VERSION ""

NS_ :

BS_:

BU_: CSC01 CSC02 CSC03 CSC04 CSC05 CSC06 CSC07 CSC08 CSC09 CSC10 CSC11 CSC12 CSC13 CSC14 CSC15

BO_ 2550726658 CSC09_CIDs_FAULTS: 8 CSC09
 SG_ IC4_IDLE_MODE_FLT m3 : 24|1@0+ (1,0) [0|0] "" Vector__XXX
 SG_ IC4_AN_OPEN_FLT m3 : 39|1@0+ (1,0) [0|0] "" Vector__XXX
 SG_ IC4_GPIO_SHORT_FLT m3 : 38|1@0+ (1,0) [0|0] "" Vector__XXX
 SG_ IC4_CB_SHORT_FLT m3 : 37|1@0+ (1,0) [0|0] "" Vector__XXX
 SG_ IC4_CB_OPEN_FLT m3 : 36|1@0+ (1,0) [0|0] "" Vector__XXX
 SG_ IC4_OSC_ERR_FLT m3 : 35|1@0+ (1,0) [0|0] "" Vector__XXX
 SG_ IC4_DED_ERR_FLT m3 : 34|1@0+ (1,0) [0|0] "" Vector__XXX
 SG_ IC4_FUSE_ERR_FLT m3 : 33|1@0+ (1,0) [0|0] "" Vector__XXX
 SG_ IC4_VCOM_OV_FLT m3 : 16|1@0+ (1,0) [0|0] "" Vector__XXX
 SG_ IC4_VCOM_UV_FLT m3 : 31|1@0+ (1,0) [0|0] "" Vector__XXX
 SG_ IC4_VANA_OV_FLT m3 : 30|1@0+ (1,0) [0|0] "" Vector__XXX
 SG_ IC4_VANA_UV_FLT m3 : 29|1@0+ (1,0) [0|0] "" Vector__XXX
 SG_ IC4_ADC1_B_FLT m3 : 28|1@0+ (1,0) [0|0] "" Vector__XXX
 SG_ IC4_ADC1_A_FLT m3 : 27|1@0+ (1,0) [0|0] "" Vector__XXX
 SG_ IC4_GND_LOSS_FLT m3 : 26|1@0+ (1,0) [0|0] "" Vector__XXX
 SG_ IC4_IC_TSD_FLT m3 : 25|1@0+ (1,0) [0|0] "" Vector__XXX
 SG_ IC4_GPIO0_WUP_FLT m3 : 23|1@0+ (1,0) [0|0] "" Vector__XXX
 SG_ IC4_IS_OL_FLT m3 : 22|1@0+ (1,0) [0|0] "" Vector__XXX
 SG_ IC4_IS_OC_FLT m3 : 21|1@0+ (1,0) [0|0] "" Vector__XXX
 SG_ IC4_AN_OT_FLT m3 : 20|1@0+ (1,0) [0|0] "" Vector__XXX
 SG_ IC4_AN_UT_FLT m3 : 19|1@0+ (1,0) [0|0] "" Vector__XXX
 SG_ IC4_CT_OV_FLT m3 : 18|1@0+ (1,0) [0|0] "" Vector__XXX
 SG_ IC4_CT_UV_FLT m3 : 17|1@0+ (1,0) [0|0] "" Vector__XXX
 SG_ IC4_POR m3 : 15|1@0+ (1,0) [0|0] "" Vector__XXX
 SG_ IC4_RESET_FLT m3 : 14|1@0+ (1,0) [0|0] "" Vector__XXX
 SG_ IC4_COM_ERR_OVR_FLT m3 : 13|1@0+ (1,0) [0|0] "" Vector__XXX
 SG_ IC4_VPWR_OV_FLT m3 : 12|1@0+ (1,0) [0|0] "" Vector__XXX
 SG_ IC4_VPWR_LV_FLT m3 : 11|1@0+ (1,0) [0|0] "" Vector__XXX
 SG_ IC4_COM_LOSS_FLT m3 : 10|1@0+ (1,0) [0|0] "" Vector__XXX
 SG_ IC4_COM_ERR_FLT m3 : 9|1@0+ (1,0) [0|0] "" Vector__XXX
 SG_ IC4_CSB_WUP_FLT m3 : 8|1@0+ (1,0) [0|0] "" Vector__XXX
 SG_ IC3_IDLE_MODE_FLT m2 : 24|1@0+ (1,0) [0|0] "" Vector__XXX
 SG_ IC3_AN_OPEN_FLT m2 : 39|1@0+ (1,0) [0|0] "" Vector__XXX
 SG_ IC3_GPIO_SHORT_FLT m2 : 38|1@0+ (1,0) [0|0] "" Vector__XXX
 SG_ IC3_CB_SHORT_FLT m2 : 37|1@0+ (1,0) [0|0] "" Vector__XXX
 SG_ IC3_CB_OPEN_FLT m2 : 36|1@0+ (1,0) [0|0] "" Vector__XXX
 SG_ IC3_OSC_ERR_FLT m2 : 35|1@0+ (1,0) [0|0] "" Vector__XXX
 SG_ IC3_DED_ERR_FLT m2 : 34|1@0+ (1,0) [0|0] "" Vector__XXX
 SG_ IC3_FUSE_ERR_FLT m2 : 33|1@0+ (1,0) [0|0] "" Vector__XXX
 SG_ IC3_VCOM_OV_FLT m2 : 16|1@0+ (1,0) [0|0] "" Vector__XXX
 SG_ IC3_VCOM_UV_FLT m2 : 31|1@0+ (1,0) [0|0] "" Vector__XXX
 SG_ IC3_VANA_OV_FLT m2 : 30|1@0+ (1,0) [0|0] "" Vector__XXX
 SG_ IC3_VANA_UV_FLT m2 : 29|1@0+ (1,0) [0|0] "" Vector__XXX
 SG_ IC3_ADC1_B_FLT m2 : 28|1@0+ (1,0) [0|0] "" Vector__XXX
 SG_ IC3_ADC1_A_FLT m2 : 27|1@0+ (1,0) [0|0] "" Vector__XXX
 SG_ IC3_GND_LOSS_FLT m2 : 26|1@0+ (1,0) [0|0] "" Vector__XXX
 SG_ IC3_IC_TSD_FLT m2 : 25|1@0+ (1,0) [0|0] "" Vector__XXX
 SG_ IC3_GPIO0_WUP_FLT m2 : 23|1@0+ (1,0) [0|0] "" Vector__XXX
 SG_ IC3_IS_OL_FLT m2 : 22|1@0+ (1,0) [0|0] "" Vector__XXX
 SG_ IC3_IS_OC_FLT m2 : 21|1@0+ (1,0) [0|0] "" Vector__XXX
 SG_ IC3_AN_OT_FLT m2 : 20|1@0+ (1,0) [0|0] "" Vector__XXX
 SG_ IC3_AN_UT_FLT m2 : 19|1@0+ (1,0) [0|0] "" Vector__XXX
 SG_ IC3_CT_OV_FLT m2 : 18|1@0+ (1,0) [0|0] "" Vector__XXX
 SG_ IC3_CT_UV_FLT m2 : 17|1@0+ (1,0) [0|0] "" Vector__XXX
 SG_ IC3_POR m2 : 15|1@0+ (1,0) [0|0] "" Vector__XXX
 SG_ IC3_RESET_FLT m2 : 14|1@0+ (1,0) [0|0] "" Vector__XXX
 SG_ IC3_COM_ERR_OVR_FLT m2 : 13|1@0+ (1,0) [0|0] "" Vector__XXX
 SG_ IC3_VPWR_OV_FLT m2 : 12|1@0+ (1,0) [0|0] "" Vector__XXX
 SG_ IC3_VPWR_LV_FLT m2 : 11|1@0+ (1,0) [0|0] "" Vector__XXX
 SG_ IC3_COM_LOSS_FLT m2 : 10|1@0+ (1,0) [0|0] "" Vector__XXX
 SG_ IC3_COM_ERR_FLT m2 : 9|1@0+ (1,0) [0|0] "" Vector__XXX
 SG_ IC3_CSB_WUP_FLT m2 : 8|1@0+ (1,0) [0|0] "" Vector__XXX
 SG_ IC2_IDLE_MODE_FLT m1 : 24|1@0+ (1,0) [0|0] "" Vector__XXX
 SG_ IC2_AN_OPEN_FLT m1 : 39|1@0+ (1,0) [0|0] "" Vector__XXX
 SG_ IC2_GPIO_SHORT_FLT m1 : 38|1@0+ (1,0) [0|0] "" Vector__XXX
 SG_ IC2_CB_SHORT_FLT m1 : 37|1@0+ (1,0) [0|0] "" Vector__XXX
 SG_ IC2_CB_OPEN_FLT m1 : 36|1@0+ (1,0) [0|0] "" Vector__XXX
 SG_ IC2_OSC_ERR_FLT m1 : 35|1@0+ (1,0) [0|0] "" Vector__XXX
 SG_ IC2_DED_ERR_FLT m1 : 34|1@0+ (1,0) [0|0] "" Vector__XXX
 SG_ IC2_FUSE_ERR_FLT m1 : 33|1@0+ (1,0) [0|0] "" Vector__XXX
 SG_ IC2_VCOM_OV_FLT m1 : 16|1@0+ (1,0) [0|0] "" Vector__XXX
 SG_ IC2_VCOM_UV_FLT m1 : 31|1@0+ (1,0) [0|0] "" Vector__XXX
 SG_ IC2_VANA_OV_FLT m1 : 30|1@0+ (1,0) [0|0] "" Vector__XXX
 SG_ IC2_VANA_UV_FLT m1 : 29|1@0+ (1,0) [0|0] "" Vector__XXX
 SG_ IC2_ADC1_B_FLT m1 : 28|1@0+ (1,0) [0|0] "" Vector__XXX
 SG_ IC2_ADC1_A_FLT m1 : 27|1@0+ (1,0) [0|0] "" Vector__XXX
 SG_ IC2_GND_LOSS_FLT m1 : 26|1@0+ (1,0) [0|0] "" Vector__XXX
 SG_ IC2_IC_TSD_FLT m1 : 25|1@0+ (1,0) [0|0] "" Vector__XXX
 SG_ IC2_GPIO0_WUP_FLT m1 : 23|1@0+ (1,0) [0|0] "" Vector__XXX
 SG_ IC2_IS_OL_FLT m1 : 22|1@0+ (1,0) [0|0] "" Vector__XXX
 SG_ IC2_IS_OC_FLT m1 : 21|1@0+ (1,0) [0|0] "" Vector__XXX
 SG_ IC2_AN_OT_FLT m1 : 20|1@0+ (1,0) [0|0] "" Vector__XXX
 SG_ IC2_AN_UT_FLT m1 : 19|1@0+ (1,0) [0|0] "" Vector__XXX
 SG_ IC2_CT_OV_FLT m1 : 18|1@0+ (1,0) [0|0] "" Vector__XXX
 SG_ IC2_CT_UV_FLT m1 : 17|1@0+ (1,0) [0|0] "" Vector__XXX
 SG_ IC2_POR m1 : 15|1@0+ (1,0) [0|0] "" Vector__XXX
 SG_ IC2_RESET_FLT m1 : 14|1@0+ (1,0) [0|0] "" Vector__XXX
 SG_ IC2_COM_ERR_OVR_FLT m1 : 13|1@0+ (1,0) [0|0] "" Vector__XXX
 SG_ IC2_VPWR_OV_FLT m1 : 12|1@0+ (1,0) [0|0] "" Vector__XXX
 SG_ IC2_VPWR_LV_FLT m1 : 11|1@0+ (1,0) [0|0] "" Vector__XXX
 SG_ IC2_COM_LOSS_FLT m1 : 10|1@0+ (1,0) [0|0] "" Vector__XXX
 SG_ IC2_COM_ERR_FLT m1 : 9|1@0+ (1,0) [0|0] "" Vector__XXX
 SG_ IC2_CSB_WUP_FLT m1 : 8|1@0+ (1,0) [0|0] "" Vector__XXX
 SG_ IC1_IDLE_MODE_FLT m0 : 24|1@0+ (1,0) [0|0] "" Vector__XXX
 SG_ IC1_AN_OPEN_FLT m0 : 39|1@0+ (1,0) [0|0] "" Vector__XXX
 SG_ IC1_GPIO_SHORT_FLT m0 : 38|1@0+ (1,0) [0|0] "" Vector__XXX
 SG_ IC1_CB_SHORT_FLT m0 : 37|1@0+ (1,0) [0|0] "" Vector__XXX
 SG_ IC1_CB_OPEN_FLT m0 : 36|1@0+ (1,0) [0|0] "" Vector__XXX
 SG_ IC1_OSC_ERR_FLT m0 : 35|1@0+ (1,0) [0|0] "" Vector__XXX
 SG_ IC1_DED_ERR_FLT m0 : 34|1@0+ (1,0) [0|0] "" Vector__XXX
 SG_ IC1_FUSE_ERR_FLT m0 : 33|1@0+ (1,0) [0|0] "" Vector__XXX
 SG_ IC1_VCOM_OV_FLT m0 : 16|1@0+ (1,0) [0|0] "" Vector__XXX
 SG_ IC1_VCOM_UV_FLT m0 : 31|1@0+ (1,0) [0|0] "" Vector__XXX
 SG_ IC1_VANA_OV_FLT m0 : 30|1@0+ (1,0) [0|0] "" Vector__XXX
 SG_ IC1_VANA_UV_FLT m0 : 29|1@0+ (1,0) [0|0] "" Vector__XXX
 SG_ IC1_ADC1_B_FLT m0 : 28|1@0+ (1,0) [0|0] "" Vector__XXX
 SG_ IC1_ADC1_A_FLT m0 : 27|1@0+ (1,0) [0|0] "" Vector__XXX
 SG_ IC1_GND_LOSS_FLT m0 : 26|1@0+ (1,0) [0|0] "" Vector__XXX
 SG_ IC1_IC_TSD_FLT m0 : 25|1@0+ (1,0) [0|0] "" Vector__XXX
 SG_ IC1_GPIO0_WUP_FLT m0 : 23|1@0+ (1,0) [0|0] "" Vector__XXX
 SG_ IC1_IS_OL_FLT m0 : 22|1@0+ (1,0) [0|0] "" Vector__XXX
 SG_ IC1_IS_OC_FLT m0 : 21|1@0+ (1,0) [0|0] "" Vector__XXX
 SG_ IC1_AN_OT_FLT m0 : 20|1@0+ (1,0) [0|0] "" Vector__XXX
 SG_ IC1_AN_UT_FLT m0 : 19|1@0+ (1,0) [0|0] "" Vector__XXX
 SG_ IC1_CT_OV_FLT m0 : 18|1@0+ (1,0) [0|0] "" Vector__XXX
 SG_ IC1_CT_UV_FLT m0 : 17|1@0+ (1,0) [0|0] "" Vector__XXX
 SG_ IC1_POR m0 : 15|1@0+ (1,0) [0|0] "" Vector__XXX
 SG_ IC1_RESET_FLT m0 : 14|1@0+ (1,0) [0|0] "" Vector__XXX
 SG_ IC1_COM_ERR_OVR_FLT m0 : 13|1@0+ (1,0) [0|0] "" Vector__XXX
 SG_ IC1_VPWR_OV_FLT m0 : 12|1@0+ (1,0) [0|0] "" Vector__XXX
 SG_ IC1_VPWR_LV_FLT m0 : 11|1@0+ (1,0) [0|0] "" Vector__XXX
 SG_ IC1_COM_LOSS_FLT m0 : 10|1@0+ (1,0) [0|0] "" Vector__XXX
 SG_ IC1_COM_ERR_FLT m0 : 9|1@0+ (1,0) [0|0] "" Vector__XXX
 SG_ IC1_CSB_WUP_FLT m0 : 8|1@0+ (1,0) [0|0] "" Vector__XXX
 SG_ CSC09_IndexFaults M : 7|8@0+ (1,0) [0|255] "" Vector__XXX

BO_ 2550792194 CSC10_CIDs_FAULTS: 8 CSC10
 SG_ IC4_IDLE_MODE_FLT m3 : 24|1@0+ (1,0) [0|0] "" Vector__XXX
 SG_ IC4_AN_OPEN_FLT m3 : 39|1@0+ (1,0) [0|0] "" Vector__XXX
 SG_ IC4_GPIO_SHORT_FLT m3 : 38|1@0+ (1,0) [0|0] "" Vector__XXX
 SG_ IC4_CB_SHORT_FLT m3 : 37|1@0+ (1,0) [0|0] "" Vector__XXX
 SG_ IC4_CB_OPEN_FLT m3 : 36|1@0+ (1,0) [0|0] "" Vector__XXX
 SG_ IC4_OSC_ERR_FLT m3 : 35|1@0+ (1,0) [0|0] "" Vector__XXX
 SG_ IC4_DED_ERR_FLT m3 : 34|1@0+ (1,0) [0|0] "" Vector__XXX
 SG_ IC4_FUSE_ERR_FLT m3 : 33|1@0+ (1,0) [0|0] "" Vector__XXX
 SG_ IC4_VCOM_OV_FLT m3 : 16|1@0+ (1,0) [0|0] "" Vector__XXX
 SG_ IC4_VCOM_UV_FLT m3 : 31|1@0+ (1,0) [0|0] "" Vector__XXX
 SG_ IC4_VANA_OV_FLT m3 : 30|1@0+ (1,0) [0|0] "" Vector__XXX
 SG_ IC4_VANA_UV_FLT m3 : 29|1@0+ (1,0) [0|0] "" Vector__XXX
 SG_ IC4_ADC1_B_FLT m3 : 28|1@0+ (1,0) [0|0] "" Vector__XXX
 SG_ IC4_ADC1_A_FLT m3 : 27|1@0+ (1,0) [0|0] "" Vector__XXX
 SG_ IC4_GND_LOSS_FLT m3 : 26|1@0+ (1,0) [0|0] "" Vector__XXX
 SG_ IC4_IC_TSD_FLT m3 : 25|1@0+ (1,0) [0|0] "" Vector__XXX
 SG_ IC4_GPIO0_WUP_FLT m3 : 23|1@0+ (1,0) [0|0] "" Vector__XXX
 SG_ IC4_IS_OL_FLT m3 : 22|1@0+ (1,0) [0|0] "" Vector__XXX
 SG_ IC4_IS_OC_FLT m3 : 21|1@0+ (1,0) [0|0] "" Vector__XXX
 SG_ IC4_AN_OT_FLT m3 : 20|1@0+ (1,0) [0|0] "" Vector__XXX
 SG_ IC4_AN_UT_FLT m3 : 19|1@0+ (1,0) [0|0] "" Vector__XXX
 SG_ IC4_CT_OV_FLT m3 : 18|1@0+ (1,0) [0|0] "" Vector__XXX
 SG_ IC4_CT_UV_FLT m3 : 17|1@0+ (1,0) [0|0] "" Vector__XXX
 SG_ IC4_POR m3 : 15|1@0+ (1,0) [0|0] "" Vector__XXX
 SG_ IC4_RESET_FLT m3 : 14|1@0+ (1,0) [0|0] "" Vector__XXX
 SG_ IC4_COM_ERR_OVR_FLT m3 : 13|1@0+ (1,0) [0|0] "" Vector__XXX
 SG_ IC4_VPWR_OV_FLT m3 : 12|1@0+ (1,0) [0|0] "" Vector__XXX
 SG_ IC4_VPWR_LV_FLT m3 : 11|1@0+ (1,0) [0|0] "" Vector__XXX
 SG_ IC4_COM_LOSS_FLT m3 : 10|1@0+ (1,0) [0|0] "" Vector__XXX
 SG_ IC4_COM_ERR_FLT m3 : 9|1@0+ (1,0) [0|0] "" Vector__XXX
 SG_ IC4_CSB_WUP_FLT m3 : 8|1@0+ (1,0) [0|0] "" Vector__XXX
 SG_ IC3_IDLE_MODE_FLT m2 : 24|1@0+ (1,0) [0|0] "" Vector__XXX
 SG_ IC3_AN_OPEN_FLT m2 : 39|1@0+ (1,0) [0|0] "" Vector__XXX
 SG_ IC3_GPIO_SHORT_FLT m2 : 38|1@0+ (1,0) [0|0] "" Vector__XXX
 SG_ IC3_CB_SHORT_FLT m2 : 37|1@0+ (1,0) [0|0] "" Vector__XXX
 SG_ IC3_CB_OPEN_FLT m2 : 36|1@0+ (1,0) [0|0] "" Vector__XXX
 SG_ IC3_OSC_ERR_FLT m2 : 35|1@0+ (1,0) [0|0] "" Vector__XXX
 SG_ IC3_DED_ERR_FLT m2 : 34|1@0+ (1,0) [0|0] "" Vector__XXX
 SG_ IC3_FUSE_ERR_FLT m2 : 33|1@0+ (1,0) [0|0] "" Vector__XXX
 SG_ IC3_VCOM_OV_FLT m2 : 16|1@0+ (1,0) [0|0] "" Vector__XXX
 SG_ IC3_VCOM_UV_FLT m2 : 31|1@0+ (1,0) [0|0] "" Vector__XXX
 SG_ IC3_VANA_OV_FLT m2 : 30|1@0+ (1,0) [0|0] "" Vector__XXX
 SG_ IC3_VANA_UV_FLT m2 : 29|1@0+ (1,0) [0|0] "" Vector__XXX
 SG_ IC3_ADC1_B_FLT m2 : 28|1@0+ (1,0) [0|0] "" Vector__XXX
 SG_ IC3_ADC1_A_FLT m2 : 27|1@0+ (1,0) [0|0] "" Vector__XXX
 SG_ IC3_GND_LOSS_FLT m2 : 26|1@0+ (1,0) [0|0] "" Vector__XXX
 SG_ IC3_IC_TSD_FLT m2 : 25|1@0+ (1,0) [0|0] "" Vector__XXX
 SG_ IC3_GPIO0_WUP_FLT m2 : 23|1@0+ (1,0) [0|0] "" Vector__XXX
 SG_ IC3_IS_OL_FLT m2 : 22|1@0+ (1,0) [0|0] "" Vector__XXX
 SG_ IC3_IS_OC_FLT m2 : 21|1@0+ (1,0) [0|0] "" Vector__XXX
 SG_ IC3_AN_OT_FLT m2 : 20|1@0+ (1,0) [0|0] "" Vector__XXX
 SG_ IC3_AN_UT_FLT m2 : 19|1@0+ (1,0) [0|0] "" Vector__XXX
 SG_ IC3_CT_OV_FLT m2 : 18|1@0+ (1,0) [0|0] "" Vector__XXX
 SG_ IC3_CT_UV_FLT m2 : 17|1@0+ (1,0) [0|0] "" Vector__XXX
 SG_ IC3_POR m2 : 15|1@0+ (1,0) [0|0] "" Vector__XXX
 SG_ IC3_RESET_FLT m2 : 14|1@0+ (1,0) [0|0] "" Vector__XXX
 SG_ IC3_COM_ERR_OVR_FLT m2 : 13|1@0+ (1,0) [0|0] "" Vector__XXX
 SG_ IC3_VPWR_OV_FLT m2 : 12|1@0+ (1,0) [0|0] "" Vector__XXX
 SG_ IC3_VPWR_LV_FLT m2 : 11|1@0+ (1,0) [0|0] "" Vector__XXX
 SG_ IC3_COM_LOSS_FLT m2 : 10|1@0+ (1,0) [0|0] "" Vector__XXX
 SG_ IC3_COM_ERR_FLT m2 : 9|1@0+ (1,0) [0|0] "" Vector__XXX
 SG_ IC3_CSB_WUP_FLT m2 : 8|1@0+ (1,0) [0|0] "" Vector__XXX
 SG_ IC2_IDLE_MODE_FLT m1 : 24|1@0+ (1,0) [0|0] "" Vector__XXX
 SG_ IC2_AN_OPEN_FLT m1 : 39|1@0+ (1,0) [0|0] "" Vector__XXX
 SG_ IC2_GPIO_SHORT_FLT m1 : 38|1@0+ (1,0) [0|0] "" Vector__XXX
 SG_ IC2_CB_SHORT_FLT m1 : 37|1@0+ (1,0) [0|0] "" Vector__XXX
 SG_ IC2_CB_OPEN_FLT m1 : 36|1@0+ (1,0) [0|0] "" Vector__XXX
 SG_ IC2_OSC_ERR_FLT m1 : 35|1@0+ (1,0) [0|0] "" Vector__XXX
 SG_ IC2_DED_ERR_FLT m1 : 34|1@0+ (1,0) [0|0] "" Vector__XXX
 SG_ IC2_FUSE_ERR_FLT m1 : 33|1@0+ (1,0) [0|0] "" Vector__XXX
 SG_ IC2_VCOM_OV_FLT m1 : 16|1@0+ (1,0) [0|0] "" Vector__XXX
 SG_ IC2_VCOM_UV_FLT m1 : 31|1@0+ (1,0) [0|0] "" Vector__XXX
 SG_ IC2_VANA_OV_FLT m1 : 30|1@0+ (1,0) [0|0] "" Vector__XXX
 SG_ IC2_VANA_UV_FLT m1 : 29|1@0+ (1,0) [0|0] "" Vector__XXX
 SG_ IC2_ADC1_B_FLT m1 : 28|1@0+ (1,0) [0|0] "" Vector__XXX
 SG_ IC2_ADC1_A_FLT m1 : 27|1@0+ (1,0) [0|0] "" Vector__XXX
 SG_ IC2_GND_LOSS_FLT m1 : 26|1@0+ (1,0) [0|0] "" Vector__XXX
 SG_ IC2_IC_TSD_FLT m1 : 25|1@0+ (1,0) [0|0] "" Vector__XXX
 SG_ IC2_GPIO0_WUP_FLT m1 : 23|1@0+ (1,0) [0|0] "" Vector__XXX
 SG_ IC2_IS_OL_FLT m1 : 22|1@0+ (1,0) [0|0] "" Vector__XXX
 SG_ IC2_IS_OC_FLT m1 : 21|1@0+ (1,0) [0|0] "" Vector__XXX
 SG_ IC2_AN_OT_FLT m1 : 20|1@0+ (1,0) [0|0] "" Vector__XXX
 SG_ IC2_AN_UT_FLT m1 : 19|1@0+ (1,0) [0|0] "" Vector__XXX
 SG_ IC2_CT_OV_FLT m1 : 18|1@0+ (1,0) [0|0] "" Vector__XXX
 SG_ IC2_CT_UV_FLT m1 : 17|1@0+ (1,0) [0|0] "" Vector__XXX
 SG_ IC2_POR m1 : 15|1@0+ (1,0) [0|0] "" Vector__XXX
 SG_ IC2_RESET_FLT m1 : 14|1@0+ (1,0) [0|0] "" Vector__XXX
 SG_ IC2_COM_ERR_OVR_FLT m1 : 13|1@0+ (1,0) [0|0] "" Vector__XXX
 SG_ IC2_VPWR_OV_FLT m1 : 12|1@0+ (1,0) [0|0] "" Vector__XXX
 SG_ IC2_VPWR_LV_FLT m1 : 11|1@0+ (1,0) [0|0] "" Vector__XXX
 SG_ IC2_COM_LOSS_FLT m1 : 10|1@0+ (1,0) [0|0] "" Vector__XXX
 SG_ IC2_COM_ERR_FLT m1 : 9|1@0+ (1,0) [0|0] "" Vector__XXX
 SG_ IC2_CSB_WUP_FLT m1 : 8|1@0+ (1,0) [0|0] "" Vector__XXX
 SG_ IC1_IDLE_MODE_FLT m0 : 24|1@0+ (1,0) [0|0] "" Vector__XXX
 SG_ IC1_AN_OPEN_FLT m0 : 39|1@0+ (1,0) [0|0] "" Vector__XXX
 SG_ IC1_GPIO_SHORT_FLT m0 : 38|1@0+ (1,0) [0|0] "" Vector__XXX
 SG_ IC1_CB_SHORT_FLT m0 : 37|1@0+ (1,0) [0|0] "" Vector__XXX
 SG_ IC1_CB_OPEN_FLT m0 : 36|1@0+ (1,0) [0|0] "" Vector__XXX
 SG_ IC1_OSC_ERR_FLT m0 : 35|1@0+ (1,0) [0|0] "" Vector__XXX
 SG_ IC1_DED_ERR_FLT m0 : 34|1@0+ (1,0) [0|0] "" Vector__XXX
 SG_ IC1_FUSE_ERR_FLT m0 : 33|1@0+ (1,0) [0|0] "" Vector__XXX
 SG_ IC1_VCOM_OV_FLT m0 : 16|1@0+ (1,0) [0|0] "" Vector__XXX
 SG_ IC1_VCOM_UV_FLT m0 : 31|1@0+ (1,0) [0|0] "" Vector__XXX
 SG_ IC1_VANA_OV_FLT m0 : 30|1@0+ (1,0) [0|0] "" Vector__XXX
 SG_ IC1_VANA_UV_FLT m0 : 29|1@0+ (1,0) [0|0] "" Vector__XXX
 SG_ IC1_ADC1_B_FLT m0 : 28|1@0+ (1,0) [0|0] "" Vector__XXX
 SG_ IC1_ADC1_A_FLT m0 : 27|1@0+ (1,0) [0|0] "" Vector__XXX
 SG_ IC1_GND_LOSS_FLT m0 : 26|1@0+ (1,0) [0|0] "" Vector__XXX
 SG_ IC1_IC_TSD_FLT m0 : 25|1@0+ (1,0) [0|0] "" Vector__XXX
 SG_ IC1_GPIO0_WUP_FLT m0 : 23|1@0+ (1,0) [0|0] "" Vector__XXX
 SG_ IC1_IS_OL_FLT m0 : 22|1@0+ (1,0) [0|0] "" Vector__XXX
 SG_ IC1_IS_OC_FLT m0 : 21|1@0+ (1,0) [0|0] "" Vector__XXX
 SG_ IC1_AN_OT_FLT m0 : 20|1@0+ (1,0) [0|0] "" Vector__XXX
 SG_ IC1_AN_UT_FLT m0 : 19|1@0+ (1,0) [0|0] "" Vector__XXX
 SG_ IC1_CT_OV_FLT m0 : 18|1@0+ (1,0) [0|0] "" Vector__XXX
 SG_ IC1_CT_UV_FLT m0 : 17|1@0+ (1,0) [0|0] "" Vector__XXX
 SG_ IC1_POR m0 : 15|1@0+ (1,0) [0|0] "" Vector__XXX
 SG_ IC1_RESET_FLT m0 : 14|1@0+ (1,0) [0|0] "" Vector__XXX
 SG_ IC1_COM_ERR_OVR_FLT m0 : 13|1@0+ (1,0) [0|0] "" Vector__XXX
 SG_ IC1_VPWR_OV_FLT m0 : 12|1@0+ (1,0) [0|0] "" Vector__XXX
 SG_ IC1_VPWR_LV_FLT m0 : 11|1@0+ (1,0) [0|0] "" Vector__XXX
 SG_ IC1_COM_LOSS_FLT m0 : 10|1@0+ (1,0) [0|0] "" Vector__XXX
 SG_ IC1_COM_ERR_FLT m0 : 9|1@0+ (1,0) [0|0] "" Vector__XXX
 SG_ IC1_CSB_WUP_FLT m0 : 8|1@0+ (1,0) [0|0] "" Vector__XXX
 SG_ CSC10_IndexFaults M : 7|8@0+ (1,0) [0|255] "" Vector__XXX

BO_ 2550857730 CSC11_CIDs_FAULTS: 8 CSC11
 SG_ IC4_IDLE_MODE_FLT m3 : 24|1@0+ (1,0) [0|0] "" Vector__XXX
 SG_ IC4_AN_OPEN_FLT m3 : 39|1@0+ (1,0) [0|0] "" Vector__XXX
 SG_ IC4_GPIO_SHORT_FLT m3 : 38|1@0+ (1,0) [0|0] "" Vector__XXX
 SG_ IC4_CB_SHORT_FLT m3 : 37|1@0+ (1,0) [0|0] "" Vector__XXX
 SG_ IC4_CB_OPEN_FLT m3 : 36|1@0+ (1,0) [0|0] "" Vector__XXX
 SG_ IC4_OSC_ERR_FLT m3 : 35|1@0+ (1,0) [0|0] "" Vector__XXX
 SG_ IC4_DED_ERR_FLT m3 : 34|1@0+ (1,0) [0|0] "" Vector__XXX
 SG_ IC4_FUSE_ERR_FLT m3 : 33|1@0+ (1,0) [0|0] "" Vector__XXX
 SG_ IC4_VCOM_OV_FLT m3 : 16|1@0+ (1,0) [0|0] "" Vector__XXX
 SG_ IC4_VCOM_UV_FLT m3 : 31|1@0+ (1,0) [0|0] "" Vector__XXX
 SG_ IC4_VANA_OV_FLT m3 : 30|1@0+ (1,0) [0|0] "" Vector__XXX
 SG_ IC4_VANA_UV_FLT m3 : 29|1@0+ (1,0) [0|0] "" Vector__XXX
 SG_ IC4_ADC1_B_FLT m3 : 28|1@0+ (1,0) [0|0] "" Vector__XXX
 SG_ IC4_ADC1_A_FLT m3 : 27|1@0+ (1,0) [0|0] "" Vector__XXX
 SG_ IC4_GND_LOSS_FLT m3 : 26|1@0+ (1,0) [0|0] "" Vector__XXX
 SG_ IC4_IC_TSD_FLT m3 : 25|1@0+ (1,0) [0|0] "" Vector__XXX
 SG_ IC4_GPIO0_WUP_FLT m3 : 23|1@0+ (1,0) [0|0] "" Vector__XXX
 SG_ IC4_IS_OL_FLT m3 : 22|1@0+ (1,0) [0|0] "" Vector__XXX
 SG_ IC4_IS_OC_FLT m3 : 21|1@0+ (1,0) [0|0] "" Vector__XXX
 SG_ IC4_AN_OT_FLT m3 : 20|1@0+ (1,0) [0|0] "" Vector__XXX
 SG_ IC4_AN_UT_FLT m3 : 19|1@0+ (1,0) [0|0] "" Vector__XXX
 SG_ IC4_CT_OV_FLT m3 : 18|1@0+ (1,0) [0|0] "" Vector__XXX
 SG_ IC4_CT_UV_FLT m3 : 17|1@0+ (1,0) [0|0] "" Vector__XXX
 SG_ IC4_POR m3 : 15|1@0+ (1,0) [0|0] "" Vector__XXX
 SG_ IC4_RESET_FLT m3 : 14|1@0+ (1,0) [0|0] "" Vector__XXX
 SG_ IC4_COM_ERR_OVR_FLT m3 : 13|1@0+ (1,0) [0|0] "" Vector__XXX
 SG_ IC4_VPWR_OV_FLT m3 : 12|1@0+ (1,0) [0|0] "" Vector__XXX
 SG_ IC4_VPWR_LV_FLT m3 : 11|1@0+ (1,0) [0|0] "" Vector__XXX
 SG_ IC4_COM_LOSS_FLT m3 : 10|1@0+ (1,0) [0|0] "" Vector__XXX
 SG_ IC4_COM_ERR_FLT m3 : 9|1@0+ (1,0) [0|0] "" Vector__XXX
 SG_ IC4_CSB_WUP_FLT m3 : 8|1@0+ (1,0) [0|0] "" Vector__XXX
 SG_ IC3_IDLE_MODE_FLT m2 : 24|1@0+ (1,0) [0|0] "" Vector__XXX
 SG_ IC3_AN_OPEN_FLT m2 : 39|1@0+ (1,0) [0|0] "" Vector__XXX
 SG_ IC3_GPIO_SHORT_FLT m2 : 38|1@0+ (1,0) [0|0] "" Vector__XXX
 SG_ IC3_CB_SHORT_FLT m2 : 37|1@0+ (1,0) [0|0] "" Vector__XXX
 SG_ IC3_CB_OPEN_FLT m2 : 36|1@0+ (1,0) [0|0] "" Vector__XXX
 SG_ IC3_OSC_ERR_FLT m2 : 35|1@0+ (1,0) [0|0] "" Vector__XXX
 SG_ IC3_DED_ERR_FLT m2 : 34|1@0+ (1,0) [0|0] "" Vector__XXX
 SG_ IC3_FUSE_ERR_FLT m2 : 33|1@0+ (1,0) [0|0] "" Vector__XXX
 SG_ IC3_VCOM_OV_FLT m2 : 16|1@0+ (1,0) [0|0] "" Vector__XXX
 SG_ IC3_VCOM_UV_FLT m2 : 31|1@0+ (1,0) [0|0] "" Vector__XXX
 SG_ IC3_VANA_OV_FLT m2 : 30|1@0+ (1,0) [0|0] "" Vector__XXX
 SG_ IC3_VANA_UV_FLT m2 : 29|1@0+ (1,0) [0|0] "" Vector__XXX
 SG_ IC3_ADC1_B_FLT m2 : 28|1@0+ (1,0) [0|0] "" Vector__XXX
 SG_ IC3_ADC1_A_FLT m2 : 27|1@0+ (1,0) [0|0] "" Vector__XXX
 SG_ IC3_GND_LOSS_FLT m2 : 26|1@0+ (1,0) [0|0] "" Vector__XXX
 SG_ IC3_IC_TSD_FLT m2 : 25|1@0+ (1,0) [0|0] "" Vector__XXX
 SG_ IC3_GPIO0_WUP_FLT m2 : 23|1@0+ (1,0) [0|0] "" Vector__XXX
 SG_ IC3_IS_OL_FLT m2 : 22|1@0+ (1,0) [0|0] "" Vector__XXX
 SG_ IC3_IS_OC_FLT m2 : 21|1@0+ (1,0) [0|0] "" Vector__XXX
 SG_ IC3_AN_OT_FLT m2 : 20|1@0+ (1,0) [0|0] "" Vector__XXX
 SG_ IC3_AN_UT_FLT m2 : 19|1@0+ (1,0) [0|0] "" Vector__XXX
 SG_ IC3_CT_OV_FLT m2 : 18|1@0+ (1,0) [0|0] "" Vector__XXX
 SG_ IC3_CT_UV_FLT m2 : 17|1@0+ (1,0) [0|0] "" Vector__XXX
 SG_ IC3_POR m2 : 15|1@0+ (1,0) [0|0] "" Vector__XXX
 SG_ IC3_RESET_FLT m2 : 14|1@0+ (1,0) [0|0] "" Vector__XXX
 SG_ IC3_COM_ERR_OVR_FLT m2 : 13|1@0+ (1,0) [0|0] "" Vector__XXX
 SG_ IC3_VPWR_OV_FLT m2 : 12|1@0+ (1,0) [0|0] "" Vector__XXX
 SG_ IC3_VPWR_LV_FLT m2 : 11|1@0+ (1,0) [0|0] "" Vector__XXX
 SG_ IC3_COM_LOSS_FLT m2 : 10|1@0+ (1,0) [0|0] "" Vector__XXX
 SG_ IC3_COM_ERR_FLT m2 : 9|1@0+ (1,0) [0|0] "" Vector__XXX
 SG_ IC3_CSB_WUP_FLT m2 : 8|1@0+ (1,0) [0|0] "" Vector__XXX
 SG_ IC2_IDLE_MODE_FLT m1 : 24|1@0+ (1,0) [0|0] "" Vector__XXX
 SG_ IC2_AN_OPEN_FLT m1 : 39|1@0+ (1,0) [0|0] "" Vector__XXX
 SG_ IC2_GPIO_SHORT_FLT m1 : 38|1@0+ (1,0) [0|0] "" Vector__XXX
 SG_ IC2_CB_SHORT_FLT m1 : 37|1@0+ (1,0) [0|0] "" Vector__XXX
 SG_ IC2_CB_OPEN_FLT m1 : 36|1@0+ (1,0) [0|0] "" Vector__XXX
 SG_ IC2_OSC_ERR_FLT m1 : 35|1@0+ (1,0) [0|0] "" Vector__XXX
 SG_ IC2_DED_ERR_FLT m1 : 34|1@0+ (1,0) [0|0] "" Vector__XXX
 SG_ IC2_FUSE_ERR_FLT m1 : 33|1@0+ (1,0) [0|0] "" Vector__XXX
 SG_ IC2_VCOM_OV_FLT m1 : 16|1@0+ (1,0) [0|0] "" Vector__XXX
 SG_ IC2_VCOM_UV_FLT m1 : 31|1@0+ (1,0) [0|0] "" Vector__XXX
 SG_ IC2_VANA_OV_FLT m1 : 30|1@0+ (1,0) [0|0] "" Vector__XXX
 SG_ IC2_VANA_UV_FLT m1 : 29|1@0+ (1,0) [0|0] "" Vector__XXX
 SG_ IC2_ADC1_B_FLT m1 : 28|1@0+ (1,0) [0|0] "" Vector__XXX
 SG_ IC2_ADC1_A_FLT m1 : 27|1@0+ (1,0) [0|0] "" Vector__XXX
 SG_ IC2_GND_LOSS_FLT m1 : 26|1@0+ (1,0) [0|0] "" Vector__XXX
 SG_ IC2_IC_TSD_FLT m1 : 25|1@0+ (1,0) [0|0] "" Vector__XXX
 SG_ IC2_GPIO0_WUP_FLT m1 : 23|1@0+ (1,0) [0|0] "" Vector__XXX
 SG_ IC2_IS_OL_FLT m1 : 22|1@0+ (1,0) [0|0] "" Vector__XXX
 SG_ IC2_IS_OC_FLT m1 : 21|1@0+ (1,0) [0|0] "" Vector__XXX
 SG_ IC2_AN_OT_FLT m1 : 20|1@0+ (1,0) [0|0] "" Vector__XXX
 SG_ IC2_AN_UT_FLT m1 : 19|1@0+ (1,0) [0|0] "" Vector__XXX
 SG_ IC2_CT_OV_FLT m1 : 18|1@0+ (1,0) [0|0] "" Vector__XXX
 SG_ IC2_CT_UV_FLT m1 : 17|1@0+ (1,0) [0|0] "" Vector__XXX
 SG_ IC2_POR m1 : 15|1@0+ (1,0) [0|0] "" Vector__XXX
 SG_ IC2_RESET_FLT m1 : 14|1@0+ (1,0) [0|0] "" Vector__XXX
 SG_ IC2_COM_ERR_OVR_FLT m1 : 13|1@0+ (1,0) [0|0] "" Vector__XXX
 SG_ IC2_VPWR_OV_FLT m1 : 12|1@0+ (1,0) [0|0] "" Vector__XXX
 SG_ IC2_VPWR_LV_FLT m1 : 11|1@0+ (1,0) [0|0] "" Vector__XXX
 SG_ IC2_COM_LOSS_FLT m1 : 10|1@0+ (1,0) [0|0] "" Vector__XXX
 SG_ IC2_COM_ERR_FLT m1 : 9|1@0+ (1,0) [0|0] "" Vector__XXX
 SG_ IC2_CSB_WUP_FLT m1 : 8|1@0+ (1,0) [0|0] "" Vector__XXX
 SG_ IC1_IDLE_MODE_FLT m0 : 24|1@0+ (1,0) [0|0] "" Vector__XXX
 SG_ IC1_AN_OPEN_FLT m0 : 39|1@0+ (1,0) [0|0] "" Vector__XXX
 SG_ IC1_GPIO_SHORT_FLT m0 : 38|1@0+ (1,0) [0|0] "" Vector__XXX
 SG_ IC1_CB_SHORT_FLT m0 : 37|1@0+ (1,0) [0|0] "" Vector__XXX
 SG_ IC1_CB_OPEN_FLT m0 : 36|1@0+ (1,0) [0|0] "" Vector__XXX
 SG_ IC1_OSC_ERR_FLT m0 : 35|1@0+ (1,0) [0|0] "" Vector__XXX
 SG_ IC1_DED_ERR_FLT m0 : 34|1@0+ (1,0) [0|0] "" Vector__XXX
 SG_ IC1_FUSE_ERR_FLT m0 : 33|1@0+ (1,0) [0|0] "" Vector__XXX
 SG_ IC1_VCOM_OV_FLT m0 : 16|1@0+ (1,0) [0|0] "" Vector__XXX
 SG_ IC1_VCOM_UV_FLT m0 : 31|1@0+ (1,0) [0|0] "" Vector__XXX
 SG_ IC1_VANA_OV_FLT m0 : 30|1@0+ (1,0) [0|0] "" Vector__XXX
 SG_ IC1_VANA_UV_FLT m0 : 29|1@0+ (1,0) [0|0] "" Vector__XXX
 SG_ IC1_ADC1_B_FLT m0 : 28|1@0+ (1,0) [0|0] "" Vector__XXX
 SG_ IC1_ADC1_A_FLT m0 : 27|1@0+ (1,0) [0|0] "" Vector__XXX
 SG_ IC1_GND_LOSS_FLT m0 : 26|1@0+ (1,0) [0|0] "" Vector__XXX
 SG_ IC1_IC_TSD_FLT m0 : 25|1@0+ (1,0) [0|0] "" Vector__XXX
 SG_ IC1_GPIO0_WUP_FLT m0 : 23|1@0+ (1,0) [0|0] "" Vector__XXX
 SG_ IC1_IS_OL_FLT m0 : 22|1@0+ (1,0) [0|0] "" Vector__XXX
 SG_ IC1_IS_OC_FLT m0 : 21|1@0+ (1,0) [0|0] "" Vector__XXX
 SG_ IC1_AN_OT_FLT m0 : 20|1@0+ (1,0) [0|0] "" Vector__XXX
 SG_ IC1_AN_UT_FLT m0 : 19|1@0+ (1,0) [0|0] "" Vector__XXX
 SG_ IC1_CT_OV_FLT m0 : 18|1@0+ (1,0) [0|0] "" Vector__XXX
 SG_ IC1_CT_UV_FLT m0 : 17|1@0+ (1,0) [0|0] "" Vector__XXX
 SG_ IC1_POR m0 : 15|1@0+ (1,0) [0|0] "" Vector__XXX
 SG_ IC1_RESET_FLT m0 : 14|1@0+ (1,0) [0|0] "" Vector__XXX
 SG_ IC1_COM_ERR_OVR_FLT m0 : 13|1@0+ (1,0) [0|0] "" Vector__XXX
 SG_ IC1_VPWR_OV_FLT m0 : 12|1@0+ (1,0) [0|0] "" Vector__XXX
 SG_ IC1_VPWR_LV_FLT m0 : 11|1@0+ (1,0) [0|0] "" Vector__XXX
 SG_ IC1_COM_LOSS_FLT m0 : 10|1@0+ (1,0) [0|0] "" Vector__XXX
 SG_ IC1_COM_ERR_FLT m0 : 9|1@0+ (1,0) [0|0] "" Vector__XXX
 SG_ IC1_CSB_WUP_FLT m0 : 8|1@0+ (1,0) [0|0] "" Vector__XXX
 SG_ CSC11_IndexFaults M : 7|8@0+ (1,0) [0|255] "" Vector__XXX

BO_ 2550923266 CSC12_CIDs_FAULTS: 8 CSC12
 SG_ IC4_IDLE_MODE_FLT m3 : 24|1@0+ (1,0) [0|0] "" Vector__XXX
 SG_ IC4_AN_OPEN_FLT m3 : 39|1@0+ (1,0) [0|0] "" Vector__XXX
 SG_ IC4_GPIO_SHORT_FLT m3 : 38|1@0+ (1,0) [0|0] "" Vector__XXX
 SG_ IC4_CB_SHORT_FLT m3 : 37|1@0+ (1,0) [0|0] "" Vector__XXX
 SG_ IC4_CB_OPEN_FLT m3 : 36|1@0+ (1,0) [0|0] "" Vector__XXX
 SG_ IC4_OSC_ERR_FLT m3 : 35|1@0+ (1,0) [0|0] "" Vector__XXX
 SG_ IC4_DED_ERR_FLT m3 : 34|1@0+ (1,0) [0|0] "" Vector__XXX
 SG_ IC4_FUSE_ERR_FLT m3 : 33|1@0+ (1,0) [0|0] "" Vector__XXX
 SG_ IC4_VCOM_OV_FLT m3 : 16|1@0+ (1,0) [0|0] "" Vector__XXX
 SG_ IC4_VCOM_UV_FLT m3 : 31|1@0+ (1,0) [0|0] "" Vector__XXX
 SG_ IC4_VANA_OV_FLT m3 : 30|1@0+ (1,0) [0|0] "" Vector__XXX
 SG_ IC4_VANA_UV_FLT m3 : 29|1@0+ (1,0) [0|0] "" Vector__XXX
 SG_ IC4_ADC1_B_FLT m3 : 28|1@0+ (1,0) [0|0] "" Vector__XXX
 SG_ IC4_ADC1_A_FLT m3 : 27|1@0+ (1,0) [0|0] "" Vector__XXX
 SG_ IC4_GND_LOSS_FLT m3 : 26|1@0+ (1,0) [0|0] "" Vector__XXX
 SG_ IC4_IC_TSD_FLT m3 : 25|1@0+ (1,0) [0|0] "" Vector__XXX
 SG_ IC4_GPIO0_WUP_FLT m3 : 23|1@0+ (1,0) [0|0] "" Vector__XXX
 SG_ IC4_IS_OL_FLT m3 : 22|1@0+ (1,0) [0|0] "" Vector__XXX
 SG_ IC4_IS_OC_FLT m3 : 21|1@0+ (1,0) [0|0] "" Vector__XXX
 SG_ IC4_AN_OT_FLT m3 : 20|1@0+ (1,0) [0|0] "" Vector__XXX
 SG_ IC4_AN_UT_FLT m3 : 19|1@0+ (1,0) [0|0] "" Vector__XXX
 SG_ IC4_CT_OV_FLT m3 : 18|1@0+ (1,0) [0|0] "" Vector__XXX
 SG_ IC4_CT_UV_FLT m3 : 17|1@0+ (1,0) [0|0] "" Vector__XXX
 SG_ IC4_POR m3 : 15|1@0+ (1,0) [0|0] "" Vector__XXX
 SG_ IC4_RESET_FLT m3 : 14|1@0+ (1,0) [0|0] "" Vector__XXX
 SG_ IC4_COM_ERR_OVR_FLT m3 : 13|1@0+ (1,0) [0|0] "" Vector__XXX
 SG_ IC4_VPWR_OV_FLT m3 : 12|1@0+ (1,0) [0|0] "" Vector__XXX
 SG_ IC4_VPWR_LV_FLT m3 : 11|1@0+ (1,0) [0|0] "" Vector__XXX
 SG_ IC4_COM_LOSS_FLT m3 : 10|1@0+ (1,0) [0|0] "" Vector__XXX
 SG_ IC4_COM_ERR_FLT m3 : 9|1@0+ (1,0) [0|0] "" Vector__XXX
 SG_ IC4_CSB_WUP_FLT m3 : 8|1@0+ (1,0) [0|0] "" Vector__XXX
 SG_ IC3_IDLE_MODE_FLT m2 : 24|1@0+ (1,0) [0|0] "" Vector__XXX
 SG_ IC3_AN_OPEN_FLT m2 : 39|1@0+ (1,0) [0|0] "" Vector__XXX
 SG_ IC3_GPIO_SHORT_FLT m2 : 38|1@0+ (1,0) [0|0] "" Vector__XXX
 SG_ IC3_CB_SHORT_FLT m2 : 37|1@0+ (1,0) [0|0] "" Vector__XXX
 SG_ IC3_CB_OPEN_FLT m2 : 36|1@0+ (1,0) [0|0] "" Vector__XXX
 SG_ IC3_OSC_ERR_FLT m2 : 35|1@0+ (1,0) [0|0] "" Vector__XXX
 SG_ IC3_DED_ERR_FLT m2 : 34|1@0+ (1,0) [0|0] "" Vector__XXX
 SG_ IC3_FUSE_ERR_FLT m2 : 33|1@0+ (1,0) [0|0] "" Vector__XXX
 SG_ IC3_VCOM_OV_FLT m2 : 16|1@0+ (1,0) [0|0] "" Vector__XXX
 SG_ IC3_VCOM_UV_FLT m2 : 31|1@0+ (1,0) [0|0] "" Vector__XXX
 SG_ IC3_VANA_OV_FLT m2 : 30|1@0+ (1,0) [0|0] "" Vector__XXX
 SG_ IC3_VANA_UV_FLT m2 : 29|1@0+ (1,0) [0|0] "" Vector__XXX
 SG_ IC3_ADC1_B_FLT m2 : 28|1@0+ (1,0) [0|0] "" Vector__XXX
 SG_ IC3_ADC1_A_FLT m2 : 27|1@0+ (1,0) [0|0] "" Vector__XXX
 SG_ IC3_GND_LOSS_FLT m2 : 26|1@0+ (1,0) [0|0] "" Vector__XXX
 SG_ IC3_IC_TSD_FLT m2 : 25|1@0+ (1,0) [0|0] "" Vector__XXX
 SG_ IC3_GPIO0_WUP_FLT m2 : 23|1@0+ (1,0) [0|0] "" Vector__XXX
 SG_ IC3_IS_OL_FLT m2 : 22|1@0+ (1,0) [0|0] "" Vector__XXX
 SG_ IC3_IS_OC_FLT m2 : 21|1@0+ (1,0) [0|0] "" Vector__XXX
 SG_ IC3_AN_OT_FLT m2 : 20|1@0+ (1,0) [0|0] "" Vector__XXX
 SG_ IC3_AN_UT_FLT m2 : 19|1@0+ (1,0) [0|0] "" Vector__XXX
 SG_ IC3_CT_OV_FLT m2 : 18|1@0+ (1,0) [0|0] "" Vector__XXX
 SG_ IC3_CT_UV_FLT m2 : 17|1@0+ (1,0) [0|0] "" Vector__XXX
 SG_ IC3_POR m2 : 15|1@0+ (1,0) [0|0] "" Vector__XXX
 SG_ IC3_RESET_FLT m2 : 14|1@0+ (1,0) [0|0] "" Vector__XXX
 SG_ IC3_COM_ERR_OVR_FLT m2 : 13|1@0+ (1,0) [0|0] "" Vector__XXX
 SG_ IC3_VPWR_OV_FLT m2 : 12|1@0+ (1,0) [0|0] "" Vector__XXX
 SG_ IC3_VPWR_LV_FLT m2 : 11|1@0+ (1,0) [0|0] "" Vector__XXX
 SG_ IC3_COM_LOSS_FLT m2 : 10|1@0+ (1,0) [0|0] "" Vector__XXX
 SG_ IC3_COM_ERR_FLT m2 : 9|1@0+ (1,0) [0|0] "" Vector__XXX
 SG_ IC3_CSB_WUP_FLT m2 : 8|1@0+ (1,0) [0|0] "" Vector__XXX
 SG_ IC2_IDLE_MODE_FLT m1 : 24|1@0+ (1,0) [0|0] "" Vector__XXX
 SG_ IC2_AN_OPEN_FLT m1 : 39|1@0+ (1,0) [0|0] "" Vector__XXX
 SG_ IC2_GPIO_SHORT_FLT m1 : 38|1@0+ (1,0) [0|0] "" Vector__XXX
 SG_ IC2_CB_SHORT_FLT m1 : 37|1@0+ (1,0) [0|0] "" Vector__XXX
 SG_ IC2_CB_OPEN_FLT m1 : 36|1@0+ (1,0) [0|0] "" Vector__XXX
 SG_ IC2_OSC_ERR_FLT m1 : 35|1@0+ (1,0) [0|0] "" Vector__XXX
 SG_ IC2_DED_ERR_FLT m1 : 34|1@0+ (1,0) [0|0] "" Vector__XXX
 SG_ IC2_FUSE_ERR_FLT m1 : 33|1@0+ (1,0) [0|0] "" Vector__XXX
 SG_ IC2_VCOM_OV_FLT m1 : 16|1@0+ (1,0) [0|0] "" Vector__XXX
 SG_ IC2_VCOM_UV_FLT m1 : 31|1@0+ (1,0) [0|0] "" Vector__XXX
 SG_ IC2_VANA_OV_FLT m1 : 30|1@0+ (1,0) [0|0] "" Vector__XXX
 SG_ IC2_VANA_UV_FLT m1 : 29|1@0+ (1,0) [0|0] "" Vector__XXX
 SG_ IC2_ADC1_B_FLT m1 : 28|1@0+ (1,0) [0|0] "" Vector__XXX
 SG_ IC2_ADC1_A_FLT m1 : 27|1@0+ (1,0) [0|0] "" Vector__XXX
 SG_ IC2_GND_LOSS_FLT m1 : 26|1@0+ (1,0) [0|0] "" Vector__XXX
 SG_ IC2_IC_TSD_FLT m1 : 25|1@0+ (1,0) [0|0] "" Vector__XXX
 SG_ IC2_GPIO0_WUP_FLT m1 : 23|1@0+ (1,0) [0|0] "" Vector__XXX
 SG_ IC2_IS_OL_FLT m1 : 22|1@0+ (1,0) [0|0] "" Vector__XXX
 SG_ IC2_IS_OC_FLT m1 : 21|1@0+ (1,0) [0|0] "" Vector__XXX
 SG_ IC2_AN_OT_FLT m1 : 20|1@0+ (1,0) [0|0] "" Vector__XXX
 SG_ IC2_AN_UT_FLT m1 : 19|1@0+ (1,0) [0|0] "" Vector__XXX
 SG_ IC2_CT_OV_FLT m1 : 18|1@0+ (1,0) [0|0] "" Vector__XXX
 SG_ IC2_CT_UV_FLT m1 : 17|1@0+ (1,0) [0|0] "" Vector__XXX
 SG_ IC2_POR m1 : 15|1@0+ (1,0) [0|0] "" Vector__XXX
 SG_ IC2_RESET_FLT m1 : 14|1@0+ (1,0) [0|0] "" Vector__XXX
 SG_ IC2_COM_ERR_OVR_FLT m1 : 13|1@0+ (1,0) [0|0] "" Vector__XXX
 SG_ IC2_VPWR_OV_FLT m1 : 12|1@0+ (1,0) [0|0] "" Vector__XXX
 SG_ IC2_VPWR_LV_FLT m1 : 11|1@0+ (1,0) [0|0] "" Vector__XXX
 SG_ IC2_COM_LOSS_FLT m1 : 10|1@0+ (1,0) [0|0] "" Vector__XXX
 SG_ IC2_COM_ERR_FLT m1 : 9|1@0+ (1,0) [0|0] "" Vector__XXX
 SG_ IC2_CSB_WUP_FLT m1 : 8|1@0+ (1,0) [0|0] "" Vector__XXX
 SG_ IC1_IDLE_MODE_FLT m0 : 24|1@0+ (1,0) [0|0] "" Vector__XXX
 SG_ IC1_AN_OPEN_FLT m0 : 39|1@0+ (1,0) [0|0] "" Vector__XXX
 SG_ IC1_GPIO_SHORT_FLT m0 : 38|1@0+ (1,0) [0|0] "" Vector__XXX
 SG_ IC1_CB_SHORT_FLT m0 : 37|1@0+ (1,0) [0|0] "" Vector__XXX
 SG_ IC1_CB_OPEN_FLT m0 : 36|1@0+ (1,0) [0|0] "" Vector__XXX
 SG_ IC1_OSC_ERR_FLT m0 : 35|1@0+ (1,0) [0|0] "" Vector__XXX
 SG_ IC1_DED_ERR_FLT m0 : 34|1@0+ (1,0) [0|0] "" Vector__XXX
 SG_ IC1_FUSE_ERR_FLT m0 : 33|1@0+ (1,0) [0|0] "" Vector__XXX
 SG_ IC1_VCOM_OV_FLT m0 : 16|1@0+ (1,0) [0|0] "" Vector__XXX
 SG_ IC1_VCOM_UV_FLT m0 : 31|1@0+ (1,0) [0|0] "" Vector__XXX
 SG_ IC1_VANA_OV_FLT m0 : 30|1@0+ (1,0) [0|0] "" Vector__XXX
 SG_ IC1_VANA_UV_FLT m0 : 29|1@0+ (1,0) [0|0] "" Vector__XXX
 SG_ IC1_ADC1_B_FLT m0 : 28|1@0+ (1,0) [0|0] "" Vector__XXX
 SG_ IC1_ADC1_A_FLT m0 : 27|1@0+ (1,0) [0|0] "" Vector__XXX
 SG_ IC1_GND_LOSS_FLT m0 : 26|1@0+ (1,0) [0|0] "" Vector__XXX
 SG_ IC1_IC_TSD_FLT m0 : 25|1@0+ (1,0) [0|0] "" Vector__XXX
 SG_ IC1_GPIO0_WUP_FLT m0 : 23|1@0+ (1,0) [0|0] "" Vector__XXX
 SG_ IC1_IS_OL_FLT m0 : 22|1@0+ (1,0) [0|0] "" Vector__XXX
 SG_ IC1_IS_OC_FLT m0 : 21|1@0+ (1,0) [0|0] "" Vector__XXX
 SG_ IC1_AN_OT_FLT m0 : 20|1@0+ (1,0) [0|0] "" Vector__XXX
 SG_ IC1_AN_UT_FLT m0 : 19|1@0+ (1,0) [0|0] "" Vector__XXX
 SG_ IC1_CT_OV_FLT m0 : 18|1@0+ (1,0) [0|0] "" Vector__XXX
 SG_ IC1_CT_UV_FLT m0 : 17|1@0+ (1,0) [0|0] "" Vector__XXX
 SG_ IC1_POR m0 : 15|1@0+ (1,0) [0|0] "" Vector__XXX
 SG_ IC1_RESET_FLT m0 : 14|1@0+ (1,0) [0|0] "" Vector__XXX
 SG_ IC1_COM_ERR_OVR_FLT m0 : 13|1@0+ (1,0) [0|0] "" Vector__XXX
 SG_ IC1_VPWR_OV_FLT m0 : 12|1@0+ (1,0) [0|0] "" Vector__XXX
 SG_ IC1_VPWR_LV_FLT m0 : 11|1@0+ (1,0) [0|0] "" Vector__XXX
 SG_ IC1_COM_LOSS_FLT m0 : 10|1@0+ (1,0) [0|0] "" Vector__XXX
 SG_ IC1_COM_ERR_FLT m0 : 9|1@0+ (1,0) [0|0] "" Vector__XXX
 SG_ IC1_CSB_WUP_FLT m0 : 8|1@0+ (1,0) [0|0] "" Vector__XXX
 SG_ CSC12_IndexFaults M : 7|8@0+ (1,0) [0|255] "" Vector__XXX

BO_ 2550988802 CSC13_CIDs_FAULTS: 8 CSC13
 SG_ IC4_IDLE_MODE_FLT m3 : 24|1@0+ (1,0) [0|0] "" Vector__XXX
 SG_ IC4_AN_OPEN_FLT m3 : 39|1@0+ (1,0) [0|0] "" Vector__XXX
 SG_ IC4_GPIO_SHORT_FLT m3 : 38|1@0+ (1,0) [0|0] "" Vector__XXX
 SG_ IC4_CB_SHORT_FLT m3 : 37|1@0+ (1,0) [0|0] "" Vector__XXX
 SG_ IC4_CB_OPEN_FLT m3 : 36|1@0+ (1,0) [0|0] "" Vector__XXX
 SG_ IC4_OSC_ERR_FLT m3 : 35|1@0+ (1,0) [0|0] "" Vector__XXX
 SG_ IC4_DED_ERR_FLT m3 : 34|1@0+ (1,0) [0|0] "" Vector__XXX
 SG_ IC4_FUSE_ERR_FLT m3 : 33|1@0+ (1,0) [0|0] "" Vector__XXX
 SG_ IC4_VCOM_OV_FLT m3 : 16|1@0+ (1,0) [0|0] "" Vector__XXX
 SG_ IC4_VCOM_UV_FLT m3 : 31|1@0+ (1,0) [0|0] "" Vector__XXX
 SG_ IC4_VANA_OV_FLT m3 : 30|1@0+ (1,0) [0|0] "" Vector__XXX
 SG_ IC4_VANA_UV_FLT m3 : 29|1@0+ (1,0) [0|0] "" Vector__XXX
 SG_ IC4_ADC1_B_FLT m3 : 28|1@0+ (1,0) [0|0] "" Vector__XXX
 SG_ IC4_ADC1_A_FLT m3 : 27|1@0+ (1,0) [0|0] "" Vector__XXX
 SG_ IC4_GND_LOSS_FLT m3 : 26|1@0+ (1,0) [0|0] "" Vector__XXX
 SG_ IC4_IC_TSD_FLT m3 : 25|1@0+ (1,0) [0|0] "" Vector__XXX
 SG_ IC4_GPIO0_WUP_FLT m3 : 23|1@0+ (1,0) [0|0] "" Vector__XXX
 SG_ IC4_IS_OL_FLT m3 : 22|1@0+ (1,0) [0|0] "" Vector__XXX
 SG_ IC4_IS_OC_FLT m3 : 21|1@0+ (1,0) [0|0] "" Vector__XXX
 SG_ IC4_AN_OT_FLT m3 : 20|1@0+ (1,0) [0|0] "" Vector__XXX
 SG_ IC4_AN_UT_FLT m3 : 19|1@0+ (1,0) [0|0] "" Vector__XXX
 SG_ IC4_CT_OV_FLT m3 : 18|1@0+ (1,0) [0|0] "" Vector__XXX
 SG_ IC4_CT_UV_FLT m3 : 17|1@0+ (1,0) [0|0] "" Vector__XXX
 SG_ IC4_POR m3 : 15|1@0+ (1,0) [0|0] "" Vector__XXX
 SG_ IC4_RESET_FLT m3 : 14|1@0+ (1,0) [0|0] "" Vector__XXX
 SG_ IC4_COM_ERR_OVR_FLT m3 : 13|1@0+ (1,0) [0|0] "" Vector__XXX
 SG_ IC4_VPWR_OV_FLT m3 : 12|1@0+ (1,0) [0|0] "" Vector__XXX
 SG_ IC4_VPWR_LV_FLT m3 : 11|1@0+ (1,0) [0|0] "" Vector__XXX
 SG_ IC4_COM_LOSS_FLT m3 : 10|1@0+ (1,0) [0|0] "" Vector__XXX
 SG_ IC4_COM_ERR_FLT m3 : 9|1@0+ (1,0) [0|0] "" Vector__XXX
 SG_ IC4_CSB_WUP_FLT m3 : 8|1@0+ (1,0) [0|0] "" Vector__XXX
 SG_ IC3_IDLE_MODE_FLT m2 : 24|1@0+ (1,0) [0|0] "" Vector__XXX
 SG_ IC3_AN_OPEN_FLT m2 : 39|1@0+ (1,0) [0|0] "" Vector__XXX
 SG_ IC3_GPIO_SHORT_FLT m2 : 38|1@0+ (1,0) [0|0] "" Vector__XXX
 SG_ IC3_CB_SHORT_FLT m2 : 37|1@0+ (1,0) [0|0] "" Vector__XXX
 SG_ IC3_CB_OPEN_FLT m2 : 36|1@0+ (1,0) [0|0] "" Vector__XXX
 SG_ IC3_OSC_ERR_FLT m2 : 35|1@0+ (1,0) [0|0] "" Vector__XXX
 SG_ IC3_DED_ERR_FLT m2 : 34|1@0+ (1,0) [0|0] "" Vector__XXX
 SG_ IC3_FUSE_ERR_FLT m2 : 33|1@0+ (1,0) [0|0] "" Vector__XXX
 SG_ IC3_VCOM_OV_FLT m2 : 16|1@0+ (1,0) [0|0] "" Vector__XXX
 SG_ IC3_VCOM_UV_FLT m2 : 31|1@0+ (1,0) [0|0] "" Vector__XXX
 SG_ IC3_VANA_OV_FLT m2 : 30|1@0+ (1,0) [0|0] "" Vector__XXX
 SG_ IC3_VANA_UV_FLT m2 : 29|1@0+ (1,0) [0|0] "" Vector__XXX
 SG_ IC3_ADC1_B_FLT m2 : 28|1@0+ (1,0) [0|0] "" Vector__XXX
 SG_ IC3_ADC1_A_FLT m2 : 27|1@0+ (1,0) [0|0] "" Vector__XXX
 SG_ IC3_GND_LOSS_FLT m2 : 26|1@0+ (1,0) [0|0] "" Vector__XXX
 SG_ IC3_IC_TSD_FLT m2 : 25|1@0+ (1,0) [0|0] "" Vector__XXX
 SG_ IC3_GPIO0_WUP_FLT m2 : 23|1@0+ (1,0) [0|0] "" Vector__XXX
 SG_ IC3_IS_OL_FLT m2 : 22|1@0+ (1,0) [0|0] "" Vector__XXX
 SG_ IC3_IS_OC_FLT m2 : 21|1@0+ (1,0) [0|0] "" Vector__XXX
 SG_ IC3_AN_OT_FLT m2 : 20|1@0+ (1,0) [0|0] "" Vector__XXX
 SG_ IC3_AN_UT_FLT m2 : 19|1@0+ (1,0) [0|0] "" Vector__XXX
 SG_ IC3_CT_OV_FLT m2 : 18|1@0+ (1,0) [0|0] "" Vector__XXX
 SG_ IC3_CT_UV_FLT m2 : 17|1@0+ (1,0) [0|0] "" Vector__XXX
 SG_ IC3_POR m2 : 15|1@0+ (1,0) [0|0] "" Vector__XXX
 SG_ IC3_RESET_FLT m2 : 14|1@0+ (1,0) [0|0] "" Vector__XXX
 SG_ IC3_COM_ERR_OVR_FLT m2 : 13|1@0+ (1,0) [0|0] "" Vector__XXX
 SG_ IC3_VPWR_OV_FLT m2 : 12|1@0+ (1,0) [0|0] "" Vector__XXX
 SG_ IC3_VPWR_LV_FLT m2 : 11|1@0+ (1,0) [0|0] "" Vector__XXX
 SG_ IC3_COM_LOSS_FLT m2 : 10|1@0+ (1,0) [0|0] "" Vector__XXX
 SG_ IC3_COM_ERR_FLT m2 : 9|1@0+ (1,0) [0|0] "" Vector__XXX
 SG_ IC3_CSB_WUP_FLT m2 : 8|1@0+ (1,0) [0|0] "" Vector__XXX
 SG_ IC2_IDLE_MODE_FLT m1 : 24|1@0+ (1,0) [0|0] "" Vector__XXX
 SG_ IC2_AN_OPEN_FLT m1 : 39|1@0+ (1,0) [0|0] "" Vector__XXX
 SG_ IC2_GPIO_SHORT_FLT m1 : 38|1@0+ (1,0) [0|0] "" Vector__XXX
 SG_ IC2_CB_SHORT_FLT m1 : 37|1@0+ (1,0) [0|0] "" Vector__XXX
 SG_ IC2_CB_OPEN_FLT m1 : 36|1@0+ (1,0) [0|0] "" Vector__XXX
 SG_ IC2_OSC_ERR_FLT m1 : 35|1@0+ (1,0) [0|0] "" Vector__XXX
 SG_ IC2_DED_ERR_FLT m1 : 34|1@0+ (1,0) [0|0] "" Vector__XXX
 SG_ IC2_FUSE_ERR_FLT m1 : 33|1@0+ (1,0) [0|0] "" Vector__XXX
 SG_ IC2_VCOM_OV_FLT m1 : 16|1@0+ (1,0) [0|0] "" Vector__XXX
 SG_ IC2_VCOM_UV_FLT m1 : 31|1@0+ (1,0) [0|0] "" Vector__XXX
 SG_ IC2_VANA_OV_FLT m1 : 30|1@0+ (1,0) [0|0] "" Vector__XXX
 SG_ IC2_VANA_UV_FLT m1 : 29|1@0+ (1,0) [0|0] "" Vector__XXX
 SG_ IC2_ADC1_B_FLT m1 : 28|1@0+ (1,0) [0|0] "" Vector__XXX
 SG_ IC2_ADC1_A_FLT m1 : 27|1@0+ (1,0) [0|0] "" Vector__XXX
 SG_ IC2_GND_LOSS_FLT m1 : 26|1@0+ (1,0) [0|0] "" Vector__XXX
 SG_ IC2_IC_TSD_FLT m1 : 25|1@0+ (1,0) [0|0] "" Vector__XXX
 SG_ IC2_GPIO0_WUP_FLT m1 : 23|1@0+ (1,0) [0|0] "" Vector__XXX
 SG_ IC2_IS_OL_FLT m1 : 22|1@0+ (1,0) [0|0] "" Vector__XXX
 SG_ IC2_IS_OC_FLT m1 : 21|1@0+ (1,0) [0|0] "" Vector__XXX
 SG_ IC2_AN_OT_FLT m1 : 20|1@0+ (1,0) [0|0] "" Vector__XXX
 SG_ IC2_AN_UT_FLT m1 : 19|1@0+ (1,0) [0|0] "" Vector__XXX
 SG_ IC2_CT_OV_FLT m1 : 18|1@0+ (1,0) [0|0] "" Vector__XXX
 SG_ IC2_CT_UV_FLT m1 : 17|1@0+ (1,0) [0|0] "" Vector__XXX
 SG_ IC2_POR m1 : 15|1@0+ (1,0) [0|0] "" Vector__XXX
 SG_ IC2_RESET_FLT m1 : 14|1@0+ (1,0) [0|0] "" Vector__XXX
 SG_ IC2_COM_ERR_OVR_FLT m1 : 13|1@0+ (1,0) [0|0] "" Vector__XXX
 SG_ IC2_VPWR_OV_FLT m1 : 12|1@0+ (1,0) [0|0] "" Vector__XXX
 SG_ IC2_VPWR_LV_FLT m1 : 11|1@0+ (1,0) [0|0] "" Vector__XXX
 SG_ IC2_COM_LOSS_FLT m1 : 10|1@0+ (1,0) [0|0] "" Vector__XXX
 SG_ IC2_COM_ERR_FLT m1 : 9|1@0+ (1,0) [0|0] "" Vector__XXX
 SG_ IC2_CSB_WUP_FLT m1 : 8|1@0+ (1,0) [0|0] "" Vector__XXX
 SG_ IC1_IDLE_MODE_FLT m0 : 24|1@0+ (1,0) [0|0] "" Vector__XXX
 SG_ IC1_AN_OPEN_FLT m0 : 39|1@0+ (1,0) [0|0] "" Vector__XXX
 SG_ IC1_GPIO_SHORT_FLT m0 : 38|1@0+ (1,0) [0|0] "" Vector__XXX
 SG_ IC1_CB_SHORT_FLT m0 : 37|1@0+ (1,0) [0|0] "" Vector__XXX
 SG_ IC1_CB_OPEN_FLT m0 : 36|1@0+ (1,0) [0|0] "" Vector__XXX
 SG_ IC1_OSC_ERR_FLT m0 : 35|1@0+ (1,0) [0|0] "" Vector__XXX
 SG_ IC1_DED_ERR_FLT m0 : 34|1@0+ (1,0) [0|0] "" Vector__XXX
 SG_ IC1_FUSE_ERR_FLT m0 : 33|1@0+ (1,0) [0|0] "" Vector__XXX
 SG_ IC1_VCOM_OV_FLT m0 : 16|1@0+ (1,0) [0|0] "" Vector__XXX
 SG_ IC1_VCOM_UV_FLT m0 : 31|1@0+ (1,0) [0|0] "" Vector__XXX
 SG_ IC1_VANA_OV_FLT m0 : 30|1@0+ (1,0) [0|0] "" Vector__XXX
 SG_ IC1_VANA_UV_FLT m0 : 29|1@0+ (1,0) [0|0] "" Vector__XXX
 SG_ IC1_ADC1_B_FLT m0 : 28|1@0+ (1,0) [0|0] "" Vector__XXX
 SG_ IC1_ADC1_A_FLT m0 : 27|1@0+ (1,0) [0|0] "" Vector__XXX
 SG_ IC1_GND_LOSS_FLT m0 : 26|1@0+ (1,0) [0|0] "" Vector__XXX
 SG_ IC1_IC_TSD_FLT m0 : 25|1@0+ (1,0) [0|0] "" Vector__XXX
 SG_ IC1_GPIO0_WUP_FLT m0 : 23|1@0+ (1,0) [0|0] "" Vector__XXX
 SG_ IC1_IS_OL_FLT m0 : 22|1@0+ (1,0) [0|0] "" Vector__XXX
 SG_ IC1_IS_OC_FLT m0 : 21|1@0+ (1,0) [0|0] "" Vector__XXX
 SG_ IC1_AN_OT_FLT m0 : 20|1@0+ (1,0) [0|0] "" Vector__XXX
 SG_ IC1_AN_UT_FLT m0 : 19|1@0+ (1,0) [0|0] "" Vector__XXX
 SG_ IC1_CT_OV_FLT m0 : 18|1@0+ (1,0) [0|0] "" Vector__XXX
 SG_ IC1_CT_UV_FLT m0 : 17|1@0+ (1,0) [0|0] "" Vector__XXX
 SG_ IC1_POR m0 : 15|1@0+ (1,0) [0|0] "" Vector__XXX
 SG_ IC1_RESET_FLT m0 : 14|1@0+ (1,0) [0|0] "" Vector__XXX
 SG_ IC1_COM_ERR_OVR_FLT m0 : 13|1@0+ (1,0) [0|0] "" Vector__XXX
 SG_ IC1_VPWR_OV_FLT m0 : 12|1@0+ (1,0) [0|0] "" Vector__XXX
 SG_ IC1_VPWR_LV_FLT m0 : 11|1@0+ (1,0) [0|0] "" Vector__XXX
 SG_ IC1_COM_LOSS_FLT m0 : 10|1@0+ (1,0) [0|0] "" Vector__XXX
 SG_ IC1_COM_ERR_FLT m0 : 9|1@0+ (1,0) [0|0] "" Vector__XXX
 SG_ IC1_CSB_WUP_FLT m0 : 8|1@0+ (1,0) [0|0] "" Vector__XXX
 SG_ CSC13_IndexFaults M : 7|8@0+ (1,0) [0|255] "" Vector__XXX

BO_ 2551054338 CSC14_CIDs_FAULTS: 8 CSC14
 SG_ IC4_IDLE_MODE_FLT m3 : 24|1@0+ (1,0) [0|0] "" Vector__XXX
 SG_ IC4_AN_OPEN_FLT m3 : 39|1@0+ (1,0) [0|0] "" Vector__XXX
 SG_ IC4_GPIO_SHORT_FLT m3 : 38|1@0+ (1,0) [0|0] "" Vector__XXX
 SG_ IC4_CB_SHORT_FLT m3 : 37|1@0+ (1,0) [0|0] "" Vector__XXX
 SG_ IC4_CB_OPEN_FLT m3 : 36|1@0+ (1,0) [0|0] "" Vector__XXX
 SG_ IC4_OSC_ERR_FLT m3 : 35|1@0+ (1,0) [0|0] "" Vector__XXX
 SG_ IC4_DED_ERR_FLT m3 : 34|1@0+ (1,0) [0|0] "" Vector__XXX
 SG_ IC4_FUSE_ERR_FLT m3 : 33|1@0+ (1,0) [0|0] "" Vector__XXX
 SG_ IC4_VCOM_OV_FLT m3 : 16|1@0+ (1,0) [0|0] "" Vector__XXX
 SG_ IC4_VCOM_UV_FLT m3 : 31|1@0+ (1,0) [0|0] "" Vector__XXX
 SG_ IC4_VANA_OV_FLT m3 : 30|1@0+ (1,0) [0|0] "" Vector__XXX
 SG_ IC4_VANA_UV_FLT m3 : 29|1@0+ (1,0) [0|0] "" Vector__XXX
 SG_ IC4_ADC1_B_FLT m3 : 28|1@0+ (1,0) [0|0] "" Vector__XXX
 SG_ IC4_ADC1_A_FLT m3 : 27|1@0+ (1,0) [0|0] "" Vector__XXX
 SG_ IC4_GND_LOSS_FLT m3 : 26|1@0+ (1,0) [0|0] "" Vector__XXX
 SG_ IC4_IC_TSD_FLT m3 : 25|1@0+ (1,0) [0|0] "" Vector__XXX
 SG_ IC4_GPIO0_WUP_FLT m3 : 23|1@0+ (1,0) [0|0] "" Vector__XXX
 SG_ IC4_IS_OL_FLT m3 : 22|1@0+ (1,0) [0|0] "" Vector__XXX
 SG_ IC4_IS_OC_FLT m3 : 21|1@0+ (1,0) [0|0] "" Vector__XXX
 SG_ IC4_AN_OT_FLT m3 : 20|1@0+ (1,0) [0|0] "" Vector__XXX
 SG_ IC4_AN_UT_FLT m3 : 19|1@0+ (1,0) [0|0] "" Vector__XXX
 SG_ IC4_CT_OV_FLT m3 : 18|1@0+ (1,0) [0|0] "" Vector__XXX
 SG_ IC4_CT_UV_FLT m3 : 17|1@0+ (1,0) [0|0] "" Vector__XXX
 SG_ IC4_POR m3 : 15|1@0+ (1,0) [0|0] "" Vector__XXX
 SG_ IC4_RESET_FLT m3 : 14|1@0+ (1,0) [0|0] "" Vector__XXX
 SG_ IC4_COM_ERR_OVR_FLT m3 : 13|1@0+ (1,0) [0|0] "" Vector__XXX
 SG_ IC4_VPWR_OV_FLT m3 : 12|1@0+ (1,0) [0|0] "" Vector__XXX
 SG_ IC4_VPWR_LV_FLT m3 : 11|1@0+ (1,0) [0|0] "" Vector__XXX
 SG_ IC4_COM_LOSS_FLT m3 : 10|1@0+ (1,0) [0|0] "" Vector__XXX
 SG_ IC4_COM_ERR_FLT m3 : 9|1@0+ (1,0) [0|0] "" Vector__XXX
 SG_ IC4_CSB_WUP_FLT m3 : 8|1@0+ (1,0) [0|0] "" Vector__XXX
 SG_ IC3_IDLE_MODE_FLT m2 : 24|1@0+ (1,0) [0|0] "" Vector__XXX
 SG_ IC3_AN_OPEN_FLT m2 : 39|1@0+ (1,0) [0|0] "" Vector__XXX
 SG_ IC3_GPIO_SHORT_FLT m2 : 38|1@0+ (1,0) [0|0] "" Vector__XXX
 SG_ IC3_CB_SHORT_FLT m2 : 37|1@0+ (1,0) [0|0] "" Vector__XXX
 SG_ IC3_CB_OPEN_FLT m2 : 36|1@0+ (1,0) [0|0] "" Vector__XXX
 SG_ IC3_OSC_ERR_FLT m2 : 35|1@0+ (1,0) [0|0] "" Vector__XXX
 SG_ IC3_DED_ERR_FLT m2 : 34|1@0+ (1,0) [0|0] "" Vector__XXX
 SG_ IC3_FUSE_ERR_FLT m2 : 33|1@0+ (1,0) [0|0] "" Vector__XXX
 SG_ IC3_VCOM_OV_FLT m2 : 16|1@0+ (1,0) [0|0] "" Vector__XXX
 SG_ IC3_VCOM_UV_FLT m2 : 31|1@0+ (1,0) [0|0] "" Vector__XXX
 SG_ IC3_VANA_OV_FLT m2 : 30|1@0+ (1,0) [0|0] "" Vector__XXX
 SG_ IC3_VANA_UV_FLT m2 : 29|1@0+ (1,0) [0|0] "" Vector__XXX
 SG_ IC3_ADC1_B_FLT m2 : 28|1@0+ (1,0) [0|0] "" Vector__XXX
 SG_ IC3_ADC1_A_FLT m2 : 27|1@0+ (1,0) [0|0] "" Vector__XXX
 SG_ IC3_GND_LOSS_FLT m2 : 26|1@0+ (1,0) [0|0] "" Vector__XXX
 SG_ IC3_IC_TSD_FLT m2 : 25|1@0+ (1,0) [0|0] "" Vector__XXX
 SG_ IC3_GPIO0_WUP_FLT m2 : 23|1@0+ (1,0) [0|0] "" Vector__XXX
 SG_ IC3_IS_OL_FLT m2 : 22|1@0+ (1,0) [0|0] "" Vector__XXX
 SG_ IC3_IS_OC_FLT m2 : 21|1@0+ (1,0) [0|0] "" Vector__XXX
 SG_ IC3_AN_OT_FLT m2 : 20|1@0+ (1,0) [0|0] "" Vector__XXX
 SG_ IC3_AN_UT_FLT m2 : 19|1@0+ (1,0) [0|0] "" Vector__XXX
 SG_ IC3_CT_OV_FLT m2 : 18|1@0+ (1,0) [0|0] "" Vector__XXX
 SG_ IC3_CT_UV_FLT m2 : 17|1@0+ (1,0) [0|0] "" Vector__XXX
 SG_ IC3_POR m2 : 15|1@0+ (1,0) [0|0] "" Vector__XXX
 SG_ IC3_RESET_FLT m2 : 14|1@0+ (1,0) [0|0] "" Vector__XXX
 SG_ IC3_COM_ERR_OVR_FLT m2 : 13|1@0+ (1,0) [0|0] "" Vector__XXX
 SG_ IC3_VPWR_OV_FLT m2 : 12|1@0+ (1,0) [0|0] "" Vector__XXX
 SG_ IC3_VPWR_LV_FLT m2 : 11|1@0+ (1,0) [0|0] "" Vector__XXX
 SG_ IC3_COM_LOSS_FLT m2 : 10|1@0+ (1,0) [0|0] "" Vector__XXX
 SG_ IC3_COM_ERR_FLT m2 : 9|1@0+ (1,0) [0|0] "" Vector__XXX
 SG_ IC3_CSB_WUP_FLT m2 : 8|1@0+ (1,0) [0|0] "" Vector__XXX
 SG_ IC2_IDLE_MODE_FLT m1 : 24|1@0+ (1,0) [0|0] "" Vector__XXX
 SG_ IC2_AN_OPEN_FLT m1 : 39|1@0+ (1,0) [0|0] "" Vector__XXX
 SG_ IC2_GPIO_SHORT_FLT m1 : 38|1@0+ (1,0) [0|0] "" Vector__XXX
 SG_ IC2_CB_SHORT_FLT m1 : 37|1@0+ (1,0) [0|0] "" Vector__XXX
 SG_ IC2_CB_OPEN_FLT m1 : 36|1@0+ (1,0) [0|0] "" Vector__XXX
 SG_ IC2_OSC_ERR_FLT m1 : 35|1@0+ (1,0) [0|0] "" Vector__XXX
 SG_ IC2_DED_ERR_FLT m1 : 34|1@0+ (1,0) [0|0] "" Vector__XXX
 SG_ IC2_FUSE_ERR_FLT m1 : 33|1@0+ (1,0) [0|0] "" Vector__XXX
 SG_ IC2_VCOM_OV_FLT m1 : 16|1@0+ (1,0) [0|0] "" Vector__XXX
 SG_ IC2_VCOM_UV_FLT m1 : 31|1@0+ (1,0) [0|0] "" Vector__XXX
 SG_ IC2_VANA_OV_FLT m1 : 30|1@0+ (1,0) [0|0] "" Vector__XXX
 SG_ IC2_VANA_UV_FLT m1 : 29|1@0+ (1,0) [0|0] "" Vector__XXX
 SG_ IC2_ADC1_B_FLT m1 : 28|1@0+ (1,0) [0|0] "" Vector__XXX
 SG_ IC2_ADC1_A_FLT m1 : 27|1@0+ (1,0) [0|0] "" Vector__XXX
 SG_ IC2_GND_LOSS_FLT m1 : 26|1@0+ (1,0) [0|0] "" Vector__XXX
 SG_ IC2_IC_TSD_FLT m1 : 25|1@0+ (1,0) [0|0] "" Vector__XXX
 SG_ IC2_GPIO0_WUP_FLT m1 : 23|1@0+ (1,0) [0|0] "" Vector__XXX
 SG_ IC2_IS_OL_FLT m1 : 22|1@0+ (1,0) [0|0] "" Vector__XXX
 SG_ IC2_IS_OC_FLT m1 : 21|1@0+ (1,0) [0|0] "" Vector__XXX
 SG_ IC2_AN_OT_FLT m1 : 20|1@0+ (1,0) [0|0] "" Vector__XXX
 SG_ IC2_AN_UT_FLT m1 : 19|1@0+ (1,0) [0|0] "" Vector__XXX
 SG_ IC2_CT_OV_FLT m1 : 18|1@0+ (1,0) [0|0] "" Vector__XXX
 SG_ IC2_CT_UV_FLT m1 : 17|1@0+ (1,0) [0|0] "" Vector__XXX
 SG_ IC2_POR m1 : 15|1@0+ (1,0) [0|0] "" Vector__XXX
 SG_ IC2_RESET_FLT m1 : 14|1@0+ (1,0) [0|0] "" Vector__XXX
 SG_ IC2_COM_ERR_OVR_FLT m1 : 13|1@0+ (1,0) [0|0] "" Vector__XXX
 SG_ IC2_VPWR_OV_FLT m1 : 12|1@0+ (1,0) [0|0] "" Vector__XXX
 SG_ IC2_VPWR_LV_FLT m1 : 11|1@0+ (1,0) [0|0] "" Vector__XXX
 SG_ IC2_COM_LOSS_FLT m1 : 10|1@0+ (1,0) [0|0] "" Vector__XXX
 SG_ IC2_COM_ERR_FLT m1 : 9|1@0+ (1,0) [0|0] "" Vector__XXX
 SG_ IC2_CSB_WUP_FLT m1 : 8|1@0+ (1,0) [0|0] "" Vector__XXX
 SG_ IC1_IDLE_MODE_FLT m0 : 24|1@0+ (1,0) [0|0] "" Vector__XXX
 SG_ IC1_AN_OPEN_FLT m0 : 39|1@0+ (1,0) [0|0] "" Vector__XXX
 SG_ IC1_GPIO_SHORT_FLT m0 : 38|1@0+ (1,0) [0|0] "" Vector__XXX
 SG_ IC1_CB_SHORT_FLT m0 : 37|1@0+ (1,0) [0|0] "" Vector__XXX
 SG_ IC1_CB_OPEN_FLT m0 : 36|1@0+ (1,0) [0|0] "" Vector__XXX
 SG_ IC1_OSC_ERR_FLT m0 : 35|1@0+ (1,0) [0|0] "" Vector__XXX
 SG_ IC1_DED_ERR_FLT m0 : 34|1@0+ (1,0) [0|0] "" Vector__XXX
 SG_ IC1_FUSE_ERR_FLT m0 : 33|1@0+ (1,0) [0|0] "" Vector__XXX
 SG_ IC1_VCOM_OV_FLT m0 : 16|1@0+ (1,0) [0|0] "" Vector__XXX
 SG_ IC1_VCOM_UV_FLT m0 : 31|1@0+ (1,0) [0|0] "" Vector__XXX
 SG_ IC1_VANA_OV_FLT m0 : 30|1@0+ (1,0) [0|0] "" Vector__XXX
 SG_ IC1_VANA_UV_FLT m0 : 29|1@0+ (1,0) [0|0] "" Vector__XXX
 SG_ IC1_ADC1_B_FLT m0 : 28|1@0+ (1,0) [0|0] "" Vector__XXX
 SG_ IC1_ADC1_A_FLT m0 : 27|1@0+ (1,0) [0|0] "" Vector__XXX
 SG_ IC1_GND_LOSS_FLT m0 : 26|1@0+ (1,0) [0|0] "" Vector__XXX
 SG_ IC1_IC_TSD_FLT m0 : 25|1@0+ (1,0) [0|0] "" Vector__XXX
 SG_ IC1_GPIO0_WUP_FLT m0 : 23|1@0+ (1,0) [0|0] "" Vector__XXX
 SG_ IC1_IS_OL_FLT m0 : 22|1@0+ (1,0) [0|0] "" Vector__XXX
 SG_ IC1_IS_OC_FLT m0 : 21|1@0+ (1,0) [0|0] "" Vector__XXX
 SG_ IC1_AN_OT_FLT m0 : 20|1@0+ (1,0) [0|0] "" Vector__XXX
 SG_ IC1_AN_UT_FLT m0 : 19|1@0+ (1,0) [0|0] "" Vector__XXX
 SG_ IC1_CT_OV_FLT m0 : 18|1@0+ (1,0) [0|0] "" Vector__XXX
 SG_ IC1_CT_UV_FLT m0 : 17|1@0+ (1,0) [0|0] "" Vector__XXX
 SG_ IC1_POR m0 : 15|1@0+ (1,0) [0|0] "" Vector__XXX
 SG_ IC1_RESET_FLT m0 : 14|1@0+ (1,0) [0|0] "" Vector__XXX
 SG_ IC1_COM_ERR_OVR_FLT m0 : 13|1@0+ (1,0) [0|0] "" Vector__XXX
 SG_ IC1_VPWR_OV_FLT m0 : 12|1@0+ (1,0) [0|0] "" Vector__XXX
 SG_ IC1_VPWR_LV_FLT m0 : 11|1@0+ (1,0) [0|0] "" Vector__XXX
 SG_ IC1_COM_LOSS_FLT m0 : 10|1@0+ (1,0) [0|0] "" Vector__XXX
 SG_ IC1_COM_ERR_FLT m0 : 9|1@0+ (1,0) [0|0] "" Vector__XXX
 SG_ IC1_CSB_WUP_FLT m0 : 8|1@0+ (1,0) [0|0] "" Vector__XXX
 SG_ CSC14_IndexFaults M : 7|8@0+ (1,0) [0|255] "" Vector__XXX

BO_ 2551119874 CSC15_CIDs_FAULTS: 8 CSC15
 SG_ IC4_IDLE_MODE_FLT m3 : 24|1@0+ (1,0) [0|0] "" Vector__XXX
 SG_ IC4_AN_OPEN_FLT m3 : 39|1@0+ (1,0) [0|0] "" Vector__XXX
 SG_ IC4_GPIO_SHORT_FLT m3 : 38|1@0+ (1,0) [0|0] "" Vector__XXX
 SG_ IC4_CB_SHORT_FLT m3 : 37|1@0+ (1,0) [0|0] "" Vector__XXX
 SG_ IC4_CB_OPEN_FLT m3 : 36|1@0+ (1,0) [0|0] "" Vector__XXX
 SG_ IC4_OSC_ERR_FLT m3 : 35|1@0+ (1,0) [0|0] "" Vector__XXX
 SG_ IC4_DED_ERR_FLT m3 : 34|1@0+ (1,0) [0|0] "" Vector__XXX
 SG_ IC4_FUSE_ERR_FLT m3 : 33|1@0+ (1,0) [0|0] "" Vector__XXX
 SG_ IC4_VCOM_OV_FLT m3 : 16|1@0+ (1,0) [0|0] "" Vector__XXX
 SG_ IC4_VCOM_UV_FLT m3 : 31|1@0+ (1,0) [0|0] "" Vector__XXX
 SG_ IC4_VANA_OV_FLT m3 : 30|1@0+ (1,0) [0|0] "" Vector__XXX
 SG_ IC4_VANA_UV_FLT m3 : 29|1@0+ (1,0) [0|0] "" Vector__XXX
 SG_ IC4_ADC1_B_FLT m3 : 28|1@0+ (1,0) [0|0] "" Vector__XXX
 SG_ IC4_ADC1_A_FLT m3 : 27|1@0+ (1,0) [0|0] "" Vector__XXX
 SG_ IC4_GND_LOSS_FLT m3 : 26|1@0+ (1,0) [0|0] "" Vector__XXX
 SG_ IC4_IC_TSD_FLT m3 : 25|1@0+ (1,0) [0|0] "" Vector__XXX
 SG_ IC4_GPIO0_WUP_FLT m3 : 23|1@0+ (1,0) [0|0] "" Vector__XXX
 SG_ IC4_IS_OL_FLT m3 : 22|1@0+ (1,0) [0|0] "" Vector__XXX
 SG_ IC4_IS_OC_FLT m3 : 21|1@0+ (1,0) [0|0] "" Vector__XXX
 SG_ IC4_AN_OT_FLT m3 : 20|1@0+ (1,0) [0|0] "" Vector__XXX
 SG_ IC4_AN_UT_FLT m3 : 19|1@0+ (1,0) [0|0] "" Vector__XXX
 SG_ IC4_CT_OV_FLT m3 : 18|1@0+ (1,0) [0|0] "" Vector__XXX
 SG_ IC4_CT_UV_FLT m3 : 17|1@0+ (1,0) [0|0] "" Vector__XXX
 SG_ IC4_POR m3 : 15|1@0+ (1,0) [0|0] "" Vector__XXX
 SG_ IC4_RESET_FLT m3 : 14|1@0+ (1,0) [0|0] "" Vector__XXX
 SG_ IC4_COM_ERR_OVR_FLT m3 : 13|1@0+ (1,0) [0|0] "" Vector__XXX
 SG_ IC4_VPWR_OV_FLT m3 : 12|1@0+ (1,0) [0|0] "" Vector__XXX
 SG_ IC4_VPWR_LV_FLT m3 : 11|1@0+ (1,0) [0|0] "" Vector__XXX
 SG_ IC4_COM_LOSS_FLT m3 : 10|1@0+ (1,0) [0|0] "" Vector__XXX
 SG_ IC4_COM_ERR_FLT m3 : 9|1@0+ (1,0) [0|0] "" Vector__XXX
 SG_ IC4_CSB_WUP_FLT m3 : 8|1@0+ (1,0) [0|0] "" Vector__XXX
 SG_ IC3_IDLE_MODE_FLT m2 : 24|1@0+ (1,0) [0|0] "" Vector__XXX
 SG_ IC3_AN_OPEN_FLT m2 : 39|1@0+ (1,0) [0|0] "" Vector__XXX
 SG_ IC3_GPIO_SHORT_FLT m2 : 38|1@0+ (1,0) [0|0] "" Vector__XXX
 SG_ IC3_CB_SHORT_FLT m2 : 37|1@0+ (1,0) [0|0] "" Vector__XXX
 SG_ IC3_CB_OPEN_FLT m2 : 36|1@0+ (1,0) [0|0] "" Vector__XXX
 SG_ IC3_OSC_ERR_FLT m2 : 35|1@0+ (1,0) [0|0] "" Vector__XXX
 SG_ IC3_DED_ERR_FLT m2 : 34|1@0+ (1,0) [0|0] "" Vector__XXX
 SG_ IC3_FUSE_ERR_FLT m2 : 33|1@0+ (1,0) [0|0] "" Vector__XXX
 SG_ IC3_VCOM_OV_FLT m2 : 16|1@0+ (1,0) [0|0] "" Vector__XXX
 SG_ IC3_VCOM_UV_FLT m2 : 31|1@0+ (1,0) [0|0] "" Vector__XXX
 SG_ IC3_VANA_OV_FLT m2 : 30|1@0+ (1,0) [0|0] "" Vector__XXX
 SG_ IC3_VANA_UV_FLT m2 : 29|1@0+ (1,0) [0|0] "" Vector__XXX
 SG_ IC3_ADC1_B_FLT m2 : 28|1@0+ (1,0) [0|0] "" Vector__XXX
 SG_ IC3_ADC1_A_FLT m2 : 27|1@0+ (1,0) [0|0] "" Vector__XXX
 SG_ IC3_GND_LOSS_FLT m2 : 26|1@0+ (1,0) [0|0] "" Vector__XXX
 SG_ IC3_IC_TSD_FLT m2 : 25|1@0+ (1,0) [0|0] "" Vector__XXX
 SG_ IC3_GPIO0_WUP_FLT m2 : 23|1@0+ (1,0) [0|0] "" Vector__XXX
 SG_ IC3_IS_OL_FLT m2 : 22|1@0+ (1,0) [0|0] "" Vector__XXX
 SG_ IC3_IS_OC_FLT m2 : 21|1@0+ (1,0) [0|0] "" Vector__XXX
 SG_ IC3_AN_OT_FLT m2 : 20|1@0+ (1,0) [0|0] "" Vector__XXX
 SG_ IC3_AN_UT_FLT m2 : 19|1@0+ (1,0) [0|0] "" Vector__XXX
 SG_ IC3_CT_OV_FLT m2 : 18|1@0+ (1,0) [0|0] "" Vector__XXX
 SG_ IC3_CT_UV_FLT m2 : 17|1@0+ (1,0) [0|0] "" Vector__XXX
 SG_ IC3_POR m2 : 15|1@0+ (1,0) [0|0] "" Vector__XXX
 SG_ IC3_RESET_FLT m2 : 14|1@0+ (1,0) [0|0] "" Vector__XXX
 SG_ IC3_COM_ERR_OVR_FLT m2 : 13|1@0+ (1,0) [0|0] "" Vector__XXX
 SG_ IC3_VPWR_OV_FLT m2 : 12|1@0+ (1,0) [0|0] "" Vector__XXX
 SG_ IC3_VPWR_LV_FLT m2 : 11|1@0+ (1,0) [0|0] "" Vector__XXX
 SG_ IC3_COM_LOSS_FLT m2 : 10|1@0+ (1,0) [0|0] "" Vector__XXX
 SG_ IC3_COM_ERR_FLT m2 : 9|1@0+ (1,0) [0|0] "" Vector__XXX
 SG_ IC3_CSB_WUP_FLT m2 : 8|1@0+ (1,0) [0|0] "" Vector__XXX
 SG_ IC2_IDLE_MODE_FLT m1 : 24|1@0+ (1,0) [0|0] "" Vector__XXX
 SG_ IC2_AN_OPEN_FLT m1 : 39|1@0+ (1,0) [0|0] "" Vector__XXX
 SG_ IC2_GPIO_SHORT_FLT m1 : 38|1@0+ (1,0) [0|0] "" Vector__XXX
 SG_ IC2_CB_SHORT_FLT m1 : 37|1@0+ (1,0) [0|0] "" Vector__XXX
 SG_ IC2_CB_OPEN_FLT m1 : 36|1@0+ (1,0) [0|0] "" Vector__XXX
 SG_ IC2_OSC_ERR_FLT m1 : 35|1@0+ (1,0) [0|0] "" Vector__XXX
 SG_ IC2_DED_ERR_FLT m1 : 34|1@0+ (1,0) [0|0] "" Vector__XXX
 SG_ IC2_FUSE_ERR_FLT m1 : 33|1@0+ (1,0) [0|0] "" Vector__XXX
 SG_ IC2_VCOM_OV_FLT m1 : 16|1@0+ (1,0) [0|0] "" Vector__XXX
 SG_ IC2_VCOM_UV_FLT m1 : 31|1@0+ (1,0) [0|0] "" Vector__XXX
 SG_ IC2_VANA_OV_FLT m1 : 30|1@0+ (1,0) [0|0] "" Vector__XXX
 SG_ IC2_VANA_UV_FLT m1 : 29|1@0+ (1,0) [0|0] "" Vector__XXX
 SG_ IC2_ADC1_B_FLT m1 : 28|1@0+ (1,0) [0|0] "" Vector__XXX
 SG_ IC2_ADC1_A_FLT m1 : 27|1@0+ (1,0) [0|0] "" Vector__XXX
 SG_ IC2_GND_LOSS_FLT m1 : 26|1@0+ (1,0) [0|0] "" Vector__XXX
 SG_ IC2_IC_TSD_FLT m1 : 25|1@0+ (1,0) [0|0] "" Vector__XXX
 SG_ IC2_GPIO0_WUP_FLT m1 : 23|1@0+ (1,0) [0|0] "" Vector__XXX
 SG_ IC2_IS_OL_FLT m1 : 22|1@0+ (1,0) [0|0] "" Vector__XXX
 SG_ IC2_IS_OC_FLT m1 : 21|1@0+ (1,0) [0|0] "" Vector__XXX
 SG_ IC2_AN_OT_FLT m1 : 20|1@0+ (1,0) [0|0] "" Vector__XXX
 SG_ IC2_AN_UT_FLT m1 : 19|1@0+ (1,0) [0|0] "" Vector__XXX
 SG_ IC2_CT_OV_FLT m1 : 18|1@0+ (1,0) [0|0] "" Vector__XXX
 SG_ IC2_CT_UV_FLT m1 : 17|1@0+ (1,0) [0|0] "" Vector__XXX
 SG_ IC2_POR m1 : 15|1@0+ (1,0) [0|0] "" Vector__XXX
 SG_ IC2_RESET_FLT m1 : 14|1@0+ (1,0) [0|0] "" Vector__XXX
 SG_ IC2_COM_ERR_OVR_FLT m1 : 13|1@0+ (1,0) [0|0] "" Vector__XXX
 SG_ IC2_VPWR_OV_FLT m1 : 12|1@0+ (1,0) [0|0] "" Vector__XXX
 SG_ IC2_VPWR_LV_FLT m1 : 11|1@0+ (1,0) [0|0] "" Vector__XXX
 SG_ IC2_COM_LOSS_FLT m1 : 10|1@0+ (1,0) [0|0] "" Vector__XXX
 SG_ IC2_COM_ERR_FLT m1 : 9|1@0+ (1,0) [0|0] "" Vector__XXX
 SG_ IC2_CSB_WUP_FLT m1 : 8|1@0+ (1,0) [0|0] "" Vector__XXX
 SG_ IC1_IDLE_MODE_FLT m0 : 24|1@0+ (1,0) [0|0] "" Vector__XXX
 SG_ IC1_AN_OPEN_FLT m0 : 39|1@0+ (1,0) [0|0] "" Vector__XXX
 SG_ IC1_GPIO_SHORT_FLT m0 : 38|1@0+ (1,0) [0|0] "" Vector__XXX
 SG_ IC1_CB_SHORT_FLT m0 : 37|1@0+ (1,0) [0|0] "" Vector__XXX
 SG_ IC1_CB_OPEN_FLT m0 : 36|1@0+ (1,0) [0|0] "" Vector__XXX
 SG_ IC1_OSC_ERR_FLT m0 : 35|1@0+ (1,0) [0|0] "" Vector__XXX
 SG_ IC1_DED_ERR_FLT m0 : 34|1@0+ (1,0) [0|0] "" Vector__XXX
 SG_ IC1_FUSE_ERR_FLT m0 : 33|1@0+ (1,0) [0|0] "" Vector__XXX
 SG_ IC1_VCOM_OV_FLT m0 : 16|1@0+ (1,0) [0|0] "" Vector__XXX
 SG_ IC1_VCOM_UV_FLT m0 : 31|1@0+ (1,0) [0|0] "" Vector__XXX
 SG_ IC1_VANA_OV_FLT m0 : 30|1@0+ (1,0) [0|0] "" Vector__XXX
 SG_ IC1_VANA_UV_FLT m0 : 29|1@0+ (1,0) [0|0] "" Vector__XXX
 SG_ IC1_ADC1_B_FLT m0 : 28|1@0+ (1,0) [0|0] "" Vector__XXX
 SG_ IC1_ADC1_A_FLT m0 : 27|1@0+ (1,0) [0|0] "" Vector__XXX
 SG_ IC1_GND_LOSS_FLT m0 : 26|1@0+ (1,0) [0|0] "" Vector__XXX
 SG_ IC1_IC_TSD_FLT m0 : 25|1@0+ (1,0) [0|0] "" Vector__XXX
 SG_ IC1_GPIO0_WUP_FLT m0 : 23|1@0+ (1,0) [0|0] "" Vector__XXX
 SG_ IC1_IS_OL_FLT m0 : 22|1@0+ (1,0) [0|0] "" Vector__XXX
 SG_ IC1_IS_OC_FLT m0 : 21|1@0+ (1,0) [0|0] "" Vector__XXX
 SG_ IC1_AN_OT_FLT m0 : 20|1@0+ (1,0) [0|0] "" Vector__XXX
 SG_ IC1_AN_UT_FLT m0 : 19|1@0+ (1,0) [0|0] "" Vector__XXX
 SG_ IC1_CT_OV_FLT m0 : 18|1@0+ (1,0) [0|0] "" Vector__XXX
 SG_ IC1_CT_UV_FLT m0 : 17|1@0+ (1,0) [0|0] "" Vector__XXX
 SG_ IC1_POR m0 : 15|1@0+ (1,0) [0|0] "" Vector__XXX
 SG_ IC1_RESET_FLT m0 : 14|1@0+ (1,0) [0|0] "" Vector__XXX
 SG_ IC1_COM_ERR_OVR_FLT m0 : 13|1@0+ (1,0) [0|0] "" Vector__XXX
 SG_ IC1_VPWR_OV_FLT m0 : 12|1@0+ (1,0) [0|0] "" Vector__XXX
 SG_ IC1_VPWR_LV_FLT m0 : 11|1@0+ (1,0) [0|0] "" Vector__XXX
 SG_ IC1_COM_LOSS_FLT m0 : 10|1@0+ (1,0) [0|0] "" Vector__XXX
 SG_ IC1_COM_ERR_FLT m0 : 9|1@0+ (1,0) [0|0] "" Vector__XXX
 SG_ IC1_CSB_WUP_FLT m0 : 8|1@0+ (1,0) [0|0] "" Vector__XXX
 SG_ CSC15_IndexFaults M : 7|8@0+ (1,0) [0|255] "" Vector__XXX

BO_ 2550202371 CSC01_BALANCING_STATE: 8 CSC01
 SG_ Balance_State_Cell56 m0 : 63|1@0+ (1,0) [0|0] "" Vector__XXX
 SG_ Balance_State_Cell55 m0 : 62|1@0+ (1,0) [0|0] "" Vector__XXX
 SG_ Balance_State_Cell54 m0 : 61|1@0+ (1,0) [0|0] "" Vector__XXX
 SG_ Balance_State_Cell53 m0 : 60|1@0+ (1,0) [0|0] "" Vector__XXX
 SG_ Balance_State_Cell52 m0 : 59|1@0+ (1,0) [0|0] "" Vector__XXX
 SG_ Balance_State_Cell51 m0 : 58|1@0+ (1,0) [0|0] "" Vector__XXX
 SG_ Balance_State_Cell50 m0 : 57|1@0+ (1,0) [0|0] "" Vector__XXX
 SG_ Balance_State_Cell49 m0 : 56|1@0+ (1,0) [0|0] "" Vector__XXX
 SG_ Balance_State_Cell48 m0 : 55|1@0+ (1,0) [0|0] "" Vector__XXX
 SG_ Balance_State_Cell47 m0 : 54|1@0+ (1,0) [0|0] "" Vector__XXX
 SG_ Balance_State_Cell46 m0 : 53|1@0+ (1,0) [0|0] "" Vector__XXX
 SG_ Balance_State_Cell45 m0 : 52|1@0+ (1,0) [0|0] "" Vector__XXX
 SG_ Balance_State_Cell44 m0 : 51|1@0+ (1,0) [0|0] "" Vector__XXX
 SG_ Balance_State_Cell43 m0 : 50|1@0+ (1,0) [0|0] "" Vector__XXX
 SG_ Balance_State_Cell42 m0 : 49|1@0+ (1,0) [0|0] "" Vector__XXX
 SG_ Balance_State_Cell41 m0 : 48|1@0+ (1,0) [0|0] "" Vector__XXX
 SG_ Balance_State_Cell40 m0 : 47|1@0+ (1,0) [0|0] "" Vector__XXX
 SG_ Balance_State_Cell39 m0 : 46|1@0+ (1,0) [0|0] "" Vector__XXX
 SG_ Balance_State_Cell38 m0 : 45|1@0+ (1,0) [0|0] "" Vector__XXX
 SG_ Balance_State_Cell37 m0 : 44|1@0+ (1,0) [0|0] "" Vector__XXX
 SG_ Balance_State_Cell36 m0 : 43|1@0+ (1,0) [0|0] "" Vector__XXX
 SG_ Balance_State_Cell35 m0 : 42|1@0+ (1,0) [0|0] "" Vector__XXX
 SG_ Balance_State_Cell34 m0 : 41|1@0+ (1,0) [0|0] "" Vector__XXX
 SG_ Balance_State_Cell33 m0 : 40|1@0+ (1,0) [0|0] "" Vector__XXX
 SG_ Balance_State_Cell32 m0 : 39|1@0+ (1,0) [0|0] "" Vector__XXX
 SG_ Balance_State_Cell31 m0 : 38|1@0+ (1,0) [0|0] "" Vector__XXX
 SG_ Balance_State_Cell30 m0 : 37|1@0+ (1,0) [0|0] "" Vector__XXX
 SG_ Balance_State_Cell29 m0 : 36|1@0+ (1,0) [0|0] "" Vector__XXX
 SG_ Balance_State_Cell28 m0 : 35|1@0+ (1,0) [0|0] "" Vector__XXX
 SG_ Balance_State_Cell27 m0 : 34|1@0+ (1,0) [0|0] "" Vector__XXX
 SG_ Balance_State_Cell26 m0 : 33|1@0+ (1,0) [0|0] "" Vector__XXX
 SG_ Balance_State_Cell25 m0 : 32|1@0+ (1,0) [0|0] "" Vector__XXX
 SG_ Balance_State_Cell24 m0 : 31|1@0+ (1,0) [0|0] "" Vector__XXX
 SG_ Balance_State_Cell23 m0 : 30|1@0+ (1,0) [0|0] "" Vector__XXX
 SG_ Balance_State_Cell22 m0 : 29|1@0+ (1,0) [0|0] "" Vector__XXX
 SG_ Balance_State_Cell21 m0 : 28|1@0+ (1,0) [0|0] "" Vector__XXX
 SG_ Balance_State_Cell20 m0 : 27|1@0+ (1,0) [0|0] "" Vector__XXX
 SG_ Balance_State_Cell19 m0 : 26|1@0+ (1,0) [0|0] "" Vector__XXX
 SG_ Balance_State_Cell18 m0 : 25|1@0+ (1,0) [0|0] "" Vector__XXX
 SG_ Balance_State_Cell17 m0 : 24|1@0+ (1,0) [0|0] "" Vector__XXX
 SG_ Balance_State_Cell16 m0 : 23|1@0+ (1,0) [0|0] "" Vector__XXX
 SG_ Balance_State_Cell15 m0 : 22|1@0+ (1,0) [0|0] "" Vector__XXX
 SG_ Balance_State_Cell14 m0 : 21|1@0+ (1,0) [0|0] "" Vector__XXX
 SG_ Balance_State_Cell13 m0 : 20|1@0+ (1,0) [0|0] "" Vector__XXX
 SG_ Balance_State_Cell12 m0 : 19|1@0+ (1,0) [0|0] "" Vector__XXX
 SG_ Balance_State_Cell11 m0 : 18|1@0+ (1,0) [0|0] "" Vector__XXX
 SG_ Balance_State_Cell10 m0 : 17|1@0+ (1,0) [0|0] "" Vector__XXX
 SG_ Balance_State_Cell09 m0 : 16|1@0+ (1,0) [0|0] "" Vector__XXX
 SG_ Balance_State_Cell08 m0 : 15|1@0+ (1,0) [0|0] "" Vector__XXX
 SG_ Balance_State_Cell07 m0 : 14|1@0+ (1,0) [0|0] "" Vector__XXX
 SG_ Balance_State_Cell06 m0 : 13|1@0+ (1,0) [0|0] "" Vector__XXX
 SG_ Balance_State_Cell05 m0 : 12|1@0+ (1,0) [0|0] "" Vector__XXX
 SG_ Balance_State_Cell04 m0 : 11|1@0+ (1,0) [0|0] "" Vector__XXX
 SG_ Balance_State_Cell03 m0 : 10|1@0+ (1,0) [0|0] "" Vector__XXX
 SG_ Balance_State_Cell02 m0 : 9|1@0+ (1,0) [0|0] "" Vector__XXX
 SG_ Balance_State_Cell01 m0 : 8|1@0+ (1,0) [0|0] "" Vector__XXX
 SG_ CSC01_BalanceIndex M : 7|8@0+ (1,0) [0|0] "" Vector__XXX

BO_ 2550267907 CSC02_BALANCING_STATE: 8 CSC02
 SG_ Balance_State_Cell56 m0 : 63|1@0+ (1,0) [0|0] "" Vector__XXX
 SG_ Balance_State_Cell55 m0 : 62|1@0+ (1,0) [0|0] "" Vector__XXX
 SG_ Balance_State_Cell54 m0 : 61|1@0+ (1,0) [0|0] "" Vector__XXX
 SG_ Balance_State_Cell53 m0 : 60|1@0+ (1,0) [0|0] "" Vector__XXX
 SG_ Balance_State_Cell52 m0 : 59|1@0+ (1,0) [0|0] "" Vector__XXX
 SG_ Balance_State_Cell51 m0 : 58|1@0+ (1,0) [0|0] "" Vector__XXX
 SG_ Balance_State_Cell50 m0 : 57|1@0+ (1,0) [0|0] "" Vector__XXX
 SG_ Balance_State_Cell49 m0 : 56|1@0+ (1,0) [0|0] "" Vector__XXX
 SG_ Balance_State_Cell48 m0 : 55|1@0+ (1,0) [0|0] "" Vector__XXX
 SG_ Balance_State_Cell47 m0 : 54|1@0+ (1,0) [0|0] "" Vector__XXX
 SG_ Balance_State_Cell46 m0 : 53|1@0+ (1,0) [0|0] "" Vector__XXX
 SG_ Balance_State_Cell45 m0 : 52|1@0+ (1,0) [0|0] "" Vector__XXX
 SG_ Balance_State_Cell44 m0 : 51|1@0+ (1,0) [0|0] "" Vector__XXX
 SG_ Balance_State_Cell43 m0 : 50|1@0+ (1,0) [0|0] "" Vector__XXX
 SG_ Balance_State_Cell42 m0 : 49|1@0+ (1,0) [0|0] "" Vector__XXX
 SG_ Balance_State_Cell41 m0 : 48|1@0+ (1,0) [0|0] "" Vector__XXX
 SG_ Balance_State_Cell40 m0 : 47|1@0+ (1,0) [0|0] "" Vector__XXX
 SG_ Balance_State_Cell39 m0 : 46|1@0+ (1,0) [0|0] "" Vector__XXX
 SG_ Balance_State_Cell38 m0 : 45|1@0+ (1,0) [0|0] "" Vector__XXX
 SG_ Balance_State_Cell37 m0 : 44|1@0+ (1,0) [0|0] "" Vector__XXX
 SG_ Balance_State_Cell36 m0 : 43|1@0+ (1,0) [0|0] "" Vector__XXX
 SG_ Balance_State_Cell35 m0 : 42|1@0+ (1,0) [0|0] "" Vector__XXX
 SG_ Balance_State_Cell34 m0 : 41|1@0+ (1,0) [0|0] "" Vector__XXX
 SG_ Balance_State_Cell33 m0 : 40|1@0+ (1,0) [0|0] "" Vector__XXX
 SG_ Balance_State_Cell32 m0 : 39|1@0+ (1,0) [0|0] "" Vector__XXX
 SG_ Balance_State_Cell31 m0 : 38|1@0+ (1,0) [0|0] "" Vector__XXX
 SG_ Balance_State_Cell30 m0 : 37|1@0+ (1,0) [0|0] "" Vector__XXX
 SG_ Balance_State_Cell29 m0 : 36|1@0+ (1,0) [0|0] "" Vector__XXX
 SG_ Balance_State_Cell28 m0 : 35|1@0+ (1,0) [0|0] "" Vector__XXX
 SG_ Balance_State_Cell27 m0 : 34|1@0+ (1,0) [0|0] "" Vector__XXX
 SG_ Balance_State_Cell26 m0 : 33|1@0+ (1,0) [0|0] "" Vector__XXX
 SG_ Balance_State_Cell25 m0 : 32|1@0+ (1,0) [0|0] "" Vector__XXX
 SG_ Balance_State_Cell24 m0 : 31|1@0+ (1,0) [0|0] "" Vector__XXX
 SG_ Balance_State_Cell23 m0 : 30|1@0+ (1,0) [0|0] "" Vector__XXX
 SG_ Balance_State_Cell22 m0 : 29|1@0+ (1,0) [0|0] "" Vector__XXX
 SG_ Balance_State_Cell21 m0 : 28|1@0+ (1,0) [0|0] "" Vector__XXX
 SG_ Balance_State_Cell20 m0 : 27|1@0+ (1,0) [0|0] "" Vector__XXX
 SG_ Balance_State_Cell19 m0 : 26|1@0+ (1,0) [0|0] "" Vector__XXX
 SG_ Balance_State_Cell18 m0 : 25|1@0+ (1,0) [0|0] "" Vector__XXX
 SG_ Balance_State_Cell17 m0 : 24|1@0+ (1,0) [0|0] "" Vector__XXX
 SG_ Balance_State_Cell16 m0 : 23|1@0+ (1,0) [0|0] "" Vector__XXX
 SG_ Balance_State_Cell15 m0 : 22|1@0+ (1,0) [0|0] "" Vector__XXX
 SG_ Balance_State_Cell14 m0 : 21|1@0+ (1,0) [0|0] "" Vector__XXX
 SG_ Balance_State_Cell13 m0 : 20|1@0+ (1,0) [0|0] "" Vector__XXX
 SG_ Balance_State_Cell12 m0 : 19|1@0+ (1,0) [0|0] "" Vector__XXX
 SG_ Balance_State_Cell11 m0 : 18|1@0+ (1,0) [0|0] "" Vector__XXX
 SG_ Balance_State_Cell10 m0 : 17|1@0+ (1,0) [0|0] "" Vector__XXX
 SG_ Balance_State_Cell09 m0 : 16|1@0+ (1,0) [0|0] "" Vector__XXX
 SG_ Balance_State_Cell08 m0 : 15|1@0+ (1,0) [0|0] "" Vector__XXX
 SG_ Balance_State_Cell07 m0 : 14|1@0+ (1,0) [0|0] "" Vector__XXX
 SG_ Balance_State_Cell06 m0 : 13|1@0+ (1,0) [0|0] "" Vector__XXX
 SG_ Balance_State_Cell05 m0 : 12|1@0+ (1,0) [0|0] "" Vector__XXX
 SG_ Balance_State_Cell04 m0 : 11|1@0+ (1,0) [0|0] "" Vector__XXX
 SG_ Balance_State_Cell03 m0 : 10|1@0+ (1,0) [0|0] "" Vector__XXX
 SG_ Balance_State_Cell02 m0 : 9|1@0+ (1,0) [0|0] "" Vector__XXX
 SG_ Balance_State_Cell01 m0 : 8|1@0+ (1,0) [0|0] "" Vector__XXX
 SG_ CSC02_BalanceIndex M : 7|8@0+ (1,0) [0|0] "" Vector__XXX

BO_ 2550333443 CSC03_BALANCING_STATE: 8 CSC03
 SG_ Balance_State_Cell56 m0 : 63|1@0+ (1,0) [0|0] "" Vector__XXX
 SG_ Balance_State_Cell55 m0 : 62|1@0+ (1,0) [0|0] "" Vector__XXX
 SG_ Balance_State_Cell54 m0 : 61|1@0+ (1,0) [0|0] "" Vector__XXX
 SG_ Balance_State_Cell53 m0 : 60|1@0+ (1,0) [0|0] "" Vector__XXX
 SG_ Balance_State_Cell52 m0 : 59|1@0+ (1,0) [0|0] "" Vector__XXX
 SG_ Balance_State_Cell51 m0 : 58|1@0+ (1,0) [0|0] "" Vector__XXX
 SG_ Balance_State_Cell50 m0 : 57|1@0+ (1,0) [0|0] "" Vector__XXX
 SG_ Balance_State_Cell49 m0 : 56|1@0+ (1,0) [0|0] "" Vector__XXX
 SG_ Balance_State_Cell48 m0 : 55|1@0+ (1,0) [0|0] "" Vector__XXX
 SG_ Balance_State_Cell47 m0 : 54|1@0+ (1,0) [0|0] "" Vector__XXX
 SG_ Balance_State_Cell46 m0 : 53|1@0+ (1,0) [0|0] "" Vector__XXX
 SG_ Balance_State_Cell45 m0 : 52|1@0+ (1,0) [0|0] "" Vector__XXX
 SG_ Balance_State_Cell44 m0 : 51|1@0+ (1,0) [0|0] "" Vector__XXX
 SG_ Balance_State_Cell43 m0 : 50|1@0+ (1,0) [0|0] "" Vector__XXX
 SG_ Balance_State_Cell42 m0 : 49|1@0+ (1,0) [0|0] "" Vector__XXX
 SG_ Balance_State_Cell41 m0 : 48|1@0+ (1,0) [0|0] "" Vector__XXX
 SG_ Balance_State_Cell40 m0 : 47|1@0+ (1,0) [0|0] "" Vector__XXX
 SG_ Balance_State_Cell39 m0 : 46|1@0+ (1,0) [0|0] "" Vector__XXX
 SG_ Balance_State_Cell38 m0 : 45|1@0+ (1,0) [0|0] "" Vector__XXX
 SG_ Balance_State_Cell37 m0 : 44|1@0+ (1,0) [0|0] "" Vector__XXX
 SG_ Balance_State_Cell36 m0 : 43|1@0+ (1,0) [0|0] "" Vector__XXX
 SG_ Balance_State_Cell35 m0 : 42|1@0+ (1,0) [0|0] "" Vector__XXX
 SG_ Balance_State_Cell34 m0 : 41|1@0+ (1,0) [0|0] "" Vector__XXX
 SG_ Balance_State_Cell33 m0 : 40|1@0+ (1,0) [0|0] "" Vector__XXX
 SG_ Balance_State_Cell32 m0 : 39|1@0+ (1,0) [0|0] "" Vector__XXX
 SG_ Balance_State_Cell31 m0 : 38|1@0+ (1,0) [0|0] "" Vector__XXX
 SG_ Balance_State_Cell30 m0 : 37|1@0+ (1,0) [0|0] "" Vector__XXX
 SG_ Balance_State_Cell29 m0 : 36|1@0+ (1,0) [0|0] "" Vector__XXX
 SG_ Balance_State_Cell28 m0 : 35|1@0+ (1,0) [0|0] "" Vector__XXX
 SG_ Balance_State_Cell27 m0 : 34|1@0+ (1,0) [0|0] "" Vector__XXX
 SG_ Balance_State_Cell26 m0 : 33|1@0+ (1,0) [0|0] "" Vector__XXX
 SG_ Balance_State_Cell25 m0 : 32|1@0+ (1,0) [0|0] "" Vector__XXX
 SG_ Balance_State_Cell24 m0 : 31|1@0+ (1,0) [0|0] "" Vector__XXX
 SG_ Balance_State_Cell23 m0 : 30|1@0+ (1,0) [0|0] "" Vector__XXX
 SG_ Balance_State_Cell22 m0 : 29|1@0+ (1,0) [0|0] "" Vector__XXX
 SG_ Balance_State_Cell21 m0 : 28|1@0+ (1,0) [0|0] "" Vector__XXX
 SG_ Balance_State_Cell20 m0 : 27|1@0+ (1,0) [0|0] "" Vector__XXX
 SG_ Balance_State_Cell19 m0 : 26|1@0+ (1,0) [0|0] "" Vector__XXX
 SG_ Balance_State_Cell18 m0 : 25|1@0+ (1,0) [0|0] "" Vector__XXX
 SG_ Balance_State_Cell17 m0 : 24|1@0+ (1,0) [0|0] "" Vector__XXX
 SG_ Balance_State_Cell16 m0 : 23|1@0+ (1,0) [0|0] "" Vector__XXX
 SG_ Balance_State_Cell15 m0 : 22|1@0+ (1,0) [0|0] "" Vector__XXX
 SG_ Balance_State_Cell14 m0 : 21|1@0+ (1,0) [0|0] "" Vector__XXX
 SG_ Balance_State_Cell13 m0 : 20|1@0+ (1,0) [0|0] "" Vector__XXX
 SG_ Balance_State_Cell12 m0 : 19|1@0+ (1,0) [0|0] "" Vector__XXX
 SG_ Balance_State_Cell11 m0 : 18|1@0+ (1,0) [0|0] "" Vector__XXX
 SG_ Balance_State_Cell10 m0 : 17|1@0+ (1,0) [0|0] "" Vector__XXX
 SG_ Balance_State_Cell09 m0 : 16|1@0+ (1,0) [0|0] "" Vector__XXX
 SG_ Balance_State_Cell08 m0 : 15|1@0+ (1,0) [0|0] "" Vector__XXX
 SG_ Balance_State_Cell07 m0 : 14|1@0+ (1,0) [0|0] "" Vector__XXX
 SG_ Balance_State_Cell06 m0 : 13|1@0+ (1,0) [0|0] "" Vector__XXX
 SG_ Balance_State_Cell05 m0 : 12|1@0+ (1,0) [0|0] "" Vector__XXX
 SG_ Balance_State_Cell04 m0 : 11|1@0+ (1,0) [0|0] "" Vector__XXX
 SG_ Balance_State_Cell03 m0 : 10|1@0+ (1,0) [0|0] "" Vector__XXX
 SG_ Balance_State_Cell02 m0 : 9|1@0+ (1,0) [0|0] "" Vector__XXX
 SG_ Balance_State_Cell01 m0 : 8|1@0+ (1,0) [0|0] "" Vector__XXX
 SG_ CSC03_BalanceIndex M : 7|8@0+ (1,0) [0|0] "" Vector__XXX

BO_ 2550398979 CSC04_BALANCING_STATE: 8 CSC04
 SG_ Balance_State_Cell56 m0 : 63|1@0+ (1,0) [0|0] "" Vector__XXX
 SG_ Balance_State_Cell55 m0 : 62|1@0+ (1,0) [0|0] "" Vector__XXX
 SG_ Balance_State_Cell54 m0 : 61|1@0+ (1,0) [0|0] "" Vector__XXX
 SG_ Balance_State_Cell53 m0 : 60|1@0+ (1,0) [0|0] "" Vector__XXX
 SG_ Balance_State_Cell52 m0 : 59|1@0+ (1,0) [0|0] "" Vector__XXX
 SG_ Balance_State_Cell51 m0 : 58|1@0+ (1,0) [0|0] "" Vector__XXX
 SG_ Balance_State_Cell50 m0 : 57|1@0+ (1,0) [0|0] "" Vector__XXX
 SG_ Balance_State_Cell49 m0 : 56|1@0+ (1,0) [0|0] "" Vector__XXX
 SG_ Balance_State_Cell48 m0 : 55|1@0+ (1,0) [0|0] "" Vector__XXX
 SG_ Balance_State_Cell47 m0 : 54|1@0+ (1,0) [0|0] "" Vector__XXX
 SG_ Balance_State_Cell46 m0 : 53|1@0+ (1,0) [0|0] "" Vector__XXX
 SG_ Balance_State_Cell45 m0 : 52|1@0+ (1,0) [0|0] "" Vector__XXX
 SG_ Balance_State_Cell44 m0 : 51|1@0+ (1,0) [0|0] "" Vector__XXX
 SG_ Balance_State_Cell43 m0 : 50|1@0+ (1,0) [0|0] "" Vector__XXX
 SG_ Balance_State_Cell42 m0 : 49|1@0+ (1,0) [0|0] "" Vector__XXX
 SG_ Balance_State_Cell41 m0 : 48|1@0+ (1,0) [0|0] "" Vector__XXX
 SG_ Balance_State_Cell40 m0 : 47|1@0+ (1,0) [0|0] "" Vector__XXX
 SG_ Balance_State_Cell39 m0 : 46|1@0+ (1,0) [0|0] "" Vector__XXX
 SG_ Balance_State_Cell38 m0 : 45|1@0+ (1,0) [0|0] "" Vector__XXX
 SG_ Balance_State_Cell37 m0 : 44|1@0+ (1,0) [0|0] "" Vector__XXX
 SG_ Balance_State_Cell36 m0 : 43|1@0+ (1,0) [0|0] "" Vector__XXX
 SG_ Balance_State_Cell35 m0 : 42|1@0+ (1,0) [0|0] "" Vector__XXX
 SG_ Balance_State_Cell34 m0 : 41|1@0+ (1,0) [0|0] "" Vector__XXX
 SG_ Balance_State_Cell33 m0 : 40|1@0+ (1,0) [0|0] "" Vector__XXX
 SG_ Balance_State_Cell32 m0 : 39|1@0+ (1,0) [0|0] "" Vector__XXX
 SG_ Balance_State_Cell31 m0 : 38|1@0+ (1,0) [0|0] "" Vector__XXX
 SG_ Balance_State_Cell30 m0 : 37|1@0+ (1,0) [0|0] "" Vector__XXX
 SG_ Balance_State_Cell29 m0 : 36|1@0+ (1,0) [0|0] "" Vector__XXX
 SG_ Balance_State_Cell28 m0 : 35|1@0+ (1,0) [0|0] "" Vector__XXX
 SG_ Balance_State_Cell27 m0 : 34|1@0+ (1,0) [0|0] "" Vector__XXX
 SG_ Balance_State_Cell26 m0 : 33|1@0+ (1,0) [0|0] "" Vector__XXX
 SG_ Balance_State_Cell25 m0 : 32|1@0+ (1,0) [0|0] "" Vector__XXX
 SG_ Balance_State_Cell24 m0 : 31|1@0+ (1,0) [0|0] "" Vector__XXX
 SG_ Balance_State_Cell23 m0 : 30|1@0+ (1,0) [0|0] "" Vector__XXX
 SG_ Balance_State_Cell22 m0 : 29|1@0+ (1,0) [0|0] "" Vector__XXX
 SG_ Balance_State_Cell21 m0 : 28|1@0+ (1,0) [0|0] "" Vector__XXX
 SG_ Balance_State_Cell20 m0 : 27|1@0+ (1,0) [0|0] "" Vector__XXX
 SG_ Balance_State_Cell19 m0 : 26|1@0+ (1,0) [0|0] "" Vector__XXX
 SG_ Balance_State_Cell18 m0 : 25|1@0+ (1,0) [0|0] "" Vector__XXX
 SG_ Balance_State_Cell17 m0 : 24|1@0+ (1,0) [0|0] "" Vector__XXX
 SG_ Balance_State_Cell16 m0 : 23|1@0+ (1,0) [0|0] "" Vector__XXX
 SG_ Balance_State_Cell15 m0 : 22|1@0+ (1,0) [0|0] "" Vector__XXX
 SG_ Balance_State_Cell14 m0 : 21|1@0+ (1,0) [0|0] "" Vector__XXX
 SG_ Balance_State_Cell13 m0 : 20|1@0+ (1,0) [0|0] "" Vector__XXX
 SG_ Balance_State_Cell12 m0 : 19|1@0+ (1,0) [0|0] "" Vector__XXX
 SG_ Balance_State_Cell11 m0 : 18|1@0+ (1,0) [0|0] "" Vector__XXX
 SG_ Balance_State_Cell10 m0 : 17|1@0+ (1,0) [0|0] "" Vector__XXX
 SG_ Balance_State_Cell09 m0 : 16|1@0+ (1,0) [0|0] "" Vector__XXX
 SG_ Balance_State_Cell08 m0 : 15|1@0+ (1,0) [0|0] "" Vector__XXX
 SG_ Balance_State_Cell07 m0 : 14|1@0+ (1,0) [0|0] "" Vector__XXX
 SG_ Balance_State_Cell06 m0 : 13|1@0+ (1,0) [0|0] "" Vector__XXX
 SG_ Balance_State_Cell05 m0 : 12|1@0+ (1,0) [0|0] "" Vector__XXX
 SG_ Balance_State_Cell04 m0 : 11|1@0+ (1,0) [0|0] "" Vector__XXX
 SG_ Balance_State_Cell03 m0 : 10|1@0+ (1,0) [0|0] "" Vector__XXX
 SG_ Balance_State_Cell02 m0 : 9|1@0+ (1,0) [0|0] "" Vector__XXX
 SG_ Balance_State_Cell01 m0 : 8|1@0+ (1,0) [0|0] "" Vector__XXX
 SG_ CSC04_BalanceIndex M : 7|8@0+ (1,0) [0|0] "" Vector__XXX

BO_ 2550464515 CSC05_BALANCING_STATE: 8 CSC05
 SG_ Balance_State_Cell56 m0 : 63|1@0+ (1,0) [0|0] "" Vector__XXX
 SG_ Balance_State_Cell55 m0 : 62|1@0+ (1,0) [0|0] "" Vector__XXX
 SG_ Balance_State_Cell54 m0 : 61|1@0+ (1,0) [0|0] "" Vector__XXX
 SG_ Balance_State_Cell53 m0 : 60|1@0+ (1,0) [0|0] "" Vector__XXX
 SG_ Balance_State_Cell52 m0 : 59|1@0+ (1,0) [0|0] "" Vector__XXX
 SG_ Balance_State_Cell51 m0 : 58|1@0+ (1,0) [0|0] "" Vector__XXX
 SG_ Balance_State_Cell50 m0 : 57|1@0+ (1,0) [0|0] "" Vector__XXX
 SG_ Balance_State_Cell49 m0 : 56|1@0+ (1,0) [0|0] "" Vector__XXX
 SG_ Balance_State_Cell48 m0 : 55|1@0+ (1,0) [0|0] "" Vector__XXX
 SG_ Balance_State_Cell47 m0 : 54|1@0+ (1,0) [0|0] "" Vector__XXX
 SG_ Balance_State_Cell46 m0 : 53|1@0+ (1,0) [0|0] "" Vector__XXX
 SG_ Balance_State_Cell45 m0 : 52|1@0+ (1,0) [0|0] "" Vector__XXX
 SG_ Balance_State_Cell44 m0 : 51|1@0+ (1,0) [0|0] "" Vector__XXX
 SG_ Balance_State_Cell43 m0 : 50|1@0+ (1,0) [0|0] "" Vector__XXX
 SG_ Balance_State_Cell42 m0 : 49|1@0+ (1,0) [0|0] "" Vector__XXX
 SG_ Balance_State_Cell41 m0 : 48|1@0+ (1,0) [0|0] "" Vector__XXX
 SG_ Balance_State_Cell40 m0 : 47|1@0+ (1,0) [0|0] "" Vector__XXX
 SG_ Balance_State_Cell39 m0 : 46|1@0+ (1,0) [0|0] "" Vector__XXX
 SG_ Balance_State_Cell38 m0 : 45|1@0+ (1,0) [0|0] "" Vector__XXX
 SG_ Balance_State_Cell37 m0 : 44|1@0+ (1,0) [0|0] "" Vector__XXX
 SG_ Balance_State_Cell36 m0 : 43|1@0+ (1,0) [0|0] "" Vector__XXX
 SG_ Balance_State_Cell35 m0 : 42|1@0+ (1,0) [0|0] "" Vector__XXX
 SG_ Balance_State_Cell34 m0 : 41|1@0+ (1,0) [0|0] "" Vector__XXX
 SG_ Balance_State_Cell33 m0 : 40|1@0+ (1,0) [0|0] "" Vector__XXX
 SG_ Balance_State_Cell32 m0 : 39|1@0+ (1,0) [0|0] "" Vector__XXX
 SG_ Balance_State_Cell31 m0 : 38|1@0+ (1,0) [0|0] "" Vector__XXX
 SG_ Balance_State_Cell30 m0 : 37|1@0+ (1,0) [0|0] "" Vector__XXX
 SG_ Balance_State_Cell29 m0 : 36|1@0+ (1,0) [0|0] "" Vector__XXX
 SG_ Balance_State_Cell28 m0 : 35|1@0+ (1,0) [0|0] "" Vector__XXX
 SG_ Balance_State_Cell27 m0 : 34|1@0+ (1,0) [0|0] "" Vector__XXX
 SG_ Balance_State_Cell26 m0 : 33|1@0+ (1,0) [0|0] "" Vector__XXX
 SG_ Balance_State_Cell25 m0 : 32|1@0+ (1,0) [0|0] "" Vector__XXX
 SG_ Balance_State_Cell24 m0 : 31|1@0+ (1,0) [0|0] "" Vector__XXX
 SG_ Balance_State_Cell23 m0 : 30|1@0+ (1,0) [0|0] "" Vector__XXX
 SG_ Balance_State_Cell22 m0 : 29|1@0+ (1,0) [0|0] "" Vector__XXX
 SG_ Balance_State_Cell21 m0 : 28|1@0+ (1,0) [0|0] "" Vector__XXX
 SG_ Balance_State_Cell20 m0 : 27|1@0+ (1,0) [0|0] "" Vector__XXX
 SG_ Balance_State_Cell19 m0 : 26|1@0+ (1,0) [0|0] "" Vector__XXX
 SG_ Balance_State_Cell18 m0 : 25|1@0+ (1,0) [0|0] "" Vector__XXX
 SG_ Balance_State_Cell17 m0 : 24|1@0+ (1,0) [0|0] "" Vector__XXX
 SG_ Balance_State_Cell16 m0 : 23|1@0+ (1,0) [0|0] "" Vector__XXX
 SG_ Balance_State_Cell15 m0 : 22|1@0+ (1,0) [0|0] "" Vector__XXX
 SG_ Balance_State_Cell14 m0 : 21|1@0+ (1,0) [0|0] "" Vector__XXX
 SG_ Balance_State_Cell13 m0 : 20|1@0+ (1,0) [0|0] "" Vector__XXX
 SG_ Balance_State_Cell12 m0 : 19|1@0+ (1,0) [0|0] "" Vector__XXX
 SG_ Balance_State_Cell11 m0 : 18|1@0+ (1,0) [0|0] "" Vector__XXX
 SG_ Balance_State_Cell10 m0 : 17|1@0+ (1,0) [0|0] "" Vector__XXX
 SG_ Balance_State_Cell09 m0 : 16|1@0+ (1,0) [0|0] "" Vector__XXX
 SG_ Balance_State_Cell08 m0 : 15|1@0+ (1,0) [0|0] "" Vector__XXX
 SG_ Balance_State_Cell07 m0 : 14|1@0+ (1,0) [0|0] "" Vector__XXX
 SG_ Balance_State_Cell06 m0 : 13|1@0+ (1,0) [0|0] "" Vector__XXX
 SG_ Balance_State_Cell05 m0 : 12|1@0+ (1,0) [0|0] "" Vector__XXX
 SG_ Balance_State_Cell04 m0 : 11|1@0+ (1,0) [0|0] "" Vector__XXX
 SG_ Balance_State_Cell03 m0 : 10|1@0+ (1,0) [0|0] "" Vector__XXX
 SG_ Balance_State_Cell02 m0 : 9|1@0+ (1,0) [0|0] "" Vector__XXX
 SG_ Balance_State_Cell01 m0 : 8|1@0+ (1,0) [0|0] "" Vector__XXX
 SG_ CSC05_BalanceIndex M : 7|8@0+ (1,0) [0|0] "" Vector__XXX

BO_ 2550530051 CSC06_BALANCING_STATE: 8 CSC06
 SG_ Balance_State_Cell56 m0 : 63|1@0+ (1,0) [0|0] "" Vector__XXX
 SG_ Balance_State_Cell55 m0 : 62|1@0+ (1,0) [0|0] "" Vector__XXX
 SG_ Balance_State_Cell54 m0 : 61|1@0+ (1,0) [0|0] "" Vector__XXX
 SG_ Balance_State_Cell53 m0 : 60|1@0+ (1,0) [0|0] "" Vector__XXX
 SG_ Balance_State_Cell52 m0 : 59|1@0+ (1,0) [0|0] "" Vector__XXX
 SG_ Balance_State_Cell51 m0 : 58|1@0+ (1,0) [0|0] "" Vector__XXX
 SG_ Balance_State_Cell50 m0 : 57|1@0+ (1,0) [0|0] "" Vector__XXX
 SG_ Balance_State_Cell49 m0 : 56|1@0+ (1,0) [0|0] "" Vector__XXX
 SG_ Balance_State_Cell48 m0 : 55|1@0+ (1,0) [0|0] "" Vector__XXX
 SG_ Balance_State_Cell47 m0 : 54|1@0+ (1,0) [0|0] "" Vector__XXX
 SG_ Balance_State_Cell46 m0 : 53|1@0+ (1,0) [0|0] "" Vector__XXX
 SG_ Balance_State_Cell45 m0 : 52|1@0+ (1,0) [0|0] "" Vector__XXX
 SG_ Balance_State_Cell44 m0 : 51|1@0+ (1,0) [0|0] "" Vector__XXX
 SG_ Balance_State_Cell43 m0 : 50|1@0+ (1,0) [0|0] "" Vector__XXX
 SG_ Balance_State_Cell42 m0 : 49|1@0+ (1,0) [0|0] "" Vector__XXX
 SG_ Balance_State_Cell41 m0 : 48|1@0+ (1,0) [0|0] "" Vector__XXX
 SG_ Balance_State_Cell40 m0 : 47|1@0+ (1,0) [0|0] "" Vector__XXX
 SG_ Balance_State_Cell39 m0 : 46|1@0+ (1,0) [0|0] "" Vector__XXX
 SG_ Balance_State_Cell38 m0 : 45|1@0+ (1,0) [0|0] "" Vector__XXX
 SG_ Balance_State_Cell37 m0 : 44|1@0+ (1,0) [0|0] "" Vector__XXX
 SG_ Balance_State_Cell36 m0 : 43|1@0+ (1,0) [0|0] "" Vector__XXX
 SG_ Balance_State_Cell35 m0 : 42|1@0+ (1,0) [0|0] "" Vector__XXX
 SG_ Balance_State_Cell34 m0 : 41|1@0+ (1,0) [0|0] "" Vector__XXX
 SG_ Balance_State_Cell33 m0 : 40|1@0+ (1,0) [0|0] "" Vector__XXX
 SG_ Balance_State_Cell32 m0 : 39|1@0+ (1,0) [0|0] "" Vector__XXX
 SG_ Balance_State_Cell31 m0 : 38|1@0+ (1,0) [0|0] "" Vector__XXX
 SG_ Balance_State_Cell30 m0 : 37|1@0+ (1,0) [0|0] "" Vector__XXX
 SG_ Balance_State_Cell29 m0 : 36|1@0+ (1,0) [0|0] "" Vector__XXX
 SG_ Balance_State_Cell28 m0 : 35|1@0+ (1,0) [0|0] "" Vector__XXX
 SG_ Balance_State_Cell27 m0 : 34|1@0+ (1,0) [0|0] "" Vector__XXX
 SG_ Balance_State_Cell26 m0 : 33|1@0+ (1,0) [0|0] "" Vector__XXX
 SG_ Balance_State_Cell25 m0 : 32|1@0+ (1,0) [0|0] "" Vector__XXX
 SG_ Balance_State_Cell24 m0 : 31|1@0+ (1,0) [0|0] "" Vector__XXX
 SG_ Balance_State_Cell23 m0 : 30|1@0+ (1,0) [0|0] "" Vector__XXX
 SG_ Balance_State_Cell22 m0 : 29|1@0+ (1,0) [0|0] "" Vector__XXX
 SG_ Balance_State_Cell21 m0 : 28|1@0+ (1,0) [0|0] "" Vector__XXX
 SG_ Balance_State_Cell20 m0 : 27|1@0+ (1,0) [0|0] "" Vector__XXX
 SG_ Balance_State_Cell19 m0 : 26|1@0+ (1,0) [0|0] "" Vector__XXX
 SG_ Balance_State_Cell18 m0 : 25|1@0+ (1,0) [0|0] "" Vector__XXX
 SG_ Balance_State_Cell17 m0 : 24|1@0+ (1,0) [0|0] "" Vector__XXX
 SG_ Balance_State_Cell16 m0 : 23|1@0+ (1,0) [0|0] "" Vector__XXX
 SG_ Balance_State_Cell15 m0 : 22|1@0+ (1,0) [0|0] "" Vector__XXX
 SG_ Balance_State_Cell14 m0 : 21|1@0+ (1,0) [0|0] "" Vector__XXX
 SG_ Balance_State_Cell13 m0 : 20|1@0+ (1,0) [0|0] "" Vector__XXX
 SG_ Balance_State_Cell12 m0 : 19|1@0+ (1,0) [0|0] "" Vector__XXX
 SG_ Balance_State_Cell11 m0 : 18|1@0+ (1,0) [0|0] "" Vector__XXX
 SG_ Balance_State_Cell10 m0 : 17|1@0+ (1,0) [0|0] "" Vector__XXX
 SG_ Balance_State_Cell09 m0 : 16|1@0+ (1,0) [0|0] "" Vector__XXX
 SG_ Balance_State_Cell08 m0 : 15|1@0+ (1,0) [0|0] "" Vector__XXX
 SG_ Balance_State_Cell07 m0 : 14|1@0+ (1,0) [0|0] "" Vector__XXX
 SG_ Balance_State_Cell06 m0 : 13|1@0+ (1,0) [0|0] "" Vector__XXX
 SG_ Balance_State_Cell05 m0 : 12|1@0+ (1,0) [0|0] "" Vector__XXX
 SG_ Balance_State_Cell04 m0 : 11|1@0+ (1,0) [0|0] "" Vector__XXX
 SG_ Balance_State_Cell03 m0 : 10|1@0+ (1,0) [0|0] "" Vector__XXX
 SG_ Balance_State_Cell02 m0 : 9|1@0+ (1,0) [0|0] "" Vector__XXX
 SG_ Balance_State_Cell01 m0 : 8|1@0+ (1,0) [0|0] "" Vector__XXX
 SG_ CSC06_BalanceIndex M : 7|8@0+ (1,0) [0|0] "" Vector__XXX

BO_ 2550595587 CSC07_BALANCING_STATE: 8 CSC07
 SG_ Balance_State_Cell56 m0 : 63|1@0+ (1,0) [0|0] "" Vector__XXX
 SG_ Balance_State_Cell55 m0 : 62|1@0+ (1,0) [0|0] "" Vector__XXX
 SG_ Balance_State_Cell54 m0 : 61|1@0+ (1,0) [0|0] "" Vector__XXX
 SG_ Balance_State_Cell53 m0 : 60|1@0+ (1,0) [0|0] "" Vector__XXX
 SG_ Balance_State_Cell52 m0 : 59|1@0+ (1,0) [0|0] "" Vector__XXX
 SG_ Balance_State_Cell51 m0 : 58|1@0+ (1,0) [0|0] "" Vector__XXX
 SG_ Balance_State_Cell50 m0 : 57|1@0+ (1,0) [0|0] "" Vector__XXX
 SG_ Balance_State_Cell49 m0 : 56|1@0+ (1,0) [0|0] "" Vector__XXX
 SG_ Balance_State_Cell48 m0 : 55|1@0+ (1,0) [0|0] "" Vector__XXX
 SG_ Balance_State_Cell47 m0 : 54|1@0+ (1,0) [0|0] "" Vector__XXX
 SG_ Balance_State_Cell46 m0 : 53|1@0+ (1,0) [0|0] "" Vector__XXX
 SG_ Balance_State_Cell45 m0 : 52|1@0+ (1,0) [0|0] "" Vector__XXX
 SG_ Balance_State_Cell44 m0 : 51|1@0+ (1,0) [0|0] "" Vector__XXX
 SG_ Balance_State_Cell43 m0 : 50|1@0+ (1,0) [0|0] "" Vector__XXX
 SG_ Balance_State_Cell42 m0 : 49|1@0+ (1,0) [0|0] "" Vector__XXX
 SG_ Balance_State_Cell41 m0 : 48|1@0+ (1,0) [0|0] "" Vector__XXX
 SG_ Balance_State_Cell40 m0 : 47|1@0+ (1,0) [0|0] "" Vector__XXX
 SG_ Balance_State_Cell39 m0 : 46|1@0+ (1,0) [0|0] "" Vector__XXX
 SG_ Balance_State_Cell38 m0 : 45|1@0+ (1,0) [0|0] "" Vector__XXX
 SG_ Balance_State_Cell37 m0 : 44|1@0+ (1,0) [0|0] "" Vector__XXX
 SG_ Balance_State_Cell36 m0 : 43|1@0+ (1,0) [0|0] "" Vector__XXX
 SG_ Balance_State_Cell35 m0 : 42|1@0+ (1,0) [0|0] "" Vector__XXX
 SG_ Balance_State_Cell34 m0 : 41|1@0+ (1,0) [0|0] "" Vector__XXX
 SG_ Balance_State_Cell33 m0 : 40|1@0+ (1,0) [0|0] "" Vector__XXX
 SG_ Balance_State_Cell32 m0 : 39|1@0+ (1,0) [0|0] "" Vector__XXX
 SG_ Balance_State_Cell31 m0 : 38|1@0+ (1,0) [0|0] "" Vector__XXX
 SG_ Balance_State_Cell30 m0 : 37|1@0+ (1,0) [0|0] "" Vector__XXX
 SG_ Balance_State_Cell29 m0 : 36|1@0+ (1,0) [0|0] "" Vector__XXX
 SG_ Balance_State_Cell28 m0 : 35|1@0+ (1,0) [0|0] "" Vector__XXX
 SG_ Balance_State_Cell27 m0 : 34|1@0+ (1,0) [0|0] "" Vector__XXX
 SG_ Balance_State_Cell26 m0 : 33|1@0+ (1,0) [0|0] "" Vector__XXX
 SG_ Balance_State_Cell25 m0 : 32|1@0+ (1,0) [0|0] "" Vector__XXX
 SG_ Balance_State_Cell24 m0 : 31|1@0+ (1,0) [0|0] "" Vector__XXX
 SG_ Balance_State_Cell23 m0 : 30|1@0+ (1,0) [0|0] "" Vector__XXX
 SG_ Balance_State_Cell22 m0 : 29|1@0+ (1,0) [0|0] "" Vector__XXX
 SG_ Balance_State_Cell21 m0 : 28|1@0+ (1,0) [0|0] "" Vector__XXX
 SG_ Balance_State_Cell20 m0 : 27|1@0+ (1,0) [0|0] "" Vector__XXX
 SG_ Balance_State_Cell19 m0 : 26|1@0+ (1,0) [0|0] "" Vector__XXX
 SG_ Balance_State_Cell18 m0 : 25|1@0+ (1,0) [0|0] "" Vector__XXX
 SG_ Balance_State_Cell17 m0 : 24|1@0+ (1,0) [0|0] "" Vector__XXX
 SG_ Balance_State_Cell16 m0 : 23|1@0+ (1,0) [0|0] "" Vector__XXX
 SG_ Balance_State_Cell15 m0 : 22|1@0+ (1,0) [0|0] "" Vector__XXX
 SG_ Balance_State_Cell14 m0 : 21|1@0+ (1,0) [0|0] "" Vector__XXX
 SG_ Balance_State_Cell13 m0 : 20|1@0+ (1,0) [0|0] "" Vector__XXX
 SG_ Balance_State_Cell12 m0 : 19|1@0+ (1,0) [0|0] "" Vector__XXX
 SG_ Balance_State_Cell11 m0 : 18|1@0+ (1,0) [0|0] "" Vector__XXX
 SG_ Balance_State_Cell10 m0 : 17|1@0+ (1,0) [0|0] "" Vector__XXX
 SG_ Balance_State_Cell09 m0 : 16|1@0+ (1,0) [0|0] "" Vector__XXX
 SG_ Balance_State_Cell08 m0 : 15|1@0+ (1,0) [0|0] "" Vector__XXX
 SG_ Balance_State_Cell07 m0 : 14|1@0+ (1,0) [0|0] "" Vector__XXX
 SG_ Balance_State_Cell06 m0 : 13|1@0+ (1,0) [0|0] "" Vector__XXX
 SG_ Balance_State_Cell05 m0 : 12|1@0+ (1,0) [0|0] "" Vector__XXX
 SG_ Balance_State_Cell04 m0 : 11|1@0+ (1,0) [0|0] "" Vector__XXX
 SG_ Balance_State_Cell03 m0 : 10|1@0+ (1,0) [0|0] "" Vector__XXX
 SG_ Balance_State_Cell02 m0 : 9|1@0+ (1,0) [0|0] "" Vector__XXX
 SG_ Balance_State_Cell01 m0 : 8|1@0+ (1,0) [0|0] "" Vector__XXX
 SG_ CSC07_BalanceIndex M : 7|8@0+ (1,0) [0|0] "" Vector__XXX

BO_ 2550661123 CSC08_BALANCING_STATE: 8 CSC08
 SG_ Balance_State_Cell56 m0 : 63|1@0+ (1,0) [0|0] "" Vector__XXX
 SG_ Balance_State_Cell55 m0 : 62|1@0+ (1,0) [0|0] "" Vector__XXX
 SG_ Balance_State_Cell54 m0 : 61|1@0+ (1,0) [0|0] "" Vector__XXX
 SG_ Balance_State_Cell53 m0 : 60|1@0+ (1,0) [0|0] "" Vector__XXX
 SG_ Balance_State_Cell52 m0 : 59|1@0+ (1,0) [0|0] "" Vector__XXX
 SG_ Balance_State_Cell51 m0 : 58|1@0+ (1,0) [0|0] "" Vector__XXX
 SG_ Balance_State_Cell50 m0 : 57|1@0+ (1,0) [0|0] "" Vector__XXX
 SG_ Balance_State_Cell49 m0 : 56|1@0+ (1,0) [0|0] "" Vector__XXX
 SG_ Balance_State_Cell48 m0 : 55|1@0+ (1,0) [0|0] "" Vector__XXX
 SG_ Balance_State_Cell47 m0 : 54|1@0+ (1,0) [0|0] "" Vector__XXX
 SG_ Balance_State_Cell46 m0 : 53|1@0+ (1,0) [0|0] "" Vector__XXX
 SG_ Balance_State_Cell45 m0 : 52|1@0+ (1,0) [0|0] "" Vector__XXX
 SG_ Balance_State_Cell44 m0 : 51|1@0+ (1,0) [0|0] "" Vector__XXX
 SG_ Balance_State_Cell43 m0 : 50|1@0+ (1,0) [0|0] "" Vector__XXX
 SG_ Balance_State_Cell42 m0 : 49|1@0+ (1,0) [0|0] "" Vector__XXX
 SG_ Balance_State_Cell41 m0 : 48|1@0+ (1,0) [0|0] "" Vector__XXX
 SG_ Balance_State_Cell40 m0 : 47|1@0+ (1,0) [0|0] "" Vector__XXX
 SG_ Balance_State_Cell39 m0 : 46|1@0+ (1,0) [0|0] "" Vector__XXX
 SG_ Balance_State_Cell38 m0 : 45|1@0+ (1,0) [0|0] "" Vector__XXX
 SG_ Balance_State_Cell37 m0 : 44|1@0+ (1,0) [0|0] "" Vector__XXX
 SG_ Balance_State_Cell36 m0 : 43|1@0+ (1,0) [0|0] "" Vector__XXX
 SG_ Balance_State_Cell35 m0 : 42|1@0+ (1,0) [0|0] "" Vector__XXX
 SG_ Balance_State_Cell34 m0 : 41|1@0+ (1,0) [0|0] "" Vector__XXX
 SG_ Balance_State_Cell33 m0 : 40|1@0+ (1,0) [0|0] "" Vector__XXX
 SG_ Balance_State_Cell32 m0 : 39|1@0+ (1,0) [0|0] "" Vector__XXX
 SG_ Balance_State_Cell31 m0 : 38|1@0+ (1,0) [0|0] "" Vector__XXX
 SG_ Balance_State_Cell30 m0 : 37|1@0+ (1,0) [0|0] "" Vector__XXX
 SG_ Balance_State_Cell29 m0 : 36|1@0+ (1,0) [0|0] "" Vector__XXX
 SG_ Balance_State_Cell28 m0 : 35|1@0+ (1,0) [0|0] "" Vector__XXX
 SG_ Balance_State_Cell27 m0 : 34|1@0+ (1,0) [0|0] "" Vector__XXX
 SG_ Balance_State_Cell26 m0 : 33|1@0+ (1,0) [0|0] "" Vector__XXX
 SG_ Balance_State_Cell25 m0 : 32|1@0+ (1,0) [0|0] "" Vector__XXX
 SG_ Balance_State_Cell24 m0 : 31|1@0+ (1,0) [0|0] "" Vector__XXX
 SG_ Balance_State_Cell23 m0 : 30|1@0+ (1,0) [0|0] "" Vector__XXX
 SG_ Balance_State_Cell22 m0 : 29|1@0+ (1,0) [0|0] "" Vector__XXX
 SG_ Balance_State_Cell21 m0 : 28|1@0+ (1,0) [0|0] "" Vector__XXX
 SG_ Balance_State_Cell20 m0 : 27|1@0+ (1,0) [0|0] "" Vector__XXX
 SG_ Balance_State_Cell19 m0 : 26|1@0+ (1,0) [0|0] "" Vector__XXX
 SG_ Balance_State_Cell18 m0 : 25|1@0+ (1,0) [0|0] "" Vector__XXX
 SG_ Balance_State_Cell17 m0 : 24|1@0+ (1,0) [0|0] "" Vector__XXX
 SG_ Balance_State_Cell16 m0 : 23|1@0+ (1,0) [0|0] "" Vector__XXX
 SG_ Balance_State_Cell15 m0 : 22|1@0+ (1,0) [0|0] "" Vector__XXX
 SG_ Balance_State_Cell14 m0 : 21|1@0+ (1,0) [0|0] "" Vector__XXX
 SG_ Balance_State_Cell13 m0 : 20|1@0+ (1,0) [0|0] "" Vector__XXX
 SG_ Balance_State_Cell12 m0 : 19|1@0+ (1,0) [0|0] "" Vector__XXX
 SG_ Balance_State_Cell11 m0 : 18|1@0+ (1,0) [0|0] "" Vector__XXX
 SG_ Balance_State_Cell10 m0 : 17|1@0+ (1,0) [0|0] "" Vector__XXX
 SG_ Balance_State_Cell09 m0 : 16|1@0+ (1,0) [0|0] "" Vector__XXX
 SG_ Balance_State_Cell08 m0 : 15|1@0+ (1,0) [0|0] "" Vector__XXX
 SG_ Balance_State_Cell07 m0 : 14|1@0+ (1,0) [0|0] "" Vector__XXX
 SG_ Balance_State_Cell06 m0 : 13|1@0+ (1,0) [0|0] "" Vector__XXX
 SG_ Balance_State_Cell05 m0 : 12|1@0+ (1,0) [0|0] "" Vector__XXX
 SG_ Balance_State_Cell04 m0 : 11|1@0+ (1,0) [0|0] "" Vector__XXX
 SG_ Balance_State_Cell03 m0 : 10|1@0+ (1,0) [0|0] "" Vector__XXX
 SG_ Balance_State_Cell02 m0 : 9|1@0+ (1,0) [0|0] "" Vector__XXX
 SG_ Balance_State_Cell01 m0 : 8|1@0+ (1,0) [0|0] "" Vector__XXX
 SG_ CSC08_BalanceIndex M : 7|8@0+ (1,0) [0|0] "" Vector__XXX

BO_ 2550726659 CSC09_BALANCING_STATE: 8 CSC09
 SG_ Balance_State_Cell56 m0 : 63|1@0+ (1,0) [0|0] "" Vector__XXX
 SG_ Balance_State_Cell55 m0 : 62|1@0+ (1,0) [0|0] "" Vector__XXX
 SG_ Balance_State_Cell54 m0 : 61|1@0+ (1,0) [0|0] "" Vector__XXX
 SG_ Balance_State_Cell53 m0 : 60|1@0+ (1,0) [0|0] "" Vector__XXX
 SG_ Balance_State_Cell52 m0 : 59|1@0+ (1,0) [0|0] "" Vector__XXX
 SG_ Balance_State_Cell51 m0 : 58|1@0+ (1,0) [0|0] "" Vector__XXX
 SG_ Balance_State_Cell50 m0 : 57|1@0+ (1,0) [0|0] "" Vector__XXX
 SG_ Balance_State_Cell49 m0 : 56|1@0+ (1,0) [0|0] "" Vector__XXX
 SG_ Balance_State_Cell48 m0 : 55|1@0+ (1,0) [0|0] "" Vector__XXX
 SG_ Balance_State_Cell47 m0 : 54|1@0+ (1,0) [0|0] "" Vector__XXX
 SG_ Balance_State_Cell46 m0 : 53|1@0+ (1,0) [0|0] "" Vector__XXX
 SG_ Balance_State_Cell45 m0 : 52|1@0+ (1,0) [0|0] "" Vector__XXX
 SG_ Balance_State_Cell44 m0 : 51|1@0+ (1,0) [0|0] "" Vector__XXX
 SG_ Balance_State_Cell43 m0 : 50|1@0+ (1,0) [0|0] "" Vector__XXX
 SG_ Balance_State_Cell42 m0 : 49|1@0+ (1,0) [0|0] "" Vector__XXX
 SG_ Balance_State_Cell41 m0 : 48|1@0+ (1,0) [0|0] "" Vector__XXX
 SG_ Balance_State_Cell40 m0 : 47|1@0+ (1,0) [0|0] "" Vector__XXX
 SG_ Balance_State_Cell39 m0 : 46|1@0+ (1,0) [0|0] "" Vector__XXX
 SG_ Balance_State_Cell38 m0 : 45|1@0+ (1,0) [0|0] "" Vector__XXX
 SG_ Balance_State_Cell37 m0 : 44|1@0+ (1,0) [0|0] "" Vector__XXX
 SG_ Balance_State_Cell36 m0 : 43|1@0+ (1,0) [0|0] "" Vector__XXX
 SG_ Balance_State_Cell35 m0 : 42|1@0+ (1,0) [0|0] "" Vector__XXX
 SG_ Balance_State_Cell34 m0 : 41|1@0+ (1,0) [0|0] "" Vector__XXX
 SG_ Balance_State_Cell33 m0 : 40|1@0+ (1,0) [0|0] "" Vector__XXX
 SG_ Balance_State_Cell32 m0 : 39|1@0+ (1,0) [0|0] "" Vector__XXX
 SG_ Balance_State_Cell31 m0 : 38|1@0+ (1,0) [0|0] "" Vector__XXX
 SG_ Balance_State_Cell30 m0 : 37|1@0+ (1,0) [0|0] "" Vector__XXX
 SG_ Balance_State_Cell29 m0 : 36|1@0+ (1,0) [0|0] "" Vector__XXX
 SG_ Balance_State_Cell28 m0 : 35|1@0+ (1,0) [0|0] "" Vector__XXX
 SG_ Balance_State_Cell27 m0 : 34|1@0+ (1,0) [0|0] "" Vector__XXX
 SG_ Balance_State_Cell26 m0 : 33|1@0+ (1,0) [0|0] "" Vector__XXX
 SG_ Balance_State_Cell25 m0 : 32|1@0+ (1,0) [0|0] "" Vector__XXX
 SG_ Balance_State_Cell24 m0 : 31|1@0+ (1,0) [0|0] "" Vector__XXX
 SG_ Balance_State_Cell23 m0 : 30|1@0+ (1,0) [0|0] "" Vector__XXX
 SG_ Balance_State_Cell22 m0 : 29|1@0+ (1,0) [0|0] "" Vector__XXX
 SG_ Balance_State_Cell21 m0 : 28|1@0+ (1,0) [0|0] "" Vector__XXX
 SG_ Balance_State_Cell20 m0 : 27|1@0+ (1,0) [0|0] "" Vector__XXX
 SG_ Balance_State_Cell19 m0 : 26|1@0+ (1,0) [0|0] "" Vector__XXX
 SG_ Balance_State_Cell18 m0 : 25|1@0+ (1,0) [0|0] "" Vector__XXX
 SG_ Balance_State_Cell17 m0 : 24|1@0+ (1,0) [0|0] "" Vector__XXX
 SG_ Balance_State_Cell16 m0 : 23|1@0+ (1,0) [0|0] "" Vector__XXX
 SG_ Balance_State_Cell15 m0 : 22|1@0+ (1,0) [0|0] "" Vector__XXX
 SG_ Balance_State_Cell14 m0 : 21|1@0+ (1,0) [0|0] "" Vector__XXX
 SG_ Balance_State_Cell13 m0 : 20|1@0+ (1,0) [0|0] "" Vector__XXX
 SG_ Balance_State_Cell12 m0 : 19|1@0+ (1,0) [0|0] "" Vector__XXX
 SG_ Balance_State_Cell11 m0 : 18|1@0+ (1,0) [0|0] "" Vector__XXX
 SG_ Balance_State_Cell10 m0 : 17|1@0+ (1,0) [0|0] "" Vector__XXX
 SG_ Balance_State_Cell09 m0 : 16|1@0+ (1,0) [0|0] "" Vector__XXX
 SG_ Balance_State_Cell08 m0 : 15|1@0+ (1,0) [0|0] "" Vector__XXX
 SG_ Balance_State_Cell07 m0 : 14|1@0+ (1,0) [0|0] "" Vector__XXX
 SG_ Balance_State_Cell06 m0 : 13|1@0+ (1,0) [0|0] "" Vector__XXX
 SG_ Balance_State_Cell05 m0 : 12|1@0+ (1,0) [0|0] "" Vector__XXX
 SG_ Balance_State_Cell04 m0 : 11|1@0+ (1,0) [0|0] "" Vector__XXX
 SG_ Balance_State_Cell03 m0 : 10|1@0+ (1,0) [0|0] "" Vector__XXX
 SG_ Balance_State_Cell02 m0 : 9|1@0+ (1,0) [0|0] "" Vector__XXX
 SG_ Balance_State_Cell01 m0 : 8|1@0+ (1,0) [0|0] "" Vector__XXX
 SG_ CSC09_BalanceIndex M : 7|8@0+ (1,0) [0|0] "" Vector__XXX

BO_ 2550792195 CSC10_BALANCING_STATE: 8 CSC10
 SG_ Balance_State_Cell56 m0 : 63|1@0+ (1,0) [0|0] "" Vector__XXX
 SG_ Balance_State_Cell55 m0 : 62|1@0+ (1,0) [0|0] "" Vector__XXX
 SG_ Balance_State_Cell54 m0 : 61|1@0+ (1,0) [0|0] "" Vector__XXX
 SG_ Balance_State_Cell53 m0 : 60|1@0+ (1,0) [0|0] "" Vector__XXX
 SG_ Balance_State_Cell52 m0 : 59|1@0+ (1,0) [0|0] "" Vector__XXX
 SG_ Balance_State_Cell51 m0 : 58|1@0+ (1,0) [0|0] "" Vector__XXX
 SG_ Balance_State_Cell50 m0 : 57|1@0+ (1,0) [0|0] "" Vector__XXX
 SG_ Balance_State_Cell49 m0 : 56|1@0+ (1,0) [0|0] "" Vector__XXX
 SG_ Balance_State_Cell48 m0 : 55|1@0+ (1,0) [0|0] "" Vector__XXX
 SG_ Balance_State_Cell47 m0 : 54|1@0+ (1,0) [0|0] "" Vector__XXX
 SG_ Balance_State_Cell46 m0 : 53|1@0+ (1,0) [0|0] "" Vector__XXX
 SG_ Balance_State_Cell45 m0 : 52|1@0+ (1,0) [0|0] "" Vector__XXX
 SG_ Balance_State_Cell44 m0 : 51|1@0+ (1,0) [0|0] "" Vector__XXX
 SG_ Balance_State_Cell43 m0 : 50|1@0+ (1,0) [0|0] "" Vector__XXX
 SG_ Balance_State_Cell42 m0 : 49|1@0+ (1,0) [0|0] "" Vector__XXX
 SG_ Balance_State_Cell41 m0 : 48|1@0+ (1,0) [0|0] "" Vector__XXX
 SG_ Balance_State_Cell40 m0 : 47|1@0+ (1,0) [0|0] "" Vector__XXX
 SG_ Balance_State_Cell39 m0 : 46|1@0+ (1,0) [0|0] "" Vector__XXX
 SG_ Balance_State_Cell38 m0 : 45|1@0+ (1,0) [0|0] "" Vector__XXX
 SG_ Balance_State_Cell37 m0 : 44|1@0+ (1,0) [0|0] "" Vector__XXX
 SG_ Balance_State_Cell36 m0 : 43|1@0+ (1,0) [0|0] "" Vector__XXX
 SG_ Balance_State_Cell35 m0 : 42|1@0+ (1,0) [0|0] "" Vector__XXX
 SG_ Balance_State_Cell34 m0 : 41|1@0+ (1,0) [0|0] "" Vector__XXX
 SG_ Balance_State_Cell33 m0 : 40|1@0+ (1,0) [0|0] "" Vector__XXX
 SG_ Balance_State_Cell32 m0 : 39|1@0+ (1,0) [0|0] "" Vector__XXX
 SG_ Balance_State_Cell31 m0 : 38|1@0+ (1,0) [0|0] "" Vector__XXX
 SG_ Balance_State_Cell30 m0 : 37|1@0+ (1,0) [0|0] "" Vector__XXX
 SG_ Balance_State_Cell29 m0 : 36|1@0+ (1,0) [0|0] "" Vector__XXX
 SG_ Balance_State_Cell28 m0 : 35|1@0+ (1,0) [0|0] "" Vector__XXX
 SG_ Balance_State_Cell27 m0 : 34|1@0+ (1,0) [0|0] "" Vector__XXX
 SG_ Balance_State_Cell26 m0 : 33|1@0+ (1,0) [0|0] "" Vector__XXX
 SG_ Balance_State_Cell25 m0 : 32|1@0+ (1,0) [0|0] "" Vector__XXX
 SG_ Balance_State_Cell24 m0 : 31|1@0+ (1,0) [0|0] "" Vector__XXX
 SG_ Balance_State_Cell23 m0 : 30|1@0+ (1,0) [0|0] "" Vector__XXX
 SG_ Balance_State_Cell22 m0 : 29|1@0+ (1,0) [0|0] "" Vector__XXX
 SG_ Balance_State_Cell21 m0 : 28|1@0+ (1,0) [0|0] "" Vector__XXX
 SG_ Balance_State_Cell20 m0 : 27|1@0+ (1,0) [0|0] "" Vector__XXX
 SG_ Balance_State_Cell19 m0 : 26|1@0+ (1,0) [0|0] "" Vector__XXX
 SG_ Balance_State_Cell18 m0 : 25|1@0+ (1,0) [0|0] "" Vector__XXX
 SG_ Balance_State_Cell17 m0 : 24|1@0+ (1,0) [0|0] "" Vector__XXX
 SG_ Balance_State_Cell16 m0 : 23|1@0+ (1,0) [0|0] "" Vector__XXX
 SG_ Balance_State_Cell15 m0 : 22|1@0+ (1,0) [0|0] "" Vector__XXX
 SG_ Balance_State_Cell14 m0 : 21|1@0+ (1,0) [0|0] "" Vector__XXX
 SG_ Balance_State_Cell13 m0 : 20|1@0+ (1,0) [0|0] "" Vector__XXX
 SG_ Balance_State_Cell12 m0 : 19|1@0+ (1,0) [0|0] "" Vector__XXX
 SG_ Balance_State_Cell11 m0 : 18|1@0+ (1,0) [0|0] "" Vector__XXX
 SG_ Balance_State_Cell10 m0 : 17|1@0+ (1,0) [0|0] "" Vector__XXX
 SG_ Balance_State_Cell09 m0 : 16|1@0+ (1,0) [0|0] "" Vector__XXX
 SG_ Balance_State_Cell08 m0 : 15|1@0+ (1,0) [0|0] "" Vector__XXX
 SG_ Balance_State_Cell07 m0 : 14|1@0+ (1,0) [0|0] "" Vector__XXX
 SG_ Balance_State_Cell06 m0 : 13|1@0+ (1,0) [0|0] "" Vector__XXX
 SG_ Balance_State_Cell05 m0 : 12|1@0+ (1,0) [0|0] "" Vector__XXX
 SG_ Balance_State_Cell04 m0 : 11|1@0+ (1,0) [0|0] "" Vector__XXX
 SG_ Balance_State_Cell03 m0 : 10|1@0+ (1,0) [0|0] "" Vector__XXX
 SG_ Balance_State_Cell02 m0 : 9|1@0+ (1,0) [0|0] "" Vector__XXX
 SG_ Balance_State_Cell01 m0 : 8|1@0+ (1,0) [0|0] "" Vector__XXX
 SG_ CSC10_BalanceIndex M : 7|8@0+ (1,0) [0|0] "" Vector__XXX

BO_ 2550857731 CSC11_BALANCING_STATE: 8 CSC11
 SG_ Balance_State_Cell56 m0 : 63|1@0+ (1,0) [0|0] "" Vector__XXX
 SG_ Balance_State_Cell55 m0 : 62|1@0+ (1,0) [0|0] "" Vector__XXX
 SG_ Balance_State_Cell54 m0 : 61|1@0+ (1,0) [0|0] "" Vector__XXX
 SG_ Balance_State_Cell53 m0 : 60|1@0+ (1,0) [0|0] "" Vector__XXX
 SG_ Balance_State_Cell52 m0 : 59|1@0+ (1,0) [0|0] "" Vector__XXX
 SG_ Balance_State_Cell51 m0 : 58|1@0+ (1,0) [0|0] "" Vector__XXX
 SG_ Balance_State_Cell50 m0 : 57|1@0+ (1,0) [0|0] "" Vector__XXX
 SG_ Balance_State_Cell49 m0 : 56|1@0+ (1,0) [0|0] "" Vector__XXX
 SG_ Balance_State_Cell48 m0 : 55|1@0+ (1,0) [0|0] "" Vector__XXX
 SG_ Balance_State_Cell47 m0 : 54|1@0+ (1,0) [0|0] "" Vector__XXX
 SG_ Balance_State_Cell46 m0 : 53|1@0+ (1,0) [0|0] "" Vector__XXX
 SG_ Balance_State_Cell45 m0 : 52|1@0+ (1,0) [0|0] "" Vector__XXX
 SG_ Balance_State_Cell44 m0 : 51|1@0+ (1,0) [0|0] "" Vector__XXX
 SG_ Balance_State_Cell43 m0 : 50|1@0+ (1,0) [0|0] "" Vector__XXX
 SG_ Balance_State_Cell42 m0 : 49|1@0+ (1,0) [0|0] "" Vector__XXX
 SG_ Balance_State_Cell41 m0 : 48|1@0+ (1,0) [0|0] "" Vector__XXX
 SG_ Balance_State_Cell40 m0 : 47|1@0+ (1,0) [0|0] "" Vector__XXX
 SG_ Balance_State_Cell39 m0 : 46|1@0+ (1,0) [0|0] "" Vector__XXX
 SG_ Balance_State_Cell38 m0 : 45|1@0+ (1,0) [0|0] "" Vector__XXX
 SG_ Balance_State_Cell37 m0 : 44|1@0+ (1,0) [0|0] "" Vector__XXX
 SG_ Balance_State_Cell36 m0 : 43|1@0+ (1,0) [0|0] "" Vector__XXX
 SG_ Balance_State_Cell35 m0 : 42|1@0+ (1,0) [0|0] "" Vector__XXX
 SG_ Balance_State_Cell34 m0 : 41|1@0+ (1,0) [0|0] "" Vector__XXX
 SG_ Balance_State_Cell33 m0 : 40|1@0+ (1,0) [0|0] "" Vector__XXX
 SG_ Balance_State_Cell32 m0 : 39|1@0+ (1,0) [0|0] "" Vector__XXX
 SG_ Balance_State_Cell31 m0 : 38|1@0+ (1,0) [0|0] "" Vector__XXX
 SG_ Balance_State_Cell30 m0 : 37|1@0+ (1,0) [0|0] "" Vector__XXX
 SG_ Balance_State_Cell29 m0 : 36|1@0+ (1,0) [0|0] "" Vector__XXX
 SG_ Balance_State_Cell28 m0 : 35|1@0+ (1,0) [0|0] "" Vector__XXX
 SG_ Balance_State_Cell27 m0 : 34|1@0+ (1,0) [0|0] "" Vector__XXX
 SG_ Balance_State_Cell26 m0 : 33|1@0+ (1,0) [0|0] "" Vector__XXX
 SG_ Balance_State_Cell25 m0 : 32|1@0+ (1,0) [0|0] "" Vector__XXX
 SG_ Balance_State_Cell24 m0 : 31|1@0+ (1,0) [0|0] "" Vector__XXX
 SG_ Balance_State_Cell23 m0 : 30|1@0+ (1,0) [0|0] "" Vector__XXX
 SG_ Balance_State_Cell22 m0 : 29|1@0+ (1,0) [0|0] "" Vector__XXX
 SG_ Balance_State_Cell21 m0 : 28|1@0+ (1,0) [0|0] "" Vector__XXX
 SG_ Balance_State_Cell20 m0 : 27|1@0+ (1,0) [0|0] "" Vector__XXX
 SG_ Balance_State_Cell19 m0 : 26|1@0+ (1,0) [0|0] "" Vector__XXX
 SG_ Balance_State_Cell18 m0 : 25|1@0+ (1,0) [0|0] "" Vector__XXX
 SG_ Balance_State_Cell17 m0 : 24|1@0+ (1,0) [0|0] "" Vector__XXX
 SG_ Balance_State_Cell16 m0 : 23|1@0+ (1,0) [0|0] "" Vector__XXX
 SG_ Balance_State_Cell15 m0 : 22|1@0+ (1,0) [0|0] "" Vector__XXX
 SG_ Balance_State_Cell14 m0 : 21|1@0+ (1,0) [0|0] "" Vector__XXX
 SG_ Balance_State_Cell13 m0 : 20|1@0+ (1,0) [0|0] "" Vector__XXX
 SG_ Balance_State_Cell12 m0 : 19|1@0+ (1,0) [0|0] "" Vector__XXX
 SG_ Balance_State_Cell11 m0 : 18|1@0+ (1,0) [0|0] "" Vector__XXX
 SG_ Balance_State_Cell10 m0 : 17|1@0+ (1,0) [0|0] "" Vector__XXX
 SG_ Balance_State_Cell09 m0 : 16|1@0+ (1,0) [0|0] "" Vector__XXX
 SG_ Balance_State_Cell08 m0 : 15|1@0+ (1,0) [0|0] "" Vector__XXX
 SG_ Balance_State_Cell07 m0 : 14|1@0+ (1,0) [0|0] "" Vector__XXX
 SG_ Balance_State_Cell06 m0 : 13|1@0+ (1,0) [0|0] "" Vector__XXX
 SG_ Balance_State_Cell05 m0 : 12|1@0+ (1,0) [0|0] "" Vector__XXX
 SG_ Balance_State_Cell04 m0 : 11|1@0+ (1,0) [0|0] "" Vector__XXX
 SG_ Balance_State_Cell03 m0 : 10|1@0+ (1,0) [0|0] "" Vector__XXX
 SG_ Balance_State_Cell02 m0 : 9|1@0+ (1,0) [0|0] "" Vector__XXX
 SG_ Balance_State_Cell01 m0 : 8|1@0+ (1,0) [0|0] "" Vector__XXX
 SG_ CSC11_BalanceIndex M : 7|8@0+ (1,0) [0|0] "" Vector__XXX

BO_ 2550923267 CSC12_BALANCING_STATE: 8 CSC12
 SG_ Balance_State_Cell56 m0 : 63|1@0+ (1,0) [0|0] "" Vector__XXX
 SG_ Balance_State_Cell55 m0 : 62|1@0+ (1,0) [0|0] "" Vector__XXX
 SG_ Balance_State_Cell54 m0 : 61|1@0+ (1,0) [0|0] "" Vector__XXX
 SG_ Balance_State_Cell53 m0 : 60|1@0+ (1,0) [0|0] "" Vector__XXX
 SG_ Balance_State_Cell52 m0 : 59|1@0+ (1,0) [0|0] "" Vector__XXX
 SG_ Balance_State_Cell51 m0 : 58|1@0+ (1,0) [0|0] "" Vector__XXX
 SG_ Balance_State_Cell50 m0 : 57|1@0+ (1,0) [0|0] "" Vector__XXX
 SG_ Balance_State_Cell49 m0 : 56|1@0+ (1,0) [0|0] "" Vector__XXX
 SG_ Balance_State_Cell48 m0 : 55|1@0+ (1,0) [0|0] "" Vector__XXX
 SG_ Balance_State_Cell47 m0 : 54|1@0+ (1,0) [0|0] "" Vector__XXX
 SG_ Balance_State_Cell46 m0 : 53|1@0+ (1,0) [0|0] "" Vector__XXX
 SG_ Balance_State_Cell45 m0 : 52|1@0+ (1,0) [0|0] "" Vector__XXX
 SG_ Balance_State_Cell44 m0 : 51|1@0+ (1,0) [0|0] "" Vector__XXX
 SG_ Balance_State_Cell43 m0 : 50|1@0+ (1,0) [0|0] "" Vector__XXX
 SG_ Balance_State_Cell42 m0 : 49|1@0+ (1,0) [0|0] "" Vector__XXX
 SG_ Balance_State_Cell41 m0 : 48|1@0+ (1,0) [0|0] "" Vector__XXX
 SG_ Balance_State_Cell40 m0 : 47|1@0+ (1,0) [0|0] "" Vector__XXX
 SG_ Balance_State_Cell39 m0 : 46|1@0+ (1,0) [0|0] "" Vector__XXX
 SG_ Balance_State_Cell38 m0 : 45|1@0+ (1,0) [0|0] "" Vector__XXX
 SG_ Balance_State_Cell37 m0 : 44|1@0+ (1,0) [0|0] "" Vector__XXX
 SG_ Balance_State_Cell36 m0 : 43|1@0+ (1,0) [0|0] "" Vector__XXX
 SG_ Balance_State_Cell35 m0 : 42|1@0+ (1,0) [0|0] "" Vector__XXX
 SG_ Balance_State_Cell34 m0 : 41|1@0+ (1,0) [0|0] "" Vector__XXX
 SG_ Balance_State_Cell33 m0 : 40|1@0+ (1,0) [0|0] "" Vector__XXX
 SG_ Balance_State_Cell32 m0 : 39|1@0+ (1,0) [0|0] "" Vector__XXX
 SG_ Balance_State_Cell31 m0 : 38|1@0+ (1,0) [0|0] "" Vector__XXX
 SG_ Balance_State_Cell30 m0 : 37|1@0+ (1,0) [0|0] "" Vector__XXX
 SG_ Balance_State_Cell29 m0 : 36|1@0+ (1,0) [0|0] "" Vector__XXX
 SG_ Balance_State_Cell28 m0 : 35|1@0+ (1,0) [0|0] "" Vector__XXX
 SG_ Balance_State_Cell27 m0 : 34|1@0+ (1,0) [0|0] "" Vector__XXX
 SG_ Balance_State_Cell26 m0 : 33|1@0+ (1,0) [0|0] "" Vector__XXX
 SG_ Balance_State_Cell25 m0 : 32|1@0+ (1,0) [0|0] "" Vector__XXX
 SG_ Balance_State_Cell24 m0 : 31|1@0+ (1,0) [0|0] "" Vector__XXX
 SG_ Balance_State_Cell23 m0 : 30|1@0+ (1,0) [0|0] "" Vector__XXX
 SG_ Balance_State_Cell22 m0 : 29|1@0+ (1,0) [0|0] "" Vector__XXX
 SG_ Balance_State_Cell21 m0 : 28|1@0+ (1,0) [0|0] "" Vector__XXX
 SG_ Balance_State_Cell20 m0 : 27|1@0+ (1,0) [0|0] "" Vector__XXX
 SG_ Balance_State_Cell19 m0 : 26|1@0+ (1,0) [0|0] "" Vector__XXX
 SG_ Balance_State_Cell18 m0 : 25|1@0+ (1,0) [0|0] "" Vector__XXX
 SG_ Balance_State_Cell17 m0 : 24|1@0+ (1,0) [0|0] "" Vector__XXX
 SG_ Balance_State_Cell16 m0 : 23|1@0+ (1,0) [0|0] "" Vector__XXX
 SG_ Balance_State_Cell15 m0 : 22|1@0+ (1,0) [0|0] "" Vector__XXX
 SG_ Balance_State_Cell14 m0 : 21|1@0+ (1,0) [0|0] "" Vector__XXX
 SG_ Balance_State_Cell13 m0 : 20|1@0+ (1,0) [0|0] "" Vector__XXX
 SG_ Balance_State_Cell12 m0 : 19|1@0+ (1,0) [0|0] "" Vector__XXX
 SG_ Balance_State_Cell11 m0 : 18|1@0+ (1,0) [0|0] "" Vector__XXX
 SG_ Balance_State_Cell10 m0 : 17|1@0+ (1,0) [0|0] "" Vector__XXX
 SG_ Balance_State_Cell09 m0 : 16|1@0+ (1,0) [0|0] "" Vector__XXX
 SG_ Balance_State_Cell08 m0 : 15|1@0+ (1,0) [0|0] "" Vector__XXX
 SG_ Balance_State_Cell07 m0 : 14|1@0+ (1,0) [0|0] "" Vector__XXX
 SG_ Balance_State_Cell06 m0 : 13|1@0+ (1,0) [0|0] "" Vector__XXX
 SG_ Balance_State_Cell05 m0 : 12|1@0+ (1,0) [0|0] "" Vector__XXX
 SG_ Balance_State_Cell04 m0 : 11|1@0+ (1,0) [0|0] "" Vector__XXX
 SG_ Balance_State_Cell03 m0 : 10|1@0+ (1,0) [0|0] "" Vector__XXX
 SG_ Balance_State_Cell02 m0 : 9|1@0+ (1,0) [0|0] "" Vector__XXX
 SG_ Balance_State_Cell01 m0 : 8|1@0+ (1,0) [0|0] "" Vector__XXX
 SG_ CSC12_BalanceIndex M : 7|8@0+ (1,0) [0|0] "" Vector__XXX

BO_ 2550988803 CSC13_BALANCING_STATE: 8 CSC13
 SG_ Balance_State_Cell56 m0 : 63|1@0+ (1,0) [0|0] "" Vector__XXX
 SG_ Balance_State_Cell55 m0 : 62|1@0+ (1,0) [0|0] "" Vector__XXX
 SG_ Balance_State_Cell54 m0 : 61|1@0+ (1,0) [0|0] "" Vector__XXX
 SG_ Balance_State_Cell53 m0 : 60|1@0+ (1,0) [0|0] "" Vector__XXX
 SG_ Balance_State_Cell52 m0 : 59|1@0+ (1,0) [0|0] "" Vector__XXX
 SG_ Balance_State_Cell51 m0 : 58|1@0+ (1,0) [0|0] "" Vector__XXX
 SG_ Balance_State_Cell50 m0 : 57|1@0+ (1,0) [0|0] "" Vector__XXX
 SG_ Balance_State_Cell49 m0 : 56|1@0+ (1,0) [0|0] "" Vector__XXX
 SG_ Balance_State_Cell48 m0 : 55|1@0+ (1,0) [0|0] "" Vector__XXX
 SG_ Balance_State_Cell47 m0 : 54|1@0+ (1,0) [0|0] "" Vector__XXX
 SG_ Balance_State_Cell46 m0 : 53|1@0+ (1,0) [0|0] "" Vector__XXX
 SG_ Balance_State_Cell45 m0 : 52|1@0+ (1,0) [0|0] "" Vector__XXX
 SG_ Balance_State_Cell44 m0 : 51|1@0+ (1,0) [0|0] "" Vector__XXX
 SG_ Balance_State_Cell43 m0 : 50|1@0+ (1,0) [0|0] "" Vector__XXX
 SG_ Balance_State_Cell42 m0 : 49|1@0+ (1,0) [0|0] "" Vector__XXX
 SG_ Balance_State_Cell41 m0 : 48|1@0+ (1,0) [0|0] "" Vector__XXX
 SG_ Balance_State_Cell40 m0 : 47|1@0+ (1,0) [0|0] "" Vector__XXX
 SG_ Balance_State_Cell39 m0 : 46|1@0+ (1,0) [0|0] "" Vector__XXX
 SG_ Balance_State_Cell38 m0 : 45|1@0+ (1,0) [0|0] "" Vector__XXX
 SG_ Balance_State_Cell37 m0 : 44|1@0+ (1,0) [0|0] "" Vector__XXX
 SG_ Balance_State_Cell36 m0 : 43|1@0+ (1,0) [0|0] "" Vector__XXX
 SG_ Balance_State_Cell35 m0 : 42|1@0+ (1,0) [0|0] "" Vector__XXX
 SG_ Balance_State_Cell34 m0 : 41|1@0+ (1,0) [0|0] "" Vector__XXX
 SG_ Balance_State_Cell33 m0 : 40|1@0+ (1,0) [0|0] "" Vector__XXX
 SG_ Balance_State_Cell32 m0 : 39|1@0+ (1,0) [0|0] "" Vector__XXX
 SG_ Balance_State_Cell31 m0 : 38|1@0+ (1,0) [0|0] "" Vector__XXX
 SG_ Balance_State_Cell30 m0 : 37|1@0+ (1,0) [0|0] "" Vector__XXX
 SG_ Balance_State_Cell29 m0 : 36|1@0+ (1,0) [0|0] "" Vector__XXX
 SG_ Balance_State_Cell28 m0 : 35|1@0+ (1,0) [0|0] "" Vector__XXX
 SG_ Balance_State_Cell27 m0 : 34|1@0+ (1,0) [0|0] "" Vector__XXX
 SG_ Balance_State_Cell26 m0 : 33|1@0+ (1,0) [0|0] "" Vector__XXX
 SG_ Balance_State_Cell25 m0 : 32|1@0+ (1,0) [0|0] "" Vector__XXX
 SG_ Balance_State_Cell24 m0 : 31|1@0+ (1,0) [0|0] "" Vector__XXX
 SG_ Balance_State_Cell23 m0 : 30|1@0+ (1,0) [0|0] "" Vector__XXX
 SG_ Balance_State_Cell22 m0 : 29|1@0+ (1,0) [0|0] "" Vector__XXX
 SG_ Balance_State_Cell21 m0 : 28|1@0+ (1,0) [0|0] "" Vector__XXX
 SG_ Balance_State_Cell20 m0 : 27|1@0+ (1,0) [0|0] "" Vector__XXX
 SG_ Balance_State_Cell19 m0 : 26|1@0+ (1,0) [0|0] "" Vector__XXX
 SG_ Balance_State_Cell18 m0 : 25|1@0+ (1,0) [0|0] "" Vector__XXX
 SG_ Balance_State_Cell17 m0 : 24|1@0+ (1,0) [0|0] "" Vector__XXX
 SG_ Balance_State_Cell16 m0 : 23|1@0+ (1,0) [0|0] "" Vector__XXX
 SG_ Balance_State_Cell15 m0 : 22|1@0+ (1,0) [0|0] "" Vector__XXX
 SG_ Balance_State_Cell14 m0 : 21|1@0+ (1,0) [0|0] "" Vector__XXX
 SG_ Balance_State_Cell13 m0 : 20|1@0+ (1,0) [0|0] "" Vector__XXX
 SG_ Balance_State_Cell12 m0 : 19|1@0+ (1,0) [0|0] "" Vector__XXX
 SG_ Balance_State_Cell11 m0 : 18|1@0+ (1,0) [0|0] "" Vector__XXX
 SG_ Balance_State_Cell10 m0 : 17|1@0+ (1,0) [0|0] "" Vector__XXX
 SG_ Balance_State_Cell09 m0 : 16|1@0+ (1,0) [0|0] "" Vector__XXX
 SG_ Balance_State_Cell08 m0 : 15|1@0+ (1,0) [0|0] "" Vector__XXX
 SG_ Balance_State_Cell07 m0 : 14|1@0+ (1,0) [0|0] "" Vector__XXX
 SG_ Balance_State_Cell06 m0 : 13|1@0+ (1,0) [0|0] "" Vector__XXX
 SG_ Balance_State_Cell05 m0 : 12|1@0+ (1,0) [0|0] "" Vector__XXX
 SG_ Balance_State_Cell04 m0 : 11|1@0+ (1,0) [0|0] "" Vector__XXX
 SG_ Balance_State_Cell03 m0 : 10|1@0+ (1,0) [0|0] "" Vector__XXX
 SG_ Balance_State_Cell02 m0 : 9|1@0+ (1,0) [0|0] "" Vector__XXX
 SG_ Balance_State_Cell01 m0 : 8|1@0+ (1,0) [0|0] "" Vector__XXX
 SG_ CSC13_BalanceIndex M : 7|8@0+ (1,0) [0|0] "" Vector__XXX

BO_ 2551054339 CSC14_BALANCING_STATE: 8 CSC14
 SG_ Balance_State_Cell56 m0 : 63|1@0+ (1,0) [0|0] "" Vector__XXX
 SG_ Balance_State_Cell55 m0 : 62|1@0+ (1,0) [0|0] "" Vector__XXX
 SG_ Balance_State_Cell54 m0 : 61|1@0+ (1,0) [0|0] "" Vector__XXX
 SG_ Balance_State_Cell53 m0 : 60|1@0+ (1,0) [0|0] "" Vector__XXX
 SG_ Balance_State_Cell52 m0 : 59|1@0+ (1,0) [0|0] "" Vector__XXX
 SG_ Balance_State_Cell51 m0 : 58|1@0+ (1,0) [0|0] "" Vector__XXX
 SG_ Balance_State_Cell50 m0 : 57|1@0+ (1,0) [0|0] "" Vector__XXX
 SG_ Balance_State_Cell49 m0 : 56|1@0+ (1,0) [0|0] "" Vector__XXX
 SG_ Balance_State_Cell48 m0 : 55|1@0+ (1,0) [0|0] "" Vector__XXX
 SG_ Balance_State_Cell47 m0 : 54|1@0+ (1,0) [0|0] "" Vector__XXX
 SG_ Balance_State_Cell46 m0 : 53|1@0+ (1,0) [0|0] "" Vector__XXX
 SG_ Balance_State_Cell45 m0 : 52|1@0+ (1,0) [0|0] "" Vector__XXX
 SG_ Balance_State_Cell44 m0 : 51|1@0+ (1,0) [0|0] "" Vector__XXX
 SG_ Balance_State_Cell43 m0 : 50|1@0+ (1,0) [0|0] "" Vector__XXX
 SG_ Balance_State_Cell42 m0 : 49|1@0+ (1,0) [0|0] "" Vector__XXX
 SG_ Balance_State_Cell41 m0 : 48|1@0+ (1,0) [0|0] "" Vector__XXX
 SG_ Balance_State_Cell40 m0 : 47|1@0+ (1,0) [0|0] "" Vector__XXX
 SG_ Balance_State_Cell39 m0 : 46|1@0+ (1,0) [0|0] "" Vector__XXX
 SG_ Balance_State_Cell38 m0 : 45|1@0+ (1,0) [0|0] "" Vector__XXX
 SG_ Balance_State_Cell37 m0 : 44|1@0+ (1,0) [0|0] "" Vector__XXX
 SG_ Balance_State_Cell36 m0 : 43|1@0+ (1,0) [0|0] "" Vector__XXX
 SG_ Balance_State_Cell35 m0 : 42|1@0+ (1,0) [0|0] "" Vector__XXX
 SG_ Balance_State_Cell34 m0 : 41|1@0+ (1,0) [0|0] "" Vector__XXX
 SG_ Balance_State_Cell33 m0 : 40|1@0+ (1,0) [0|0] "" Vector__XXX
 SG_ Balance_State_Cell32 m0 : 39|1@0+ (1,0) [0|0] "" Vector__XXX
 SG_ Balance_State_Cell31 m0 : 38|1@0+ (1,0) [0|0] "" Vector__XXX
 SG_ Balance_State_Cell30 m0 : 37|1@0+ (1,0) [0|0] "" Vector__XXX
 SG_ Balance_State_Cell29 m0 : 36|1@0+ (1,0) [0|0] "" Vector__XXX
 SG_ Balance_State_Cell28 m0 : 35|1@0+ (1,0) [0|0] "" Vector__XXX
 SG_ Balance_State_Cell27 m0 : 34|1@0+ (1,0) [0|0] "" Vector__XXX
 SG_ Balance_State_Cell26 m0 : 33|1@0+ (1,0) [0|0] "" Vector__XXX
 SG_ Balance_State_Cell25 m0 : 32|1@0+ (1,0) [0|0] "" Vector__XXX
 SG_ Balance_State_Cell24 m0 : 31|1@0+ (1,0) [0|0] "" Vector__XXX
 SG_ Balance_State_Cell23 m0 : 30|1@0+ (1,0) [0|0] "" Vector__XXX
 SG_ Balance_State_Cell22 m0 : 29|1@0+ (1,0) [0|0] "" Vector__XXX
 SG_ Balance_State_Cell21 m0 : 28|1@0+ (1,0) [0|0] "" Vector__XXX
 SG_ Balance_State_Cell20 m0 : 27|1@0+ (1,0) [0|0] "" Vector__XXX
 SG_ Balance_State_Cell19 m0 : 26|1@0+ (1,0) [0|0] "" Vector__XXX
 SG_ Balance_State_Cell18 m0 : 25|1@0+ (1,0) [0|0] "" Vector__XXX
 SG_ Balance_State_Cell17 m0 : 24|1@0+ (1,0) [0|0] "" Vector__XXX
 SG_ Balance_State_Cell16 m0 : 23|1@0+ (1,0) [0|0] "" Vector__XXX
 SG_ Balance_State_Cell15 m0 : 22|1@0+ (1,0) [0|0] "" Vector__XXX
 SG_ Balance_State_Cell14 m0 : 21|1@0+ (1,0) [0|0] "" Vector__XXX
 SG_ Balance_State_Cell13 m0 : 20|1@0+ (1,0) [0|0] "" Vector__XXX
 SG_ Balance_State_Cell12 m0 : 19|1@0+ (1,0) [0|0] "" Vector__XXX
 SG_ Balance_State_Cell11 m0 : 18|1@0+ (1,0) [0|0] "" Vector__XXX
 SG_ Balance_State_Cell10 m0 : 17|1@0+ (1,0) [0|0] "" Vector__XXX
 SG_ Balance_State_Cell09 m0 : 16|1@0+ (1,0) [0|0] "" Vector__XXX
 SG_ Balance_State_Cell08 m0 : 15|1@0+ (1,0) [0|0] "" Vector__XXX
 SG_ Balance_State_Cell07 m0 : 14|1@0+ (1,0) [0|0] "" Vector__XXX
 SG_ Balance_State_Cell06 m0 : 13|1@0+ (1,0) [0|0] "" Vector__XXX
 SG_ Balance_State_Cell05 m0 : 12|1@0+ (1,0) [0|0] "" Vector__XXX
 SG_ Balance_State_Cell04 m0 : 11|1@0+ (1,0) [0|0] "" Vector__XXX
 SG_ Balance_State_Cell03 m0 : 10|1@0+ (1,0) [0|0] "" Vector__XXX
 SG_ Balance_State_Cell02 m0 : 9|1@0+ (1,0) [0|0] "" Vector__XXX
 SG_ Balance_State_Cell01 m0 : 8|1@0+ (1,0) [0|0] "" Vector__XXX
 SG_ CSC14_BalanceIndex M : 7|8@0+ (1,0) [0|0] "" Vector__XXX

BO_ 2551119875 CSC15_BALANCING_STATE: 8 CSC15
 SG_ Balance_State_Cell56 m0 : 63|1@0+ (1,0) [0|0] "" Vector__XXX
 SG_ Balance_State_Cell55 m0 : 62|1@0+ (1,0) [0|0] "" Vector__XXX
 SG_ Balance_State_Cell54 m0 : 61|1@0+ (1,0) [0|0] "" Vector__XXX
 SG_ Balance_State_Cell53 m0 : 60|1@0+ (1,0) [0|0] "" Vector__XXX
 SG_ Balance_State_Cell52 m0 : 59|1@0+ (1,0) [0|0] "" Vector__XXX
 SG_ Balance_State_Cell51 m0 : 58|1@0+ (1,0) [0|0] "" Vector__XXX
 SG_ Balance_State_Cell50 m0 : 57|1@0+ (1,0) [0|0] "" Vector__XXX
 SG_ Balance_State_Cell49 m0 : 56|1@0+ (1,0) [0|0] "" Vector__XXX
 SG_ Balance_State_Cell48 m0 : 55|1@0+ (1,0) [0|0] "" Vector__XXX
 SG_ Balance_State_Cell47 m0 : 54|1@0+ (1,0) [0|0] "" Vector__XXX
 SG_ Balance_State_Cell46 m0 : 53|1@0+ (1,0) [0|0] "" Vector__XXX
 SG_ Balance_State_Cell45 m0 : 52|1@0+ (1,0) [0|0] "" Vector__XXX
 SG_ Balance_State_Cell44 m0 : 51|1@0+ (1,0) [0|0] "" Vector__XXX
 SG_ Balance_State_Cell43 m0 : 50|1@0+ (1,0) [0|0] "" Vector__XXX
 SG_ Balance_State_Cell42 m0 : 49|1@0+ (1,0) [0|0] "" Vector__XXX
 SG_ Balance_State_Cell41 m0 : 48|1@0+ (1,0) [0|0] "" Vector__XXX
 SG_ Balance_State_Cell40 m0 : 47|1@0+ (1,0) [0|0] "" Vector__XXX
 SG_ Balance_State_Cell39 m0 : 46|1@0+ (1,0) [0|0] "" Vector__XXX
 SG_ Balance_State_Cell38 m0 : 45|1@0+ (1,0) [0|0] "" Vector__XXX
 SG_ Balance_State_Cell37 m0 : 44|1@0+ (1,0) [0|0] "" Vector__XXX
 SG_ Balance_State_Cell36 m0 : 43|1@0+ (1,0) [0|0] "" Vector__XXX
 SG_ Balance_State_Cell35 m0 : 42|1@0+ (1,0) [0|0] "" Vector__XXX
 SG_ Balance_State_Cell34 m0 : 41|1@0+ (1,0) [0|0] "" Vector__XXX
 SG_ Balance_State_Cell33 m0 : 40|1@0+ (1,0) [0|0] "" Vector__XXX
 SG_ Balance_State_Cell32 m0 : 39|1@0+ (1,0) [0|0] "" Vector__XXX
 SG_ Balance_State_Cell31 m0 : 38|1@0+ (1,0) [0|0] "" Vector__XXX
 SG_ Balance_State_Cell30 m0 : 37|1@0+ (1,0) [0|0] "" Vector__XXX
 SG_ Balance_State_Cell29 m0 : 36|1@0+ (1,0) [0|0] "" Vector__XXX
 SG_ Balance_State_Cell28 m0 : 35|1@0+ (1,0) [0|0] "" Vector__XXX
 SG_ Balance_State_Cell27 m0 : 34|1@0+ (1,0) [0|0] "" Vector__XXX
 SG_ Balance_State_Cell26 m0 : 33|1@0+ (1,0) [0|0] "" Vector__XXX
 SG_ Balance_State_Cell25 m0 : 32|1@0+ (1,0) [0|0] "" Vector__XXX
 SG_ Balance_State_Cell24 m0 : 31|1@0+ (1,0) [0|0] "" Vector__XXX
 SG_ Balance_State_Cell23 m0 : 30|1@0+ (1,0) [0|0] "" Vector__XXX
 SG_ Balance_State_Cell22 m0 : 29|1@0+ (1,0) [0|0] "" Vector__XXX
 SG_ Balance_State_Cell21 m0 : 28|1@0+ (1,0) [0|0] "" Vector__XXX
 SG_ Balance_State_Cell20 m0 : 27|1@0+ (1,0) [0|0] "" Vector__XXX
 SG_ Balance_State_Cell19 m0 : 26|1@0+ (1,0) [0|0] "" Vector__XXX
 SG_ Balance_State_Cell18 m0 : 25|1@0+ (1,0) [0|0] "" Vector__XXX
 SG_ Balance_State_Cell17 m0 : 24|1@0+ (1,0) [0|0] "" Vector__XXX
 SG_ Balance_State_Cell16 m0 : 23|1@0+ (1,0) [0|0] "" Vector__XXX
 SG_ Balance_State_Cell15 m0 : 22|1@0+ (1,0) [0|0] "" Vector__XXX
 SG_ Balance_State_Cell14 m0 : 21|1@0+ (1,0) [0|0] "" Vector__XXX
 SG_ Balance_State_Cell13 m0 : 20|1@0+ (1,0) [0|0] "" Vector__XXX
 SG_ Balance_State_Cell12 m0 : 19|1@0+ (1,0) [0|0] "" Vector__XXX
 SG_ Balance_State_Cell11 m0 : 18|1@0+ (1,0) [0|0] "" Vector__XXX
 SG_ Balance_State_Cell10 m0 : 17|1@0+ (1,0) [0|0] "" Vector__XXX
 SG_ Balance_State_Cell09 m0 : 16|1@0+ (1,0) [0|0] "" Vector__XXX
 SG_ Balance_State_Cell08 m0 : 15|1@0+ (1,0) [0|0] "" Vector__XXX
 SG_ Balance_State_Cell07 m0 : 14|1@0+ (1,0) [0|0] "" Vector__XXX
 SG_ Balance_State_Cell06 m0 : 13|1@0+ (1,0) [0|0] "" Vector__XXX
 SG_ Balance_State_Cell05 m0 : 12|1@0+ (1,0) [0|0] "" Vector__XXX
 SG_ Balance_State_Cell04 m0 : 11|1@0+ (1,0) [0|0] "" Vector__XXX
 SG_ Balance_State_Cell03 m0 : 10|1@0+ (1,0) [0|0] "" Vector__XXX
 SG_ Balance_State_Cell02 m0 : 9|1@0+ (1,0) [0|0] "" Vector__XXX
 SG_ Balance_State_Cell01 m0 : 8|1@0+ (1,0) [0|0] "" Vector__XXX
 SG_ CSC15_BalanceIndex M : 7|8@0+ (1,0) [0|0] "" Vector__XXX

BO_ 2550202372 CSC01_CELL_VOLT_MIN_MAX: 8 CSC01
 SG_ CSC01_Cell_Voltage_Min_Index : 55|16@0+ (1,0) [0|60] "" Vector__XXX
 SG_ CSC01_Cell_Voltage_Min : 39|16@0+ (1,0) [0|6000] "mV" Vector__XXX
 SG_ CSC01_Cell_Voltage_Max_Index : 23|16@0+ (1,0) [0|60] "" Vector__XXX
 SG_ CSC01_Cell_Voltage_Max : 7|16@0+ (1,0) [0|6000] "mV" Vector__XXX

BO_ 2550267908 CSC02_CELL_VOLT_MIN_MAX: 8 CSC02
 SG_ CSC02_Cell_Voltage_Min_Index : 55|16@0+ (1,0) [0|60] "" Vector__XXX
 SG_ CSC02_Cell_Voltage_Min : 39|16@0+ (1,0) [0|6000] "mV" Vector__XXX
 SG_ CSC02_Cell_Voltage_Max_Index : 23|16@0+ (1,0) [0|60] "" Vector__XXX
 SG_ CSC02_Cell_Voltage_Max : 7|16@0+ (1,0) [0|6000] "mV" Vector__XXX

BO_ 2550333444 CSC03_CELL_VOLT_MIN_MAX: 8 CSC03
 SG_ CSC03_Cell_Voltage_Min_Index : 55|16@0+ (1,0) [0|60] "" Vector__XXX
 SG_ CSC03_Cell_Voltage_Min : 39|16@0+ (1,0) [0|6000] "mV" Vector__XXX
 SG_ CSC03_Cell_Voltage_Max_Index : 23|16@0+ (1,0) [0|60] "" Vector__XXX
 SG_ CSC03_Cell_Voltage_Max : 7|16@0+ (1,0) [0|6000] "mV" Vector__XXX

BO_ 2550398980 CSC04_CELL_VOLT_MIN_MAX: 8 CSC04
 SG_ CSC04_Cell_Voltage_Min_Index : 55|16@0+ (1,0) [0|60] "" Vector__XXX
 SG_ CSC04_Cell_Voltage_Min : 39|16@0+ (1,0) [0|6000] "mV" Vector__XXX
 SG_ CSC04_Cell_Voltage_Max_Index : 23|16@0+ (1,0) [0|60] "" Vector__XXX
 SG_ CSC04_Cell_Voltage_Max : 7|16@0+ (1,0) [0|6000] "mV" Vector__XXX

BO_ 2550464516 CSC05_CELL_VOLT_MIN_MAX: 8 CSC05
 SG_ CSC05_Cell_Voltage_Min_Index : 55|16@0+ (1,0) [0|60] "" Vector__XXX
 SG_ CSC05_Cell_Voltage_Min : 39|16@0+ (1,0) [0|6000] "mV" Vector__XXX
 SG_ CSC05_Cell_Voltage_Max_Index : 23|16@0+ (1,0) [0|60] "" Vector__XXX
 SG_ CSC05_Cell_Voltage_Max : 7|16@0+ (1,0) [0|6000] "mV" Vector__XXX

BO_ 2550530052 CSC06_CELL_VOLT_MIN_MAX: 8 CSC06
 SG_ CSC06_Cell_Voltage_Min_Index : 55|16@0+ (1,0) [0|60] "" Vector__XXX
 SG_ CSC06_Cell_Voltage_Min : 39|16@0+ (1,0) [0|6000] "mV" Vector__XXX
 SG_ CSC06_Cell_Voltage_Max_Index : 23|16@0+ (1,0) [0|60] "" Vector__XXX
 SG_ CSC06_Cell_Voltage_Max : 7|16@0+ (1,0) [0|6000] "mV" Vector__XXX

BO_ 2550595588 CSC07_CELL_VOLT_MIN_MAX: 8 CSC07
 SG_ CSC07_Cell_Voltage_Min_Index : 55|16@0+ (1,0) [0|60] "" Vector__XXX
 SG_ CSC07_Cell_Voltage_Min : 39|16@0+ (1,0) [0|6000] "mV" Vector__XXX
 SG_ CSC07_Cell_Voltage_Max_Index : 23|16@0+ (1,0) [0|60] "" Vector__XXX
 SG_ CSC07_Cell_Voltage_Max : 7|16@0+ (1,0) [0|6000] "mV" Vector__XXX

BO_ 2550661124 CSC08_CELL_VOLT_MIN_MAX: 8 CSC08
 SG_ CSC08_Cell_Voltage_Min_Index : 55|16@0+ (1,0) [0|60] "" Vector__XXX
 SG_ CSC08_Cell_Voltage_Min : 39|16@0+ (1,0) [0|6000] "mV" Vector__XXX
 SG_ CSC08_Cell_Voltage_Max_Index : 23|16@0+ (1,0) [0|60] "" Vector__XXX
 SG_ CSC08_Cell_Voltage_Max : 7|16@0+ (1,0) [0|6000] "mV" Vector__XXX

BO_ 2550726660 CSC09_CELL_VOLT_MIN_MAX: 8 CSC09
 SG_ CSC09_Cell_Voltage_Min_Index : 55|16@0+ (1,0) [0|60] "" Vector__XXX
 SG_ CSC09_Cell_Voltage_Min : 39|16@0+ (1,0) [0|6000] "mV" Vector__XXX
 SG_ CSC09_Cell_Voltage_Max_Index : 23|16@0+ (1,0) [0|60] "" Vector__XXX
 SG_ CSC09_Cell_Voltage_Max : 7|16@0+ (1,0) [0|6000] "mV" Vector__XXX

BO_ 2550792196 CSC10_CELL_VOLT_MIN_MAX: 8 CSC10
 SG_ CSC10_Cell_Voltage_Min_Index : 55|16@0+ (1,0) [0|60] "" Vector__XXX
 SG_ CSC10_Cell_Voltage_Min : 39|16@0+ (1,0) [0|6000] "mV" Vector__XXX
 SG_ CSC10_Cell_Voltage_Max_Index : 23|16@0+ (1,0) [0|60] "" Vector__XXX
 SG_ CSC10_Cell_Voltage_Max : 7|16@0+ (1,0) [0|6000] "mV" Vector__XXX

BO_ 2550857732 CSC11_CELL_VOLT_MIN_MAX: 8 CSC11
 SG_ CSC11_Cell_Voltage_Min_Index : 55|16@0+ (1,0) [0|60] "" Vector__XXX
 SG_ CSC11_Cell_Voltage_Min : 39|16@0+ (1,0) [0|6000] "mV" Vector__XXX
 SG_ CSC11_Cell_Voltage_Max_Index : 23|16@0+ (1,0) [0|60] "" Vector__XXX
 SG_ CSC11_Cell_Voltage_Max : 7|16@0+ (1,0) [0|6000] "mV" Vector__XXX

BO_ 2550923268 CSC12_CELL_VOLT_MIN_MAX: 8 CSC12
 SG_ CSC12_Cell_Voltage_Min_Index : 55|16@0+ (1,0) [0|60] "" Vector__XXX
 SG_ CSC12_Cell_Voltage_Min : 39|16@0+ (1,0) [0|6000] "mV" Vector__XXX
 SG_ CSC12_Cell_Voltage_Max_Index : 23|16@0+ (1,0) [0|60] "" Vector__XXX
 SG_ CSC12_Cell_Voltage_Max : 7|16@0+ (1,0) [0|6000] "mV" Vector__XXX

BO_ 2550988804 CSC13_CELL_VOLT_MIN_MAX: 8 CSC13
 SG_ CSC13_Cell_Voltage_Min_Index : 55|16@0+ (1,0) [0|60] "" Vector__XXX
 SG_ CSC13_Cell_Voltage_Min : 39|16@0+ (1,0) [0|6000] "mV" Vector__XXX
 SG_ CSC13_Cell_Voltage_Max_Index : 23|16@0+ (1,0) [0|60] "" Vector__XXX
 SG_ CSC13_Cell_Voltage_Max : 7|16@0+ (1,0) [0|6000] "mV" Vector__XXX

BO_ 2551054340 CSC14_CELL_VOLT_MIN_MAX: 8 CSC14
 SG_ CSC14_Cell_Voltage_Min_Index : 55|16@0+ (1,0) [0|60] "" Vector__XXX
 SG_ CSC14_Cell_Voltage_Min : 39|16@0+ (1,0) [0|6000] "mV" Vector__XXX
 SG_ CSC14_Cell_Voltage_Max_Index : 23|16@0+ (1,0) [0|60] "" Vector__XXX
 SG_ CSC14_Cell_Voltage_Max : 7|16@0+ (1,0) [0|6000] "mV" Vector__XXX

BO_ 2551119876 CSC15_CELL_VOLT_MIN_MAX: 8 CSC15
 SG_ CSC15_Cell_Voltage_Min_Index : 55|16@0+ (1,0) [0|60] "" Vector__XXX
 SG_ CSC15_Cell_Voltage_Min : 39|16@0+ (1,0) [0|6000] "mV" Vector__XXX
 SG_ CSC15_Cell_Voltage_Max_Index : 23|16@0+ (1,0) [0|60] "" Vector__XXX
 SG_ CSC15_Cell_Voltage_Max : 7|16@0+ (1,0) [0|6000] "mV" Vector__XXX

BO_ 2550202373 CSC01_CELL_TEMP_MIN_MAX: 8 CSC01
 SG_ CSC01_Cell_Temp_Min_Index : 39|16@0+ (1,0) [0|65535] "" Vector__XXX
 SG_ CSC01_Cell_Temp_Max_Index : 15|16@0+ (1,0) [0|65535] "" Vector__XXX
 SG_ CSC01_Cell_Temp_Min : 31|8@0+ (1,-40) [-40|215] "degC" Vector__XXX
 SG_ CSC01_Cell_Temp_Max : 7|8@0+ (1,-40) [-40|215] "degC" Vector__XXX

BO_ 2550267909 CSC02_CELL_TEMP_MIN_MAX: 8 CSC02
 SG_ CSC02_Cell_Temp_Min_Index : 39|16@0+ (1,0) [0|65535] "" Vector__XXX
 SG_ CSC02_Cell_Temp_Max_Index : 15|16@0+ (1,0) [0|65535] "" Vector__XXX
 SG_ CSC02_Cell_Temp_Min : 31|8@0+ (1,-40) [-40|215] "degC" Vector__XXX
 SG_ CSC02_Cell_Temp_Max : 7|8@0+ (1,-40) [-40|215] "degC" Vector__XXX

BO_ 2550333445 CSC03_CELL_TEMP_MIN_MAX: 8 CSC03
 SG_ CSC03_Cell_Temp_Min_Index : 39|16@0+ (1,0) [0|65535] "" Vector__XXX
 SG_ CSC03_Cell_Temp_Max_Index : 15|16@0+ (1,0) [0|65535] "" Vector__XXX
 SG_ CSC03_Cell_Temp_Min : 31|8@0+ (1,-40) [-40|215] "degC" Vector__XXX
 SG_ CSC03_Cell_Temp_Max : 7|8@0+ (1,-40) [-40|215] "degC" Vector__XXX

BO_ 2550398981 CSC04_CELL_TEMP_MIN_MAX: 8 CSC04
 SG_ CSC04_Cell_Temp_Min_Index : 39|16@0+ (1,0) [0|65535] "" Vector__XXX
 SG_ CSC04_Cell_Temp_Max_Index : 15|16@0+ (1,0) [0|65535] "" Vector__XXX
 SG_ CSC04_Cell_Temp_Min : 31|8@0+ (1,-40) [-40|215] "degC" Vector__XXX
 SG_ CSC04_Cell_Temp_Max : 7|8@0+ (1,-40) [-40|215] "degC" Vector__XXX

BO_ 2550464517 CSC05_CELL_TEMP_MIN_MAX: 8 CSC05
 SG_ CSC05_Cell_Temp_Min_Index : 39|16@0+ (1,0) [0|65535] "" Vector__XXX
 SG_ CSC05_Cell_Temp_Max_Index : 15|16@0+ (1,0) [0|65535] "" Vector__XXX
 SG_ CSC05_Cell_Temp_Min : 31|8@0+ (1,-40) [-40|215] "degC" Vector__XXX
 SG_ CSC05_Cell_Temp_Max : 7|8@0+ (1,-40) [-40|215] "degC" Vector__XXX

BO_ 2550530053 CSC06_CELL_TEMP_MIN_MAX: 8 CSC06
 SG_ CSC06_Cell_Temp_Min_Index : 39|16@0+ (1,0) [0|65535] "" Vector__XXX
 SG_ CSC06_Cell_Temp_Max_Index : 15|16@0+ (1,0) [0|65535] "" Vector__XXX
 SG_ CSC06_Cell_Temp_Min : 31|8@0+ (1,-40) [-40|215] "degC" Vector__XXX
 SG_ CSC06_Cell_Temp_Max : 7|8@0+ (1,-40) [-40|215] "degC" Vector__XXX

BO_ 2550595589 CSC07_CELL_TEMP_MIN_MAX: 8 CSC07
 SG_ CSC07_Cell_Temp_Min_Index : 39|16@0+ (1,0) [0|65535] "" Vector__XXX
 SG_ CSC07_Cell_Temp_Max_Index : 15|16@0+ (1,0) [0|65535] "" Vector__XXX
 SG_ CSC07_Cell_Temp_Min : 31|8@0+ (1,-40) [-40|215] "degC" Vector__XXX
 SG_ CSC07_Cell_Temp_Max : 7|8@0+ (1,-40) [-40|215] "degC" Vector__XXX

BO_ 2550661125 CSC08_CELL_TEMP_MIN_MAX: 8 CSC08
 SG_ CSC08_Cell_Temp_Min_Index : 39|16@0+ (1,0) [0|65535] "" Vector__XXX
 SG_ CSC08_Cell_Temp_Max_Index : 15|16@0+ (1,0) [0|65535] "" Vector__XXX
 SG_ CSC08_Cell_Temp_Min : 31|8@0+ (1,-40) [-40|215] "degC" Vector__XXX
 SG_ CSC08_Cell_Temp_Max : 7|8@0+ (1,-40) [-40|215] "degC" Vector__XXX

BO_ 2550726661 CSC09_CELL_TEMP_MIN_MAX: 8 CSC09
 SG_ CSC09_Cell_Temp_Min_Index : 39|16@0+ (1,0) [0|65535] "" Vector__XXX
 SG_ CSC09_Cell_Temp_Max_Index : 15|16@0+ (1,0) [0|65535] "" Vector__XXX
 SG_ CSC09_Cell_Temp_Min : 31|8@0+ (1,-40) [-40|215] "degC" Vector__XXX
 SG_ CSC09_Cell_Temp_Max : 7|8@0+ (1,-40) [-40|215] "degC" Vector__XXX

BO_ 2550792197 CSC10_CELL_TEMP_MIN_MAX: 8 CSC10
 SG_ CSC10_Cell_Temp_Min_Index : 39|16@0+ (1,0) [0|65535] "" Vector__XXX
 SG_ CSC10_Cell_Temp_Max_Index : 15|16@0+ (1,0) [0|65535] "" Vector__XXX
 SG_ CSC10_Cell_Temp_Min : 31|8@0+ (1,-40) [-40|215] "degC" Vector__XXX
 SG_ CSC10_Cell_Temp_Max : 7|8@0+ (1,-40) [-40|215] "degC" Vector__XXX

BO_ 2550857733 CSC11_CELL_TEMP_MIN_MAX: 8 CSC11
 SG_ CSC11_Cell_Temp_Min_Index : 39|16@0+ (1,0) [0|65535] "" Vector__XXX
 SG_ CSC11_Cell_Temp_Max_Index : 15|16@0+ (1,0) [0|65535] "" Vector__XXX
 SG_ CSC11_Cell_Temp_Min : 31|8@0+ (1,-40) [-40|215] "degC" Vector__XXX
 SG_ CSC11_Cell_Temp_Max : 7|8@0+ (1,-40) [-40|215] "degC" Vector__XXX

BO_ 2550923269 CSC12_CELL_TEMP_MIN_MAX: 8 CSC12
 SG_ CSC12_Cell_Temp_Min_Index : 39|16@0+ (1,0) [0|65535] "" Vector__XXX
 SG_ CSC12_Cell_Temp_Max_Index : 15|16@0+ (1,0) [0|65535] "" Vector__XXX
 SG_ CSC12_Cell_Temp_Min : 31|8@0+ (1,-40) [-40|215] "degC" Vector__XXX
 SG_ CSC12_Cell_Temp_Max : 7|8@0+ (1,-40) [-40|215] "degC" Vector__XXX

BO_ 2550988805 CSC13_CELL_TEMP_MIN_MAX: 8 CSC13
 SG_ CSC13_Cell_Temp_Min_Index : 39|16@0+ (1,0) [0|65535] "" Vector__XXX
 SG_ CSC13_Cell_Temp_Max_Index : 15|16@0+ (1,0) [0|65535] "" Vector__XXX
 SG_ CSC13_Cell_Temp_Min : 31|8@0+ (1,-40) [-40|215] "degC" Vector__XXX
 SG_ CSC13_Cell_Temp_Max : 7|8@0+ (1,-40) [-40|215] "degC" Vector__XXX

BO_ 2551054341 CSC14_CELL_TEMP_MIN_MAX: 8 CSC14
 SG_ CSC14_Cell_Temp_Min_Index : 39|16@0+ (1,0) [0|65535] "" Vector__XXX
 SG_ CSC14_Cell_Temp_Max_Index : 15|16@0+ (1,0) [0|65535] "" Vector__XXX
 SG_ CSC14_Cell_Temp_Min : 31|8@0+ (1,-40) [-40|215] "degC" Vector__XXX
 SG_ CSC14_Cell_Temp_Max : 7|8@0+ (1,-40) [-40|215] "degC" Vector__XXX

BO_ 2551119877 CSC15_CELL_TEMP_MIN_MAX: 8 CSC15
 SG_ CSC15_Cell_Temp_Min_Index : 39|16@0+ (1,0) [0|65535] "" Vector__XXX
 SG_ CSC15_Cell_Temp_Max_Index : 15|16@0+ (1,0) [0|65535] "" Vector__XXX
 SG_ CSC15_Cell_Temp_Min : 31|8@0+ (1,-40) [-40|215] "degC" Vector__XXX
 SG_ CSC15_Cell_Temp_Max : 7|8@0+ (1,-40) [-40|215] "degC" Vector__XXX

BO_ 2550202374 CSC01_CELL_SUM_AVE: 8 CSC01
 SG_ CSC01_Cell_Voltage_Sum : 31|16@0+ (0.01,0) [0|360] "V" Vector__XXX
 SG_ CSC01_Cell_Voltage_Average : 7|16@0+ (1,0) [0|6000] "mV" Vector__XXX
 SG_ CSC01_Cell_Temp_Average : 23|8@0+ (1,-40) [-40|215] "degC" Vector__XXX

BO_ 2550267910 CSC02_CELL_SUM_AVE: 8 CSC02
 SG_ CSC02_Cell_Voltage_Sum : 31|16@0+ (0.01,0) [0|360] "V" Vector__XXX
 SG_ CSC02_Cell_Voltage_Average : 7|16@0+ (1,0) [0|6000] "mV" Vector__XXX
 SG_ CSC02_Cell_Temp_Average : 23|8@0+ (1,-40) [-40|215] "degC" Vector__XXX

BO_ 2550333446 CSC03_CELL_SUM_AVE: 8 CSC03
 SG_ CSC03_Cell_Voltage_Sum : 31|16@0+ (0.01,0) [0|360] "V" Vector__XXX
 SG_ CSC03_Cell_Voltage_Average : 7|16@0+ (1,0) [0|6000] "mV" Vector__XXX
 SG_ CSC03_Cell_Temp_Average : 23|8@0+ (1,-40) [-40|215] "degC" Vector__XXX

BO_ 2550398982 CSC04_CELL_SUM_AVE: 8 CSC04
 SG_ CSC04_Cell_Voltage_Sum : 31|16@0+ (0.01,0) [0|360] "V" Vector__XXX
 SG_ CSC04_Cell_Voltage_Average : 7|16@0+ (1,0) [0|6000] "mV" Vector__XXX
 SG_ CSC04_Cell_Temp_Average : 23|8@0+ (1,-40) [-40|215] "degC" Vector__XXX

BO_ 2550464518 CSC05_CELL_SUM_AVE: 8 CSC05
 SG_ CSC05_Cell_Voltage_Sum : 31|16@0+ (0.01,0) [0|360] "V" Vector__XXX
 SG_ CSC05_Cell_Voltage_Average : 7|16@0+ (1,0) [0|6000] "mV" Vector__XXX
 SG_ CSC05_Cell_Temp_Average : 23|8@0+ (1,-40) [-40|215] "degC" Vector__XXX

BO_ 2550530054 CSC06_CELL_SUM_AVE: 8 CSC06
 SG_ CSC06_Cell_Voltage_Sum : 31|16@0+ (0.01,0) [0|360] "V" Vector__XXX
 SG_ CSC06_Cell_Voltage_Average : 7|16@0+ (1,0) [0|6000] "mV" Vector__XXX
 SG_ CSC06_Cell_Temp_Average : 23|8@0+ (1,-40) [-40|215] "degC" Vector__XXX

BO_ 2550595590 CSC07_CELL_SUM_AVE: 8 CSC07
 SG_ CSC07_Cell_Voltage_Sum : 31|16@0+ (0.01,0) [0|360] "V" Vector__XXX
 SG_ CSC07_Cell_Voltage_Average : 7|16@0+ (1,0) [0|6000] "mV" Vector__XXX
 SG_ CSC07_Cell_Temp_Average : 23|8@0+ (1,-40) [-40|215] "degC" Vector__XXX

BO_ 2550661126 CSC08_CELL_SUM_AVE: 8 CSC08
 SG_ CSC08_Cell_Voltage_Sum : 31|16@0+ (0.01,0) [0|360] "V" Vector__XXX
 SG_ CSC08_Cell_Voltage_Average : 7|16@0+ (1,0) [0|6000] "mV" Vector__XXX
 SG_ CSC08_Cell_Temp_Average : 23|8@0+ (1,-40) [-40|215] "degC" Vector__XXX

BO_ 2550726662 CSC09_CELL_SUM_AVE: 8 CSC09
 SG_ CSC09_Cell_Voltage_Sum : 31|16@0+ (0.01,0) [0|360] "V" Vector__XXX
 SG_ CSC09_Cell_Voltage_Average : 7|16@0+ (1,0) [0|6000] "mV" Vector__XXX
 SG_ CSC09_Cell_Temp_Average : 23|8@0+ (1,-40) [-40|215] "degC" Vector__XXX

BO_ 2550792198 CSC10_CELL_SUM_AVE: 8 CSC10
 SG_ CSC10_Cell_Voltage_Sum : 31|16@0+ (0.01,0) [0|360] "V" Vector__XXX
 SG_ CSC10_Cell_Voltage_Average : 7|16@0+ (1,0) [0|6000] "mV" Vector__XXX
 SG_ CSC10_Cell_Temp_Average : 23|8@0+ (1,-40) [-40|215] "degC" Vector__XXX

BO_ 2550857734 CSC11_CELL_SUM_AVE: 8 CSC11
 SG_ CSC11_Cell_Voltage_Sum : 31|16@0+ (0.01,0) [0|360] "V" Vector__XXX
 SG_ CSC11_Cell_Voltage_Average : 7|16@0+ (1,0) [0|6000] "mV" Vector__XXX
 SG_ CSC11_Cell_Temp_Average : 23|8@0+ (1,-40) [-40|215] "degC" Vector__XXX

BO_ 2550923270 CSC12_CELL_SUM_AVE: 8 CSC12
 SG_ CSC12_Cell_Voltage_Sum : 31|16@0+ (0.01,0) [0|360] "V" Vector__XXX
 SG_ CSC12_Cell_Voltage_Average : 7|16@0+ (1,0) [0|6000] "mV" Vector__XXX
 SG_ CSC12_Cell_Temp_Average : 23|8@0+ (1,-40) [-40|215] "degC" Vector__XXX

BO_ 2550988806 CSC13_CELL_SUM_AVE: 8 CSC13
 SG_ CSC13_Cell_Voltage_Sum : 31|16@0+ (0.01,0) [0|360] "V" Vector__XXX
 SG_ CSC13_Cell_Voltage_Average : 7|16@0+ (1,0) [0|6000] "mV" Vector__XXX
 SG_ CSC13_Cell_Temp_Average : 23|8@0+ (1,-40) [-40|215] "degC" Vector__XXX

BO_ 2551054342 CSC14_CELL_SUM_AVE: 8 CSC14
 SG_ CSC14_Cell_Voltage_Sum : 31|16@0+ (0.01,0) [0|360] "V" Vector__XXX
 SG_ CSC14_Cell_Voltage_Average : 7|16@0+ (1,0) [0|6000] "mV" Vector__XXX
 SG_ CSC14_Cell_Temp_Average : 23|8@0+ (1,-40) [-40|215] "degC" Vector__XXX

BO_ 2551119878 CSC15_CELL_SUM_AVE: 8 CSC15
 SG_ CSC15_Cell_Voltage_Sum : 31|16@0+ (0.01,0) [0|360] "V" Vector__XXX
 SG_ CSC15_Cell_Voltage_Average : 7|16@0+ (1,0) [0|6000] "mV" Vector__XXX
 SG_ CSC15_Cell_Temp_Average : 23|8@0+ (1,-40) [-40|215] "degC" Vector__XXX

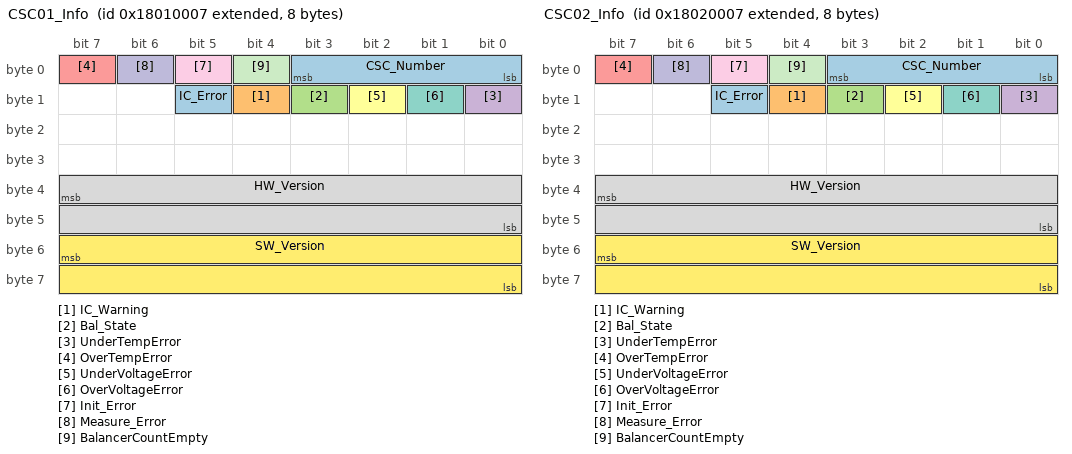
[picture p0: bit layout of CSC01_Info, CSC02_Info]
BO_ 2550202375 CSC01_Info: 8 CSC01
 SG_ IC_Error : 13|1@0+ (1,0) [0|0] "" Vector__XXX
 SG_ IC_Warning : 12|1@0+ (1,0) [0|0] "" Vector__XXX
 SG_ Bal_State : 11|1@0+ (1,0) [0|0] "" Vector__XXX
 SG_ UnderTempError : 8|1@0+ (1,0) [0|0] "" Vector__XXX
 SG_ OverTempError : 7|1@0+ (1,0) [0|0] "" Vector__XXX
 SG_ UnderVoltageError : 10|1@0+ (1,0) [0|0] "" Vector__XXX
 SG_ OverVoltageError : 9|1@0+ (1,0) [0|0] "" Vector__XXX
 SG_ HW_Version : 39|16@0+ (1,0) [0|0] "" Vector__XXX
 SG_ Init_Error : 5|1@0+ (1,0) [0|0] "" Vector__XXX
 SG_ Measure_Error : 6|1@0+ (1,0) [0|0] "" Vector__XXX
 SG_ BalancerCountEmpty : 4|1@0+ (1,0) [0|0] "" Vector__XXX
 SG_ SW_Version : 55|16@0+ (1,0) [0|0] "" Vector__XXX
 SG_ CSC_Number : 3|4@0+ (1,0) [0|0] "" Vector__XXX

BO_ 2550267911 CSC02_Info: 8 CSC02
 SG_ IC_Error : 13|1@0+ (1,0) [0|0] "" Vector__XXX
 SG_ IC_Warning : 12|1@0+ (1,0) [0|0] "" Vector__XXX
 SG_ Bal_State : 11|1@0+ (1,0) [0|0] "" Vector__XXX
 SG_ UnderTempError : 8|1@0+ (1,0) [0|0] "" Vector__XXX
 SG_ OverTempError : 7|1@0+ (1,0) [0|0] "" Vector__XXX
 SG_ UnderVoltageError : 10|1@0+ (1,0) [0|0] "" Vector__XXX
 SG_ OverVoltageError : 9|1@0+ (1,0) [0|0] "" Vector__XXX
 SG_ HW_Version : 39|16@0+ (1,0) [0|0] "" Vector__XXX
 SG_ Init_Error : 5|1@0+ (1,0) [0|0] "" Vector__XXX
 SG_ Measure_Error : 6|1@0+ (1,0) [0|0] "" Vector__XXX
 SG_ BalancerCountEmpty : 4|1@0+ (1,0) [0|0] "" Vector__XXX
 SG_ SW_Version : 55|16@0+ (1,0) [0|0] "" Vector__XXX
 SG_ CSC_Number : 3|4@0+ (1,0) [0|0] "" Vector__XXX

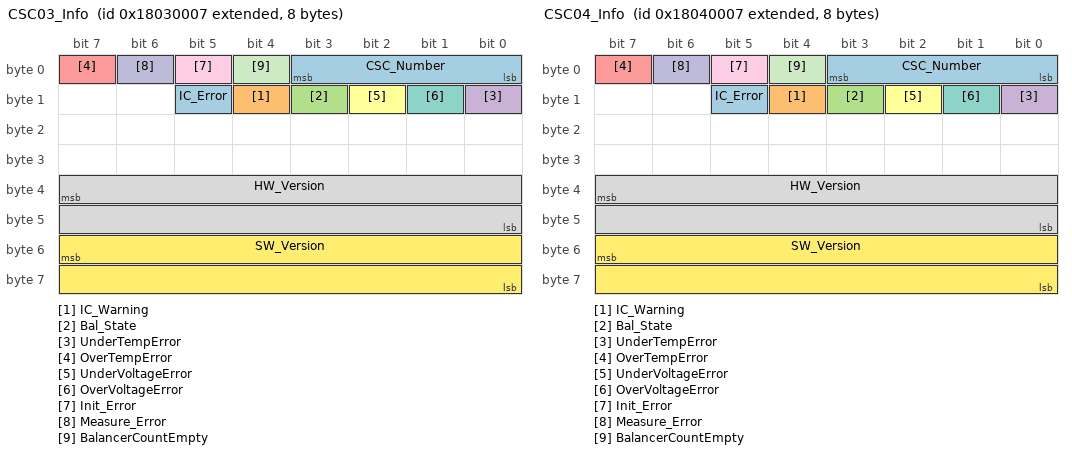
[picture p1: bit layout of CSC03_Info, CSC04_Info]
BO_ 2550333447 CSC03_Info: 8 CSC03
 SG_ IC_Error : 13|1@0+ (1,0) [0|0] "" Vector__XXX
 SG_ IC_Warning : 12|1@0+ (1,0) [0|0] "" Vector__XXX
 SG_ Bal_State : 11|1@0+ (1,0) [0|0] "" Vector__XXX
 SG_ UnderTempError : 8|1@0+ (1,0) [0|0] "" Vector__XXX
 SG_ OverTempError : 7|1@0+ (1,0) [0|0] "" Vector__XXX
 SG_ UnderVoltageError : 10|1@0+ (1,0) [0|0] "" Vector__XXX
 SG_ OverVoltageError : 9|1@0+ (1,0) [0|0] "" Vector__XXX
 SG_ HW_Version : 39|16@0+ (1,0) [0|0] "" Vector__XXX
 SG_ Init_Error : 5|1@0+ (1,0) [0|0] "" Vector__XXX
 SG_ Measure_Error : 6|1@0+ (1,0) [0|0] "" Vector__XXX
 SG_ BalancerCountEmpty : 4|1@0+ (1,0) [0|0] "" Vector__XXX
 SG_ SW_Version : 55|16@0+ (1,0) [0|0] "" Vector__XXX
 SG_ CSC_Number : 3|4@0+ (1,0) [0|0] "" Vector__XXX

BO_ 2550398983 CSC04_Info: 8 CSC04
 SG_ IC_Error : 13|1@0+ (1,0) [0|0] "" Vector__XXX
 SG_ IC_Warning : 12|1@0+ (1,0) [0|0] "" Vector__XXX
 SG_ Bal_State : 11|1@0+ (1,0) [0|0] "" Vector__XXX
 SG_ UnderTempError : 8|1@0+ (1,0) [0|0] "" Vector__XXX
 SG_ OverTempError : 7|1@0+ (1,0) [0|0] "" Vector__XXX
 SG_ UnderVoltageError : 10|1@0+ (1,0) [0|0] "" Vector__XXX
 SG_ OverVoltageError : 9|1@0+ (1,0) [0|0] "" Vector__XXX
 SG_ HW_Version : 39|16@0+ (1,0) [0|0] "" Vector__XXX
 SG_ Init_Error : 5|1@0+ (1,0) [0|0] "" Vector__XXX
 SG_ Measure_Error : 6|1@0+ (1,0) [0|0] "" Vector__XXX
 SG_ BalancerCountEmpty : 4|1@0+ (1,0) [0|0] "" Vector__XXX
 SG_ SW_Version : 55|16@0+ (1,0) [0|0] "" Vector__XXX
 SG_ CSC_Number : 3|4@0+ (1,0) [0|0] "" Vector__XXX

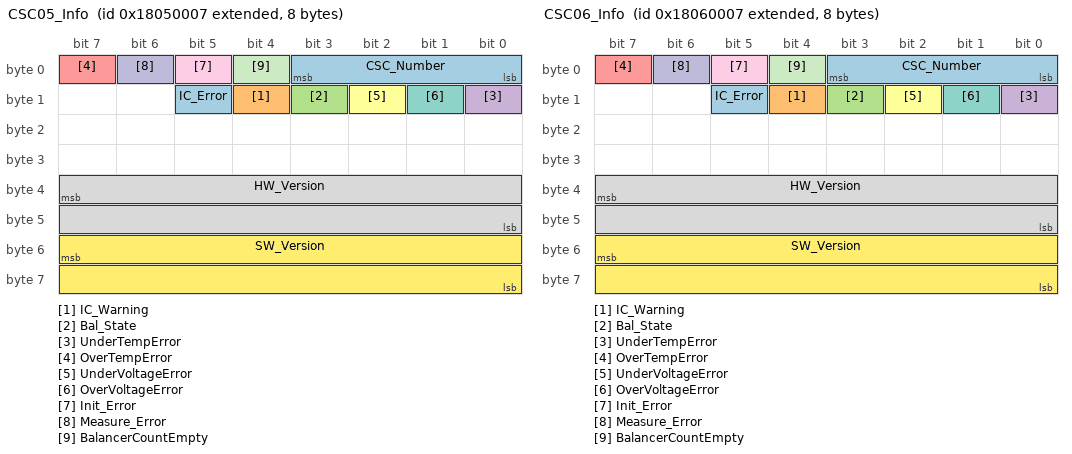
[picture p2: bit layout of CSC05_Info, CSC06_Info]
BO_ 2550464519 CSC05_Info: 8 CSC05
 SG_ IC_Error : 13|1@0+ (1,0) [0|0] "" Vector__XXX
 SG_ IC_Warning : 12|1@0+ (1,0) [0|0] "" Vector__XXX
 SG_ Bal_State : 11|1@0+ (1,0) [0|0] "" Vector__XXX
 SG_ UnderTempError : 8|1@0+ (1,0) [0|0] "" Vector__XXX
 SG_ OverTempError : 7|1@0+ (1,0) [0|0] "" Vector__XXX
 SG_ UnderVoltageError : 10|1@0+ (1,0) [0|0] "" Vector__XXX
 SG_ OverVoltageError : 9|1@0+ (1,0) [0|0] "" Vector__XXX
 SG_ HW_Version : 39|16@0+ (1,0) [0|0] "" Vector__XXX
 SG_ Init_Error : 5|1@0+ (1,0) [0|0] "" Vector__XXX
 SG_ Measure_Error : 6|1@0+ (1,0) [0|0] "" Vector__XXX
 SG_ BalancerCountEmpty : 4|1@0+ (1,0) [0|0] "" Vector__XXX
 SG_ SW_Version : 55|16@0+ (1,0) [0|0] "" Vector__XXX
 SG_ CSC_Number : 3|4@0+ (1,0) [0|0] "" Vector__XXX

BO_ 2550530055 CSC06_Info: 8 CSC06
 SG_ IC_Error : 13|1@0+ (1,0) [0|0] "" Vector__XXX
 SG_ IC_Warning : 12|1@0+ (1,0) [0|0] "" Vector__XXX
 SG_ Bal_State : 11|1@0+ (1,0) [0|0] "" Vector__XXX
 SG_ UnderTempError : 8|1@0+ (1,0) [0|0] "" Vector__XXX
 SG_ OverTempError : 7|1@0+ (1,0) [0|0] "" Vector__XXX
 SG_ UnderVoltageError : 10|1@0+ (1,0) [0|0] "" Vector__XXX
 SG_ OverVoltageError : 9|1@0+ (1,0) [0|0] "" Vector__XXX
 SG_ HW_Version : 39|16@0+ (1,0) [0|0] "" Vector__XXX
 SG_ Init_Error : 5|1@0+ (1,0) [0|0] "" Vector__XXX
 SG_ Measure_Error : 6|1@0+ (1,0) [0|0] "" Vector__XXX
 SG_ BalancerCountEmpty : 4|1@0+ (1,0) [0|0] "" Vector__XXX
 SG_ SW_Version : 55|16@0+ (1,0) [0|0] "" Vector__XXX
 SG_ CSC_Number : 3|4@0+ (1,0) [0|0] "" Vector__XXX

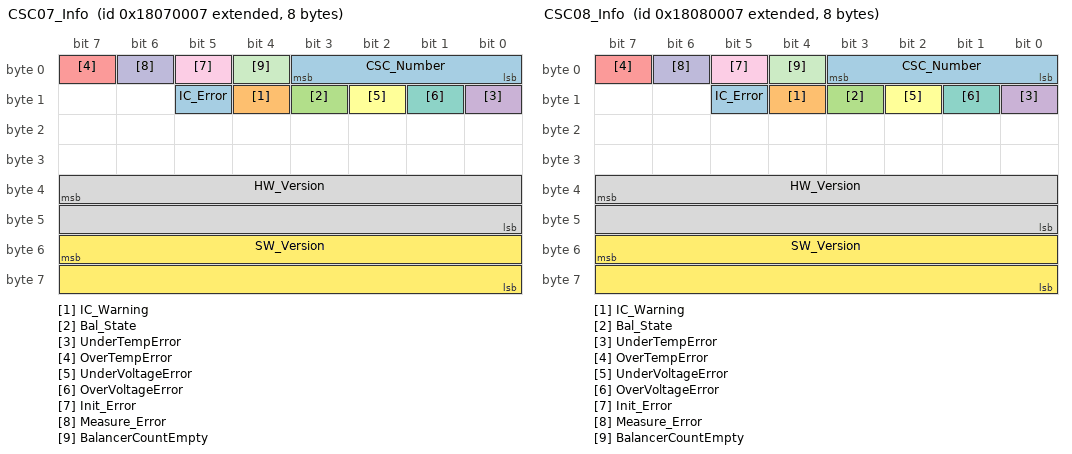
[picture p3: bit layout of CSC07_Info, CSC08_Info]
BO_ 2550595591 CSC07_Info: 8 CSC07
 SG_ IC_Error : 13|1@0+ (1,0) [0|0] "" Vector__XXX
 SG_ IC_Warning : 12|1@0+ (1,0) [0|0] "" Vector__XXX
 SG_ Bal_State : 11|1@0+ (1,0) [0|0] "" Vector__XXX
 SG_ UnderTempError : 8|1@0+ (1,0) [0|0] "" Vector__XXX
 SG_ OverTempError : 7|1@0+ (1,0) [0|0] "" Vector__XXX
 SG_ UnderVoltageError : 10|1@0+ (1,0) [0|0] "" Vector__XXX
 SG_ OverVoltageError : 9|1@0+ (1,0) [0|0] "" Vector__XXX
 SG_ HW_Version : 39|16@0+ (1,0) [0|0] "" Vector__XXX
 SG_ Init_Error : 5|1@0+ (1,0) [0|0] "" Vector__XXX
 SG_ Measure_Error : 6|1@0+ (1,0) [0|0] "" Vector__XXX
 SG_ BalancerCountEmpty : 4|1@0+ (1,0) [0|0] "" Vector__XXX
 SG_ SW_Version : 55|16@0+ (1,0) [0|0] "" Vector__XXX
 SG_ CSC_Number : 3|4@0+ (1,0) [0|0] "" Vector__XXX

BO_ 2550661127 CSC08_Info: 8 CSC08
 SG_ IC_Error : 13|1@0+ (1,0) [0|0] "" Vector__XXX
 SG_ IC_Warning : 12|1@0+ (1,0) [0|0] "" Vector__XXX
 SG_ Bal_State : 11|1@0+ (1,0) [0|0] "" Vector__XXX
 SG_ UnderTempError : 8|1@0+ (1,0) [0|0] "" Vector__XXX
 SG_ OverTempError : 7|1@0+ (1,0) [0|0] "" Vector__XXX
 SG_ UnderVoltageError : 10|1@0+ (1,0) [0|0] "" Vector__XXX
 SG_ OverVoltageError : 9|1@0+ (1,0) [0|0] "" Vector__XXX
 SG_ HW_Version : 39|16@0+ (1,0) [0|0] "" Vector__XXX
 SG_ Init_Error : 5|1@0+ (1,0) [0|0] "" Vector__XXX
 SG_ Measure_Error : 6|1@0+ (1,0) [0|0] "" Vector__XXX
 SG_ BalancerCountEmpty : 4|1@0+ (1,0) [0|0] "" Vector__XXX
 SG_ SW_Version : 55|16@0+ (1,0) [0|0] "" Vector__XXX
 SG_ CSC_Number : 3|4@0+ (1,0) [0|0] "" Vector__XXX

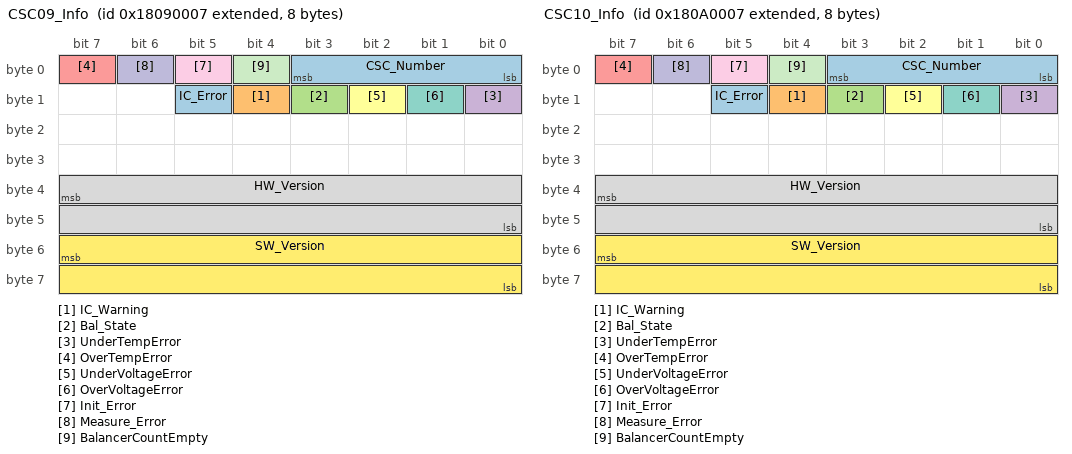
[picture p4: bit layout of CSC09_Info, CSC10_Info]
BO_ 2550726663 CSC09_Info: 8 CSC09
 SG_ IC_Error : 13|1@0+ (1,0) [0|0] "" Vector__XXX
 SG_ IC_Warning : 12|1@0+ (1,0) [0|0] "" Vector__XXX
 SG_ Bal_State : 11|1@0+ (1,0) [0|0] "" Vector__XXX
 SG_ UnderTempError : 8|1@0+ (1,0) [0|0] "" Vector__XXX
 SG_ OverTempError : 7|1@0+ (1,0) [0|0] "" Vector__XXX
 SG_ UnderVoltageError : 10|1@0+ (1,0) [0|0] "" Vector__XXX
 SG_ OverVoltageError : 9|1@0+ (1,0) [0|0] "" Vector__XXX
 SG_ HW_Version : 39|16@0+ (1,0) [0|0] "" Vector__XXX
 SG_ Init_Error : 5|1@0+ (1,0) [0|0] "" Vector__XXX
 SG_ Measure_Error : 6|1@0+ (1,0) [0|0] "" Vector__XXX
 SG_ BalancerCountEmpty : 4|1@0+ (1,0) [0|0] "" Vector__XXX
 SG_ SW_Version : 55|16@0+ (1,0) [0|0] "" Vector__XXX
 SG_ CSC_Number : 3|4@0+ (1,0) [0|0] "" Vector__XXX

BO_ 2550792199 CSC10_Info: 8 CSC10
 SG_ IC_Error : 13|1@0+ (1,0) [0|0] "" Vector__XXX
 SG_ IC_Warning : 12|1@0+ (1,0) [0|0] "" Vector__XXX
 SG_ Bal_State : 11|1@0+ (1,0) [0|0] "" Vector__XXX
 SG_ UnderTempError : 8|1@0+ (1,0) [0|0] "" Vector__XXX
 SG_ OverTempError : 7|1@0+ (1,0) [0|0] "" Vector__XXX
 SG_ UnderVoltageError : 10|1@0+ (1,0) [0|0] "" Vector__XXX
 SG_ OverVoltageError : 9|1@0+ (1,0) [0|0] "" Vector__XXX
 SG_ HW_Version : 39|16@0+ (1,0) [0|0] "" Vector__XXX
 SG_ Init_Error : 5|1@0+ (1,0) [0|0] "" Vector__XXX
 SG_ Measure_Error : 6|1@0+ (1,0) [0|0] "" Vector__XXX
 SG_ BalancerCountEmpty : 4|1@0+ (1,0) [0|0] "" Vector__XXX
 SG_ SW_Version : 55|16@0+ (1,0) [0|0] "" Vector__XXX
 SG_ CSC_Number : 3|4@0+ (1,0) [0|0] "" Vector__XXX

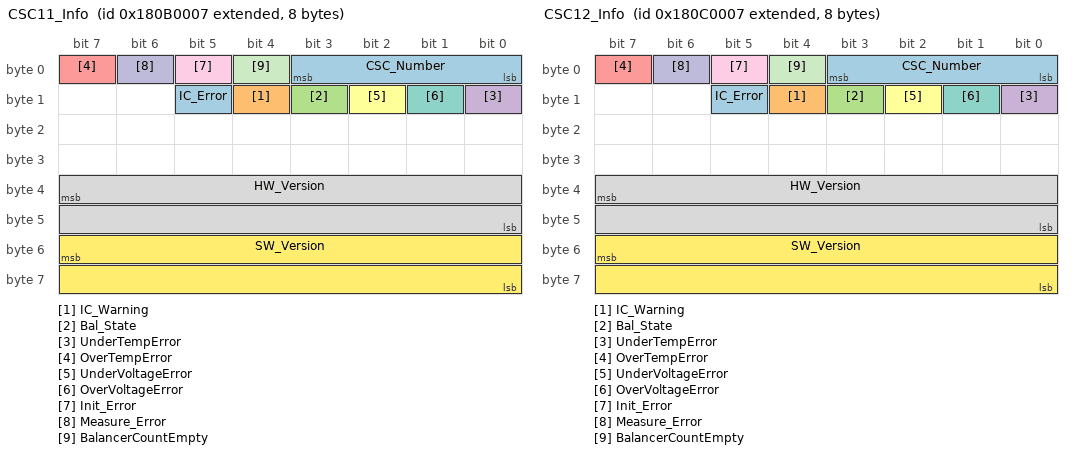
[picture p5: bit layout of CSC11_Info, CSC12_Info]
BO_ 2550857735 CSC11_Info: 8 CSC11
 SG_ IC_Error : 13|1@0+ (1,0) [0|0] "" Vector__XXX
 SG_ IC_Warning : 12|1@0+ (1,0) [0|0] "" Vector__XXX
 SG_ Bal_State : 11|1@0+ (1,0) [0|0] "" Vector__XXX
 SG_ UnderTempError : 8|1@0+ (1,0) [0|0] "" Vector__XXX
 SG_ OverTempError : 7|1@0+ (1,0) [0|0] "" Vector__XXX
 SG_ UnderVoltageError : 10|1@0+ (1,0) [0|0] "" Vector__XXX
 SG_ OverVoltageError : 9|1@0+ (1,0) [0|0] "" Vector__XXX
 SG_ HW_Version : 39|16@0+ (1,0) [0|0] "" Vector__XXX
 SG_ Init_Error : 5|1@0+ (1,0) [0|0] "" Vector__XXX
 SG_ Measure_Error : 6|1@0+ (1,0) [0|0] "" Vector__XXX
 SG_ BalancerCountEmpty : 4|1@0+ (1,0) [0|0] "" Vector__XXX
 SG_ SW_Version : 55|16@0+ (1,0) [0|0] "" Vector__XXX
 SG_ CSC_Number : 3|4@0+ (1,0) [0|0] "" Vector__XXX

BO_ 2550923271 CSC12_Info: 8 CSC12
 SG_ IC_Error : 13|1@0+ (1,0) [0|0] "" Vector__XXX
 SG_ IC_Warning : 12|1@0+ (1,0) [0|0] "" Vector__XXX
 SG_ Bal_State : 11|1@0+ (1,0) [0|0] "" Vector__XXX
 SG_ UnderTempError : 8|1@0+ (1,0) [0|0] "" Vector__XXX
 SG_ OverTempError : 7|1@0+ (1,0) [0|0] "" Vector__XXX
 SG_ UnderVoltageError : 10|1@0+ (1,0) [0|0] "" Vector__XXX
 SG_ OverVoltageError : 9|1@0+ (1,0) [0|0] "" Vector__XXX
 SG_ HW_Version : 39|16@0+ (1,0) [0|0] "" Vector__XXX
 SG_ Init_Error : 5|1@0+ (1,0) [0|0] "" Vector__XXX
 SG_ Measure_Error : 6|1@0+ (1,0) [0|0] "" Vector__XXX
 SG_ BalancerCountEmpty : 4|1@0+ (1,0) [0|0] "" Vector__XXX
 SG_ SW_Version : 55|16@0+ (1,0) [0|0] "" Vector__XXX
 SG_ CSC_Number : 3|4@0+ (1,0) [0|0] "" Vector__XXX

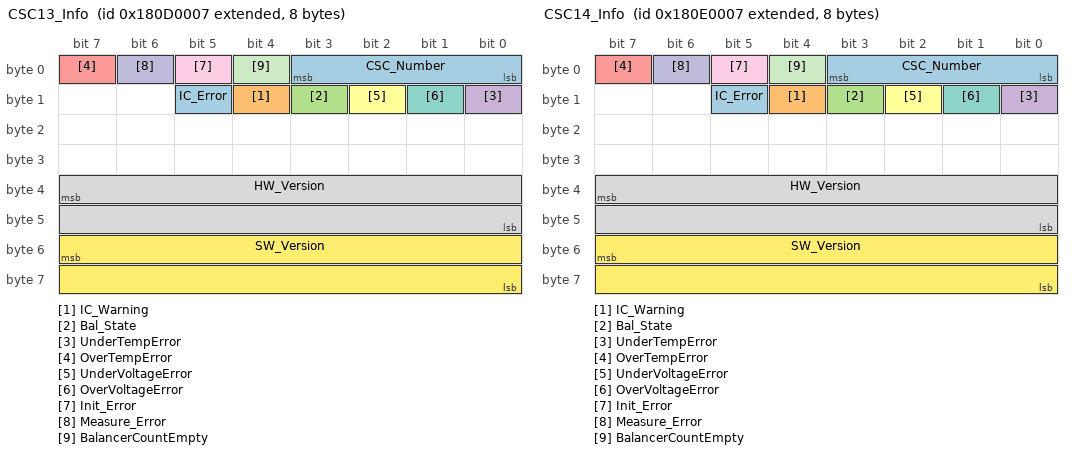
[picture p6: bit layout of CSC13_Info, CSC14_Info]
BO_ 2550988807 CSC13_Info: 8 CSC13
 SG_ IC_Error : 13|1@0+ (1,0) [0|0] "" Vector__XXX
 SG_ IC_Warning : 12|1@0+ (1,0) [0|0] "" Vector__XXX
 SG_ Bal_State : 11|1@0+ (1,0) [0|0] "" Vector__XXX
 SG_ UnderTempError : 8|1@0+ (1,0) [0|0] "" Vector__XXX
 SG_ OverTempError : 7|1@0+ (1,0) [0|0] "" Vector__XXX
 SG_ UnderVoltageError : 10|1@0+ (1,0) [0|0] "" Vector__XXX
 SG_ OverVoltageError : 9|1@0+ (1,0) [0|0] "" Vector__XXX
 SG_ HW_Version : 39|16@0+ (1,0) [0|0] "" Vector__XXX
 SG_ Init_Error : 5|1@0+ (1,0) [0|0] "" Vector__XXX
 SG_ Measure_Error : 6|1@0+ (1,0) [0|0] "" Vector__XXX
 SG_ BalancerCountEmpty : 4|1@0+ (1,0) [0|0] "" Vector__XXX
 SG_ SW_Version : 55|16@0+ (1,0) [0|0] "" Vector__XXX
 SG_ CSC_Number : 3|4@0+ (1,0) [0|0] "" Vector__XXX

BO_ 2551054343 CSC14_Info: 8 CSC14
 SG_ IC_Error : 13|1@0+ (1,0) [0|0] "" Vector__XXX
 SG_ IC_Warning : 12|1@0+ (1,0) [0|0] "" Vector__XXX
 SG_ Bal_State : 11|1@0+ (1,0) [0|0] "" Vector__XXX
 SG_ UnderTempError : 8|1@0+ (1,0) [0|0] "" Vector__XXX
 SG_ OverTempError : 7|1@0+ (1,0) [0|0] "" Vector__XXX
 SG_ UnderVoltageError : 10|1@0+ (1,0) [0|0] "" Vector__XXX
 SG_ OverVoltageError : 9|1@0+ (1,0) [0|0] "" Vector__XXX
 SG_ HW_Version : 39|16@0+ (1,0) [0|0] "" Vector__XXX
 SG_ Init_Error : 5|1@0+ (1,0) [0|0] "" Vector__XXX
 SG_ Measure_Error : 6|1@0+ (1,0) [0|0] "" Vector__XXX
 SG_ BalancerCountEmpty : 4|1@0+ (1,0) [0|0] "" Vector__XXX
 SG_ SW_Version : 55|16@0+ (1,0) [0|0] "" Vector__XXX
 SG_ CSC_Number : 3|4@0+ (1,0) [0|0] "" Vector__XXX

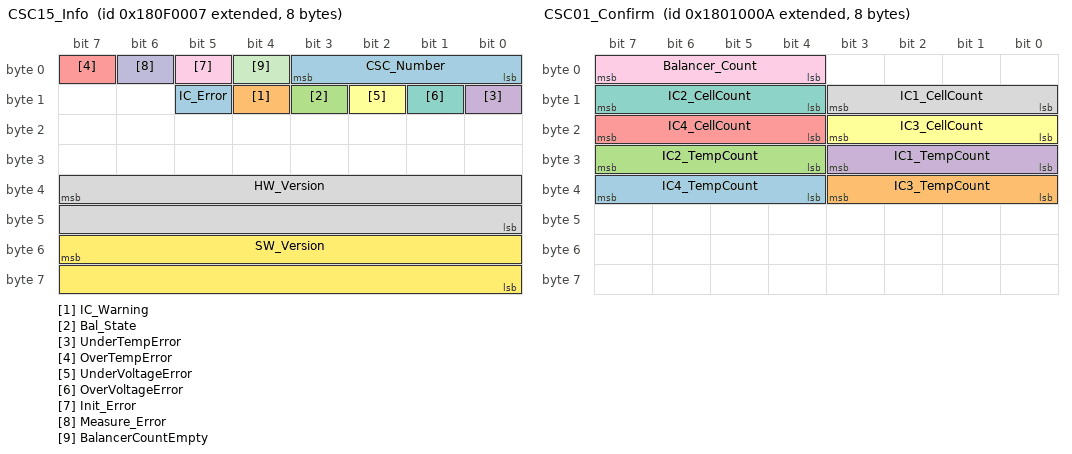
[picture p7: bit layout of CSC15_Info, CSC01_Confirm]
BO_ 2551119879 CSC15_Info: 8 CSC15
 SG_ IC_Error : 13|1@0+ (1,0) [0|0] "" Vector__XXX
 SG_ IC_Warning : 12|1@0+ (1,0) [0|0] "" Vector__XXX
 SG_ Bal_State : 11|1@0+ (1,0) [0|0] "" Vector__XXX
 SG_ UnderTempError : 8|1@0+ (1,0) [0|0] "" Vector__XXX
 SG_ OverTempError : 7|1@0+ (1,0) [0|0] "" Vector__XXX
 SG_ UnderVoltageError : 10|1@0+ (1,0) [0|0] "" Vector__XXX
 SG_ OverVoltageError : 9|1@0+ (1,0) [0|0] "" Vector__XXX
 SG_ HW_Version : 39|16@0+ (1,0) [0|0] "" Vector__XXX
 SG_ Init_Error : 5|1@0+ (1,0) [0|0] "" Vector__XXX
 SG_ Measure_Error : 6|1@0+ (1,0) [0|0] "" Vector__XXX
 SG_ BalancerCountEmpty : 4|1@0+ (1,0) [0|0] "" Vector__XXX
 SG_ SW_Version : 55|16@0+ (1,0) [0|0] "" Vector__XXX
 SG_ CSC_Number : 3|4@0+ (1,0) [0|0] "" Vector__XXX

BO_ 2550202378 CSC01_Confirm: 8 CSC01
 SG_ IC4_TempCount : 39|4@0+ (1,0) [0|6] "" Vector__XXX
 SG_ IC3_TempCount : 35|4@0+ (1,0) [0|6] "" Vector__XXX
 SG_ IC2_TempCount : 31|4@0+ (1,0) [0|6] "" Vector__XXX
 SG_ IC1_TempCount : 27|4@0+ (1,0) [0|6] "" Vector__XXX
 SG_ IC4_CellCount : 23|4@0+ (1,0) [7|14] "" Vector__XXX
 SG_ IC3_CellCount : 19|4@0+ (1,0) [7|14] "" Vector__XXX
 SG_ IC2_CellCount : 15|4@0+ (1,0) [7|14] "" Vector__XXX
 SG_ IC1_CellCount : 11|4@0+ (1,0) [7|14] "" Vector__XXX
 SG_ Balancer_Count : 7|4@0+ (1,0) [0|4] "" Vector__XXX

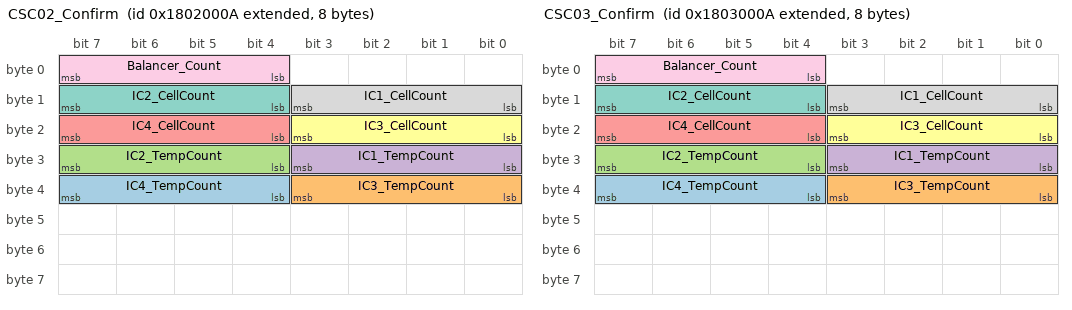
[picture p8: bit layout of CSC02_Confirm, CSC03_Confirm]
BO_ 2550267914 CSC02_Confirm: 8 CSC02
 SG_ IC4_TempCount : 39|4@0+ (1,0) [0|6] "" Vector__XXX
 SG_ IC3_TempCount : 35|4@0+ (1,0) [0|6] "" Vector__XXX
 SG_ IC2_TempCount : 31|4@0+ (1,0) [0|6] "" Vector__XXX
 SG_ IC1_TempCount : 27|4@0+ (1,0) [0|6] "" Vector__XXX
 SG_ IC4_CellCount : 23|4@0+ (1,0) [7|14] "" Vector__XXX
 SG_ IC3_CellCount : 19|4@0+ (1,0) [7|14] "" Vector__XXX
 SG_ IC2_CellCount : 15|4@0+ (1,0) [7|14] "" Vector__XXX
 SG_ IC1_CellCount : 11|4@0+ (1,0) [7|14] "" Vector__XXX
 SG_ Balancer_Count : 7|4@0+ (1,0) [0|4] "" Vector__XXX

BO_ 2550333450 CSC03_Confirm: 8 CSC03
 SG_ IC4_TempCount : 39|4@0+ (1,0) [0|6] "" Vector__XXX
 SG_ IC3_TempCount : 35|4@0+ (1,0) [0|6] "" Vector__XXX
 SG_ IC2_TempCount : 31|4@0+ (1,0) [0|6] "" Vector__XXX
 SG_ IC1_TempCount : 27|4@0+ (1,0) [0|6] "" Vector__XXX
 SG_ IC4_CellCount : 23|4@0+ (1,0) [7|14] "" Vector__XXX
 SG_ IC3_CellCount : 19|4@0+ (1,0) [7|14] "" Vector__XXX
 SG_ IC2_CellCount : 15|4@0+ (1,0) [7|14] "" Vector__XXX
 SG_ IC1_CellCount : 11|4@0+ (1,0) [7|14] "" Vector__XXX
 SG_ Balancer_Count : 7|4@0+ (1,0) [0|4] "" Vector__XXX

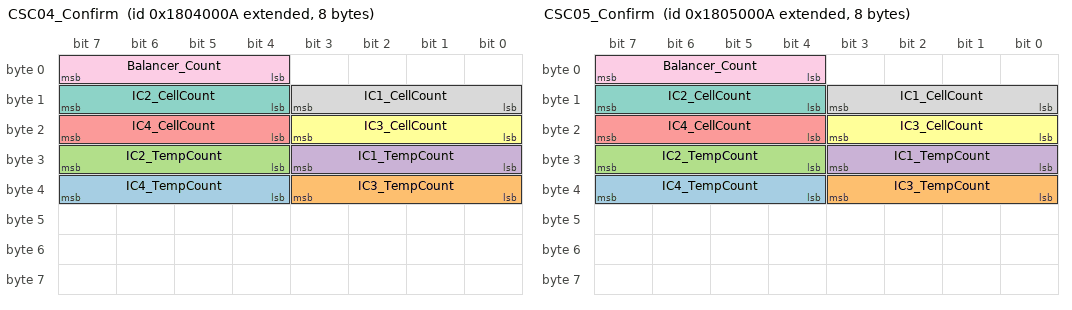
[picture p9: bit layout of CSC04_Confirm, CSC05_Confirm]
BO_ 2550398986 CSC04_Confirm: 8 CSC04
 SG_ IC4_TempCount : 39|4@0+ (1,0) [0|6] "" Vector__XXX
 SG_ IC3_TempCount : 35|4@0+ (1,0) [0|6] "" Vector__XXX
 SG_ IC2_TempCount : 31|4@0+ (1,0) [0|6] "" Vector__XXX
 SG_ IC1_TempCount : 27|4@0+ (1,0) [0|6] "" Vector__XXX
 SG_ IC4_CellCount : 23|4@0+ (1,0) [7|14] "" Vector__XXX
 SG_ IC3_CellCount : 19|4@0+ (1,0) [7|14] "" Vector__XXX
 SG_ IC2_CellCount : 15|4@0+ (1,0) [7|14] "" Vector__XXX
 SG_ IC1_CellCount : 11|4@0+ (1,0) [7|14] "" Vector__XXX
 SG_ Balancer_Count : 7|4@0+ (1,0) [0|4] "" Vector__XXX

BO_ 2550464522 CSC05_Confirm: 8 CSC05
 SG_ IC4_TempCount : 39|4@0+ (1,0) [0|6] "" Vector__XXX
 SG_ IC3_TempCount : 35|4@0+ (1,0) [0|6] "" Vector__XXX
 SG_ IC2_TempCount : 31|4@0+ (1,0) [0|6] "" Vector__XXX
 SG_ IC1_TempCount : 27|4@0+ (1,0) [0|6] "" Vector__XXX
 SG_ IC4_CellCount : 23|4@0+ (1,0) [7|14] "" Vector__XXX
 SG_ IC3_CellCount : 19|4@0+ (1,0) [7|14] "" Vector__XXX
 SG_ IC2_CellCount : 15|4@0+ (1,0) [7|14] "" Vector__XXX
 SG_ IC1_CellCount : 11|4@0+ (1,0) [7|14] "" Vector__XXX
 SG_ Balancer_Count : 7|4@0+ (1,0) [0|4] "" Vector__XXX

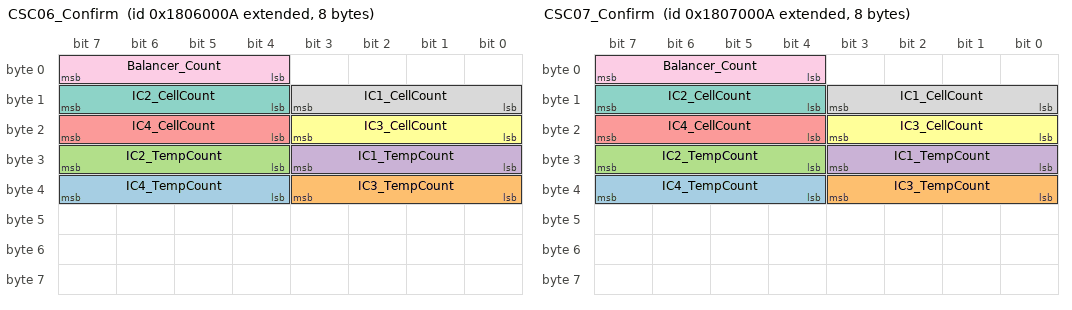
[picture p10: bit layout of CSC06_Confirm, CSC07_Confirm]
BO_ 2550530058 CSC06_Confirm: 8 CSC06
 SG_ IC4_TempCount : 39|4@0+ (1,0) [0|6] "" Vector__XXX
 SG_ IC3_TempCount : 35|4@0+ (1,0) [0|6] "" Vector__XXX
 SG_ IC2_TempCount : 31|4@0+ (1,0) [0|6] "" Vector__XXX
 SG_ IC1_TempCount : 27|4@0+ (1,0) [0|6] "" Vector__XXX
 SG_ IC4_CellCount : 23|4@0+ (1,0) [7|14] "" Vector__XXX
 SG_ IC3_CellCount : 19|4@0+ (1,0) [7|14] "" Vector__XXX
 SG_ IC2_CellCount : 15|4@0+ (1,0) [7|14] "" Vector__XXX
 SG_ IC1_CellCount : 11|4@0+ (1,0) [7|14] "" Vector__XXX
 SG_ Balancer_Count : 7|4@0+ (1,0) [0|4] "" Vector__XXX

BO_ 2550595594 CSC07_Confirm: 8 CSC07
 SG_ IC4_TempCount : 39|4@0+ (1,0) [0|6] "" Vector__XXX
 SG_ IC3_TempCount : 35|4@0+ (1,0) [0|6] "" Vector__XXX
 SG_ IC2_TempCount : 31|4@0+ (1,0) [0|6] "" Vector__XXX
 SG_ IC1_TempCount : 27|4@0+ (1,0) [0|6] "" Vector__XXX
 SG_ IC4_CellCount : 23|4@0+ (1,0) [7|14] "" Vector__XXX
 SG_ IC3_CellCount : 19|4@0+ (1,0) [7|14] "" Vector__XXX
 SG_ IC2_CellCount : 15|4@0+ (1,0) [7|14] "" Vector__XXX
 SG_ IC1_CellCount : 11|4@0+ (1,0) [7|14] "" Vector__XXX
 SG_ Balancer_Count : 7|4@0+ (1,0) [0|4] "" Vector__XXX

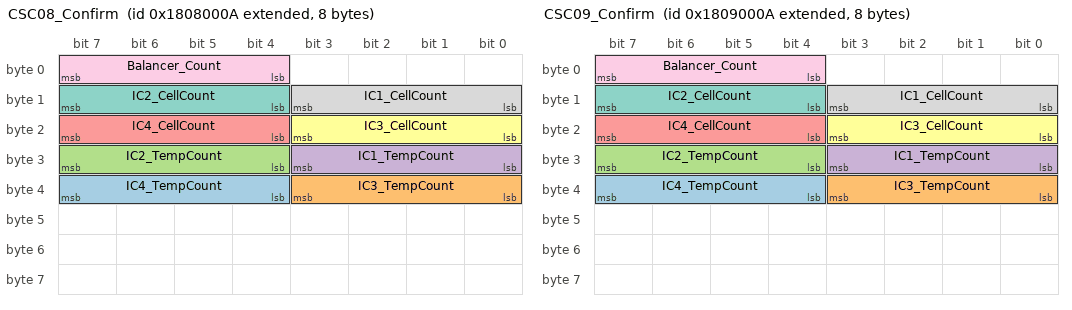
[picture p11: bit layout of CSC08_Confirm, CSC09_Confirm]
BO_ 2550661130 CSC08_Confirm: 8 CSC08
 SG_ IC4_TempCount : 39|4@0+ (1,0) [0|6] "" Vector__XXX
 SG_ IC3_TempCount : 35|4@0+ (1,0) [0|6] "" Vector__XXX
 SG_ IC2_TempCount : 31|4@0+ (1,0) [0|6] "" Vector__XXX
 SG_ IC1_TempCount : 27|4@0+ (1,0) [0|6] "" Vector__XXX
 SG_ IC4_CellCount : 23|4@0+ (1,0) [7|14] "" Vector__XXX
 SG_ IC3_CellCount : 19|4@0+ (1,0) [7|14] "" Vector__XXX
 SG_ IC2_CellCount : 15|4@0+ (1,0) [7|14] "" Vector__XXX
 SG_ IC1_CellCount : 11|4@0+ (1,0) [7|14] "" Vector__XXX
 SG_ Balancer_Count : 7|4@0+ (1,0) [0|4] "" Vector__XXX

BO_ 2550726666 CSC09_Confirm: 8 CSC09
 SG_ IC4_TempCount : 39|4@0+ (1,0) [0|6] "" Vector__XXX
 SG_ IC3_TempCount : 35|4@0+ (1,0) [0|6] "" Vector__XXX
 SG_ IC2_TempCount : 31|4@0+ (1,0) [0|6] "" Vector__XXX
 SG_ IC1_TempCount : 27|4@0+ (1,0) [0|6] "" Vector__XXX
 SG_ IC4_CellCount : 23|4@0+ (1,0) [7|14] "" Vector__XXX
 SG_ IC3_CellCount : 19|4@0+ (1,0) [7|14] "" Vector__XXX
 SG_ IC2_CellCount : 15|4@0+ (1,0) [7|14] "" Vector__XXX
 SG_ IC1_CellCount : 11|4@0+ (1,0) [7|14] "" Vector__XXX
 SG_ Balancer_Count : 7|4@0+ (1,0) [0|4] "" Vector__XXX

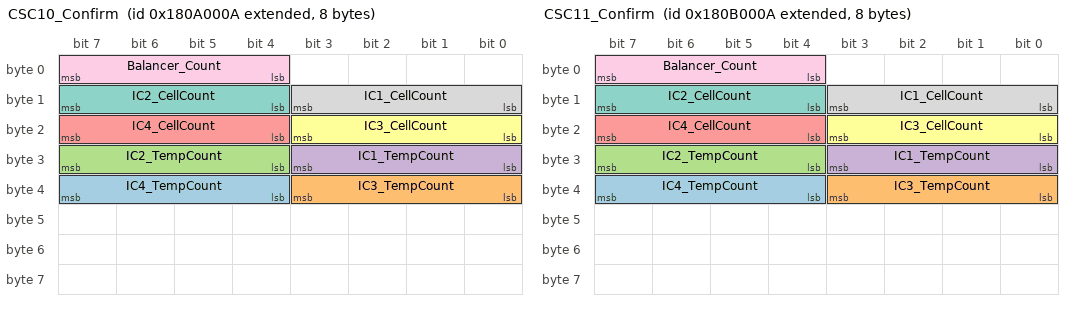
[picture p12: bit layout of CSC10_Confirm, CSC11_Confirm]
BO_ 2550792202 CSC10_Confirm: 8 CSC10
 SG_ IC4_TempCount : 39|4@0+ (1,0) [0|6] "" Vector__XXX
 SG_ IC3_TempCount : 35|4@0+ (1,0) [0|6] "" Vector__XXX
 SG_ IC2_TempCount : 31|4@0+ (1,0) [0|6] "" Vector__XXX
 SG_ IC1_TempCount : 27|4@0+ (1,0) [0|6] "" Vector__XXX
 SG_ IC4_CellCount : 23|4@0+ (1,0) [7|14] "" Vector__XXX
 SG_ IC3_CellCount : 19|4@0+ (1,0) [7|14] "" Vector__XXX
 SG_ IC2_CellCount : 15|4@0+ (1,0) [7|14] "" Vector__XXX
 SG_ IC1_CellCount : 11|4@0+ (1,0) [7|14] "" Vector__XXX
 SG_ Balancer_Count : 7|4@0+ (1,0) [0|4] "" Vector__XXX

BO_ 2550857738 CSC11_Confirm: 8 CSC11
 SG_ IC4_TempCount : 39|4@0+ (1,0) [0|6] "" Vector__XXX
 SG_ IC3_TempCount : 35|4@0+ (1,0) [0|6] "" Vector__XXX
 SG_ IC2_TempCount : 31|4@0+ (1,0) [0|6] "" Vector__XXX
 SG_ IC1_TempCount : 27|4@0+ (1,0) [0|6] "" Vector__XXX
 SG_ IC4_CellCount : 23|4@0+ (1,0) [7|14] "" Vector__XXX
 SG_ IC3_CellCount : 19|4@0+ (1,0) [7|14] "" Vector__XXX
 SG_ IC2_CellCount : 15|4@0+ (1,0) [7|14] "" Vector__XXX
 SG_ IC1_CellCount : 11|4@0+ (1,0) [7|14] "" Vector__XXX
 SG_ Balancer_Count : 7|4@0+ (1,0) [0|4] "" Vector__XXX

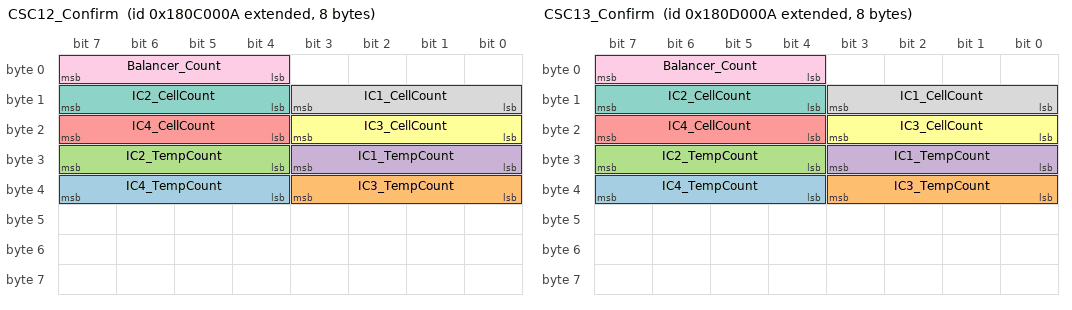
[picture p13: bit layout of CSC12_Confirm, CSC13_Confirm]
BO_ 2550923274 CSC12_Confirm: 8 CSC12
 SG_ IC4_TempCount : 39|4@0+ (1,0) [0|6] "" Vector__XXX
 SG_ IC3_TempCount : 35|4@0+ (1,0) [0|6] "" Vector__XXX
 SG_ IC2_TempCount : 31|4@0+ (1,0) [0|6] "" Vector__XXX
 SG_ IC1_TempCount : 27|4@0+ (1,0) [0|6] "" Vector__XXX
 SG_ IC4_CellCount : 23|4@0+ (1,0) [7|14] "" Vector__XXX
 SG_ IC3_CellCount : 19|4@0+ (1,0) [7|14] "" Vector__XXX
 SG_ IC2_CellCount : 15|4@0+ (1,0) [7|14] "" Vector__XXX
 SG_ IC1_CellCount : 11|4@0+ (1,0) [7|14] "" Vector__XXX
 SG_ Balancer_Count : 7|4@0+ (1,0) [0|4] "" Vector__XXX

BO_ 2550988810 CSC13_Confirm: 8 CSC13
 SG_ IC4_TempCount : 39|4@0+ (1,0) [0|6] "" Vector__XXX
 SG_ IC3_TempCount : 35|4@0+ (1,0) [0|6] "" Vector__XXX
 SG_ IC2_TempCount : 31|4@0+ (1,0) [0|6] "" Vector__XXX
 SG_ IC1_TempCount : 27|4@0+ (1,0) [0|6] "" Vector__XXX
 SG_ IC4_CellCount : 23|4@0+ (1,0) [7|14] "" Vector__XXX
 SG_ IC3_CellCount : 19|4@0+ (1,0) [7|14] "" Vector__XXX
 SG_ IC2_CellCount : 15|4@0+ (1,0) [7|14] "" Vector__XXX
 SG_ IC1_CellCount : 11|4@0+ (1,0) [7|14] "" Vector__XXX
 SG_ Balancer_Count : 7|4@0+ (1,0) [0|4] "" Vector__XXX

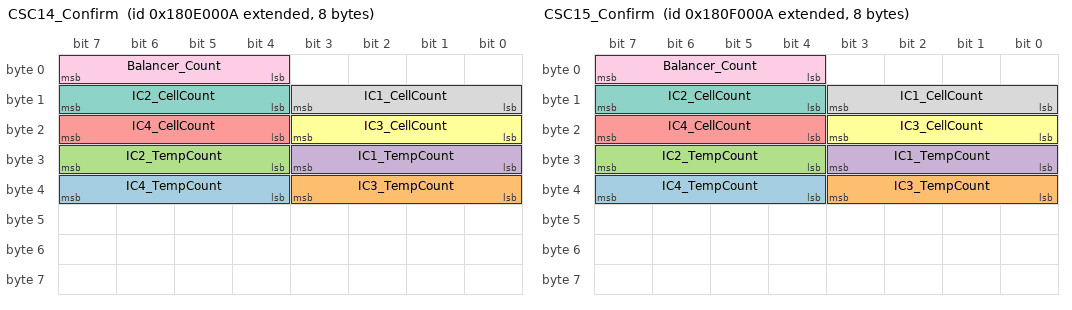
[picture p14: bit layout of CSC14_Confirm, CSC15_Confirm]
BO_ 2551054346 CSC14_Confirm: 8 CSC14
 SG_ IC4_TempCount : 39|4@0+ (1,0) [0|6] "" Vector__XXX
 SG_ IC3_TempCount : 35|4@0+ (1,0) [0|6] "" Vector__XXX
 SG_ IC2_TempCount : 31|4@0+ (1,0) [0|6] "" Vector__XXX
 SG_ IC1_TempCount : 27|4@0+ (1,0) [0|6] "" Vector__XXX
 SG_ IC4_CellCount : 23|4@0+ (1,0) [7|14] "" Vector__XXX
 SG_ IC3_CellCount : 19|4@0+ (1,0) [7|14] "" Vector__XXX
 SG_ IC2_CellCount : 15|4@0+ (1,0) [7|14] "" Vector__XXX
 SG_ IC1_CellCount : 11|4@0+ (1,0) [7|14] "" Vector__XXX
 SG_ Balancer_Count : 7|4@0+ (1,0) [0|4] "" Vector__XXX

BO_ 2551119882 CSC15_Confirm: 8 CSC15
 SG_ IC4_TempCount : 39|4@0+ (1,0) [0|6] "" Vector__XXX
 SG_ IC3_TempCount : 35|4@0+ (1,0) [0|6] "" Vector__XXX
 SG_ IC2_TempCount : 31|4@0+ (1,0) [0|6] "" Vector__XXX
 SG_ IC1_TempCount : 27|4@0+ (1,0) [0|6] "" Vector__XXX
 SG_ IC4_CellCount : 23|4@0+ (1,0) [7|14] "" Vector__XXX
 SG_ IC3_CellCount : 19|4@0+ (1,0) [7|14] "" Vector__XXX
 SG_ IC2_CellCount : 15|4@0+ (1,0) [7|14] "" Vector__XXX
 SG_ IC1_CellCount : 11|4@0+ (1,0) [7|14] "" Vector__XXX
 SG_ Balancer_Count : 7|4@0+ (1,0) [0|4] "" Vector__XXX

BO_ 2550202379 CSC01_Confirm2: 8 CSC01
 SG_ OverVoltageLimit : 7|16@0+ (1,0) [0|65535] "" Vector__XXX
 SG_ UnderVoltageLimit : 23|16@0+ (1,0) [0|65535] "" Vector__XXX
 SG_ OverTempLimit : 39|8@0+ (1,-40) [-40|215] "" Vector__XXX
 SG_ UnderTempLimit : 47|8@0+ (1,-40) [-40|215] "" Vector__XXX

BO_ 2550267915 CSC02_Confirm2: 8 CSC02
 SG_ OverVoltageLimit : 7|16@0+ (1,0) [0|65535] "" Vector__XXX
 SG_ UnderVoltageLimit : 23|16@0+ (1,0) [0|65535] "" Vector__XXX
 SG_ OverTempLimit : 39|8@0+ (1,-40) [-40|215] "" Vector__XXX
 SG_ UnderTempLimit : 47|8@0+ (1,-40) [-40|215] "" Vector__XXX

BO_ 2550333451 CSC03_Confirm2: 8 CSC03
 SG_ OverVoltageLimit : 7|16@0+ (1,0) [0|65535] "" Vector__XXX
 SG_ UnderVoltageLimit : 23|16@0+ (1,0) [0|65535] "" Vector__XXX
 SG_ OverTempLimit : 39|8@0+ (1,-40) [-40|215] "" Vector__XXX
 SG_ UnderTempLimit : 47|8@0+ (1,-40) [-40|215] "" Vector__XXX

BO_ 2550398987 CSC04_Confirm2: 8 CSC04
 SG_ OverVoltageLimit : 7|16@0+ (1,0) [0|65535] "" Vector__XXX
 SG_ UnderVoltageLimit : 23|16@0+ (1,0) [0|65535] "" Vector__XXX
 SG_ OverTempLimit : 39|8@0+ (1,-40) [-40|215] "" Vector__XXX
 SG_ UnderTempLimit : 47|8@0+ (1,-40) [-40|215] "" Vector__XXX

BO_ 2550464523 CSC05_Confirm2: 8 CSC05
 SG_ OverVoltageLimit : 7|16@0+ (1,0) [0|65535] "" Vector__XXX
 SG_ UnderVoltageLimit : 23|16@0+ (1,0) [0|65535] "" Vector__XXX
 SG_ OverTempLimit : 39|8@0+ (1,-40) [-40|215] "" Vector__XXX
 SG_ UnderTempLimit : 47|8@0+ (1,-40) [-40|215] "" Vector__XXX

BO_ 2550530059 CSC06_Confirm2: 8 CSC06
 SG_ OverVoltageLimit : 7|16@0+ (1,0) [0|65535] "" Vector__XXX
 SG_ UnderVoltageLimit : 23|16@0+ (1,0) [0|65535] "" Vector__XXX
 SG_ OverTempLimit : 39|8@0+ (1,-40) [-40|215] "" Vector__XXX
 SG_ UnderTempLimit : 47|8@0+ (1,-40) [-40|215] "" Vector__XXX

BO_ 2550595595 CSC07_Confirm2: 8 CSC07
 SG_ OverVoltageLimit : 7|16@0+ (1,0) [0|65535] "" Vector__XXX
 SG_ UnderVoltageLimit : 23|16@0+ (1,0) [0|65535] "" Vector__XXX
 SG_ OverTempLimit : 39|8@0+ (1,-40) [-40|215] "" Vector__XXX
 SG_ UnderTempLimit : 47|8@0+ (1,-40) [-40|215] "" Vector__XXX

BO_ 2550661131 CSC08_Confirm2: 8 CSC08
 SG_ OverVoltageLimit : 7|16@0+ (1,0) [0|65535] "" Vector__XXX
 SG_ UnderVoltageLimit : 23|16@0+ (1,0) [0|65535] "" Vector__XXX
 SG_ OverTempLimit : 39|8@0+ (1,-40) [-40|215] "" Vector__XXX
 SG_ UnderTempLimit : 47|8@0+ (1,-40) [-40|215] "" Vector__XXX

BO_ 2550726667 CSC09_Confirm2: 8 CSC09
 SG_ OverVoltageLimit : 7|16@0+ (1,0) [0|65535] "" Vector__XXX
 SG_ UnderVoltageLimit : 23|16@0+ (1,0) [0|65535] "" Vector__XXX
 SG_ OverTempLimit : 39|8@0+ (1,-40) [-40|215] "" Vector__XXX
 SG_ UnderTempLimit : 47|8@0+ (1,-40) [-40|215] "" Vector__XXX

BO_ 2550792203 CSC10_Confirm2: 8 CSC10
 SG_ OverVoltageLimit : 7|16@0+ (1,0) [0|65535] "" Vector__XXX
 SG_ UnderVoltageLimit : 23|16@0+ (1,0) [0|65535] "" Vector__XXX
 SG_ OverTempLimit : 39|8@0+ (1,-40) [-40|215] "" Vector__XXX
 SG_ UnderTempLimit : 47|8@0+ (1,-40) [-40|215] "" Vector__XXX

BO_ 2550857739 CSC11_Confirm2: 8 CSC11
 SG_ OverVoltageLimit : 7|16@0+ (1,0) [0|65535] "" Vector__XXX
 SG_ UnderVoltageLimit : 23|16@0+ (1,0) [0|65535] "" Vector__XXX
 SG_ OverTempLimit : 39|8@0+ (1,-40) [-40|215] "" Vector__XXX
 SG_ UnderTempLimit : 47|8@0+ (1,-40) [-40|215] "" Vector__XXX

BO_ 2550923275 CSC12_Confirm2: 8 CSC12
 SG_ OverVoltageLimit : 7|16@0+ (1,0) [0|65535] "" Vector__XXX
 SG_ UnderVoltageLimit : 23|16@0+ (1,0) [0|65535] "" Vector__XXX
 SG_ OverTempLimit : 39|8@0+ (1,-40) [-40|215] "" Vector__XXX
 SG_ UnderTempLimit : 47|8@0+ (1,-40) [-40|215] "" Vector__XXX

BO_ 2550988811 CSC13_Confirm2: 8 CSC13
 SG_ OverVoltageLimit : 7|16@0+ (1,0) [0|65535] "" Vector__XXX
 SG_ UnderVoltageLimit : 23|16@0+ (1,0) [0|65535] "" Vector__XXX
 SG_ OverTempLimit : 39|8@0+ (1,-40) [-40|215] "" Vector__XXX
 SG_ UnderTempLimit : 47|8@0+ (1,-40) [-40|215] "" Vector__XXX

BO_ 2551054347 CSC14_Confirm2: 8 CSC14
 SG_ OverVoltageLimit : 7|16@0+ (1,0) [0|65535] "" Vector__XXX
 SG_ UnderVoltageLimit : 23|16@0+ (1,0) [0|65535] "" Vector__XXX
 SG_ OverTempLimit : 39|8@0+ (1,-40) [-40|215] "" Vector__XXX
 SG_ UnderTempLimit : 47|8@0+ (1,-40) [-40|215] "" Vector__XXX

BO_ 2551119883 CSC15_Confirm2: 8 CSC15
 SG_ OverVoltageLimit : 7|16@0+ (1,0) [0|65535] "" Vector__XXX
 SG_ UnderVoltageLimit : 23|16@0+ (1,0) [0|65535] "" Vector__XXX
 SG_ OverTempLimit : 39|8@0+ (1,-40) [-40|215] "" Vector__XXX
 SG_ UnderTempLimit : 47|8@0+ (1,-40) [-40|215] "" Vector__XXX

BO_ 2533359626 CSC_Reset: 8 Vector__XXX
 SG_ CSC_ResetCode3 : 39|8@0+ (1,0) [0|0] "" Vector__XXX
 SG_ CSC_ResetCode2 : 31|8@0+ (1,0) [0|0] "" Vector__XXX
 SG_ CSC_ResetCode1 : 23|8@0+ (1,0) [0|0] "" Vector__XXX
 SG_ CSC1_Reset : 0|1@0+ (1,0) [0|0] "" Vector__XXX
 SG_ CSC2_Reset : 1|1@0+ (1,0) [0|0] "" Vector__XXX
 SG_ CSC3_Reset : 2|1@0+ (1,0) [0|0] "" Vector__XXX
 SG_ CSC4_Reset : 3|1@0+ (1,0) [0|0] "" Vector__XXX
 SG_ CSC5_Reset : 4|1@0+ (1,0) [0|0] "" Vector__XXX
 SG_ CSC6_Reset : 5|1@0+ (1,0) [0|0] "" Vector__XXX
 SG_ CSC7_Reset : 6|1@0+ (1,0) [0|0] "" Vector__XXX
 SG_ CSC8_Reset : 7|1@0+ (1,0) [0|0] "" Vector__XXX
 SG_ CSC9_Reset : 8|1@0+ (1,0) [0|0] "" Vector__XXX
 SG_ CSC10_Reset : 9|1@0+ (1,0) [0|0] "" Vector__XXX
 SG_ CSC11_Reset : 10|1@0+ (1,0) [0|0] "" Vector__XXX
 SG_ CSC12_Reset : 11|1@0+ (1,0) [0|0] "" Vector__XXX
 SG_ CSC13_Reset : 12|1@0+ (1,0) [0|0] "" Vector__XXX
 SG_ CSC14_Reset : 13|1@0+ (1,0) [0|0] "" Vector__XXX
 SG_ CSC15_Reset : 14|1@0+ (1,0) [0|0] "" Vector__XXX

BO_ 2533359627 CSC_Assign: 8 Vector__XXX
 SG_ CSCAssingCode3 : 31|8@0+ (1,0) [0|0] "" Vector__XXX
 SG_ CSCAssingCode2 : 23|8@0+ (1,0) [0|0] "" Vector__XXX
 SG_ CSCAssingCode1 : 15|8@0+ (1,0) [0|0] "" Vector__XXX
 SG_ CSC_Assign : 3|4@0+ (1,0) [0|0] "" Vector__XXX

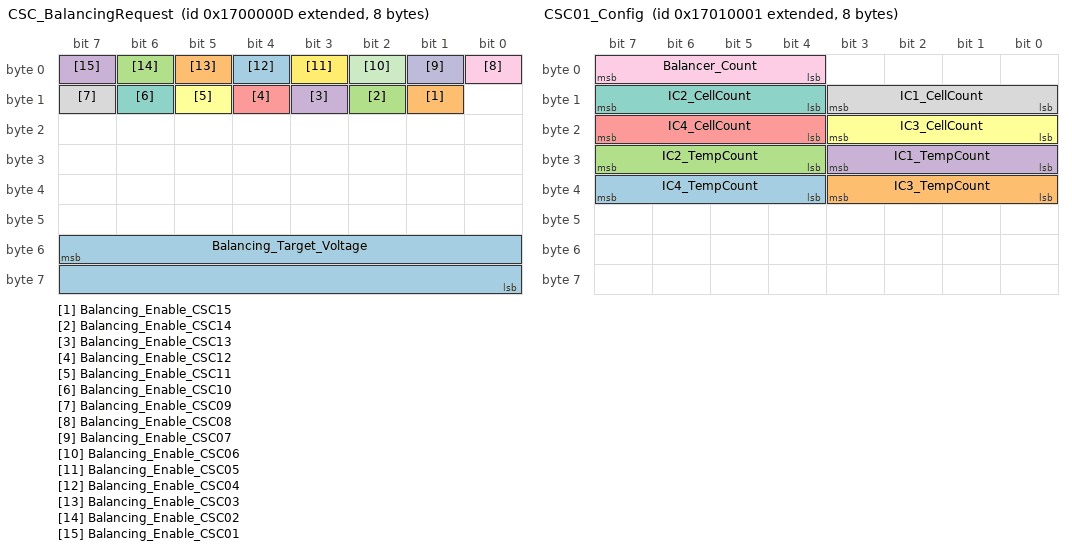
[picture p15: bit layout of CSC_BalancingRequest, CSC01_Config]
BO_ 2533359629 CSC_BalancingRequest: 8 Vector__XXX
 SG_ Balancing_Target_Voltage : 55|16@0+ (1,0) [0|6000] "mV"  CSC15,CSC14,CSC13,CSC12,CSC11,CSC10,CSC09,CSC08,CSC07,CSC06,CSC05,CSC04,CSC03,CSC02,CSC01
 SG_ Balancing_Enable_CSC15 : 9|1@0+ (1,0) [0|1] ""  CSC15
 SG_ Balancing_Enable_CSC14 : 10|1@0+ (1,0) [0|1] ""  CSC14
 SG_ Balancing_Enable_CSC13 : 11|1@0+ (1,0) [0|1] ""  CSC13
 SG_ Balancing_Enable_CSC12 : 12|1@0+ (1,0) [0|1] ""  CSC12
 SG_ Balancing_Enable_CSC11 : 13|1@0+ (1,0) [0|1] ""  CSC11
 SG_ Balancing_Enable_CSC10 : 14|1@0+ (1,0) [0|1] ""  CSC10
 SG_ Balancing_Enable_CSC09 : 15|1@0+ (1,0) [0|1] ""  CSC09
 SG_ Balancing_Enable_CSC08 : 0|1@0+ (1,0) [0|1] ""  CSC08
 SG_ Balancing_Enable_CSC07 : 1|1@0+ (1,0) [0|1] ""  CSC07
 SG_ Balancing_Enable_CSC06 : 2|1@0+ (1,0) [0|1] ""  CSC06
 SG_ Balancing_Enable_CSC05 : 3|1@0+ (1,0) [0|1] ""  CSC05
 SG_ Balancing_Enable_CSC04 : 4|1@0+ (1,0) [0|1] ""  CSC04
 SG_ Balancing_Enable_CSC03 : 5|1@0+ (1,0) [0|1] ""  CSC03
 SG_ Balancing_Enable_CSC02 : 6|1@0+ (1,0) [0|1] ""  CSC02
 SG_ Balancing_Enable_CSC01 : 7|1@0+ (1,0) [0|1] ""  CSC01

BO_ 2533359628 CSC_Sleep: 8 Vector__XXX
 SG_ Go2Sleep : 0|1@0+ (1,0) [0|0] "" Vector__XXX

BO_ 2533425153 CSC01_Config: 8 CSC01
 SG_ IC4_TempCount : 39|4@0+ (1,0) [0|6] "" Vector__XXX
 SG_ IC3_TempCount : 35|4@0+ (1,0) [0|6] "" Vector__XXX
 SG_ IC2_TempCount : 31|4@0+ (1,0) [0|6] "" Vector__XXX
 SG_ IC1_TempCount : 27|4@0+ (1,0) [0|6] "" Vector__XXX
 SG_ IC4_CellCount : 23|4@0+ (1,0) [7|14] "" Vector__XXX
 SG_ IC3_CellCount : 19|4@0+ (1,0) [7|14] "" Vector__XXX
 SG_ IC2_CellCount : 15|4@0+ (1,0) [7|14] "" Vector__XXX
 SG_ IC1_CellCount : 11|4@0+ (1,0) [7|14] "" Vector__XXX
 SG_ Balancer_Count : 7|4@0+ (1,0) [0|4] "" Vector__XXX

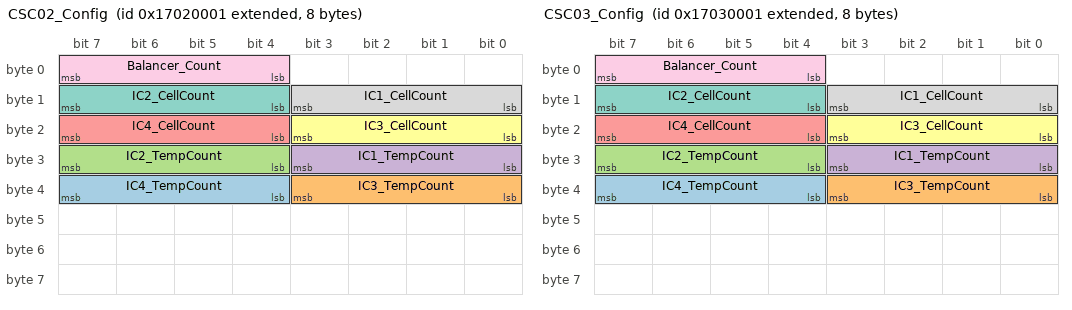
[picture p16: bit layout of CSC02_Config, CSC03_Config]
BO_ 2533490689 CSC02_Config: 8 CSC02
 SG_ IC4_TempCount : 39|4@0+ (1,0) [0|6] "" Vector__XXX
 SG_ IC3_TempCount : 35|4@0+ (1,0) [0|6] "" Vector__XXX
 SG_ IC2_TempCount : 31|4@0+ (1,0) [0|6] "" Vector__XXX
 SG_ IC1_TempCount : 27|4@0+ (1,0) [0|6] "" Vector__XXX
 SG_ IC4_CellCount : 23|4@0+ (1,0) [7|14] "" Vector__XXX
 SG_ IC3_CellCount : 19|4@0+ (1,0) [7|14] "" Vector__XXX
 SG_ IC2_CellCount : 15|4@0+ (1,0) [7|14] "" Vector__XXX
 SG_ IC1_CellCount : 11|4@0+ (1,0) [7|14] "" Vector__XXX
 SG_ Balancer_Count : 7|4@0+ (1,0) [0|4] "" Vector__XXX

BO_ 2533556225 CSC03_Config: 8 CSC03
 SG_ IC4_TempCount : 39|4@0+ (1,0) [0|6] "" Vector__XXX
 SG_ IC3_TempCount : 35|4@0+ (1,0) [0|6] "" Vector__XXX
 SG_ IC2_TempCount : 31|4@0+ (1,0) [0|6] "" Vector__XXX
 SG_ IC1_TempCount : 27|4@0+ (1,0) [0|6] "" Vector__XXX
 SG_ IC4_CellCount : 23|4@0+ (1,0) [7|14] "" Vector__XXX
 SG_ IC3_CellCount : 19|4@0+ (1,0) [7|14] "" Vector__XXX
 SG_ IC2_CellCount : 15|4@0+ (1,0) [7|14] "" Vector__XXX
 SG_ IC1_CellCount : 11|4@0+ (1,0) [7|14] "" Vector__XXX
 SG_ Balancer_Count : 7|4@0+ (1,0) [0|4] "" Vector__XXX

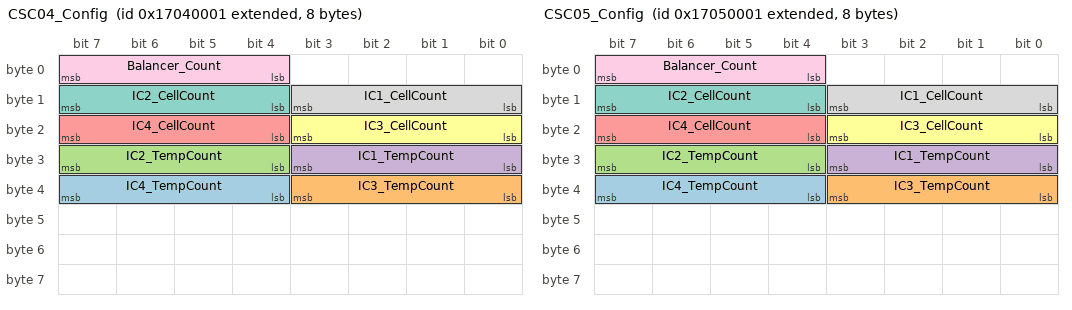
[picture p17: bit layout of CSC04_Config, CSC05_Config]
BO_ 2533621761 CSC04_Config: 8 CSC04
 SG_ IC4_TempCount : 39|4@0+ (1,0) [0|6] "" Vector__XXX
 SG_ IC3_TempCount : 35|4@0+ (1,0) [0|6] "" Vector__XXX
 SG_ IC2_TempCount : 31|4@0+ (1,0) [0|6] "" Vector__XXX
 SG_ IC1_TempCount : 27|4@0+ (1,0) [0|6] "" Vector__XXX
 SG_ IC4_CellCount : 23|4@0+ (1,0) [7|14] "" Vector__XXX
 SG_ IC3_CellCount : 19|4@0+ (1,0) [7|14] "" Vector__XXX
 SG_ IC2_CellCount : 15|4@0+ (1,0) [7|14] "" Vector__XXX
 SG_ IC1_CellCount : 11|4@0+ (1,0) [7|14] "" Vector__XXX
 SG_ Balancer_Count : 7|4@0+ (1,0) [0|4] "" Vector__XXX

BO_ 2533687297 CSC05_Config: 8 CSC05
 SG_ IC4_TempCount : 39|4@0+ (1,0) [0|6] "" Vector__XXX
 SG_ IC3_TempCount : 35|4@0+ (1,0) [0|6] "" Vector__XXX
 SG_ IC2_TempCount : 31|4@0+ (1,0) [0|6] "" Vector__XXX
 SG_ IC1_TempCount : 27|4@0+ (1,0) [0|6] "" Vector__XXX
 SG_ IC4_CellCount : 23|4@0+ (1,0) [7|14] "" Vector__XXX
 SG_ IC3_CellCount : 19|4@0+ (1,0) [7|14] "" Vector__XXX
 SG_ IC2_CellCount : 15|4@0+ (1,0) [7|14] "" Vector__XXX
 SG_ IC1_CellCount : 11|4@0+ (1,0) [7|14] "" Vector__XXX
 SG_ Balancer_Count : 7|4@0+ (1,0) [0|4] "" Vector__XXX

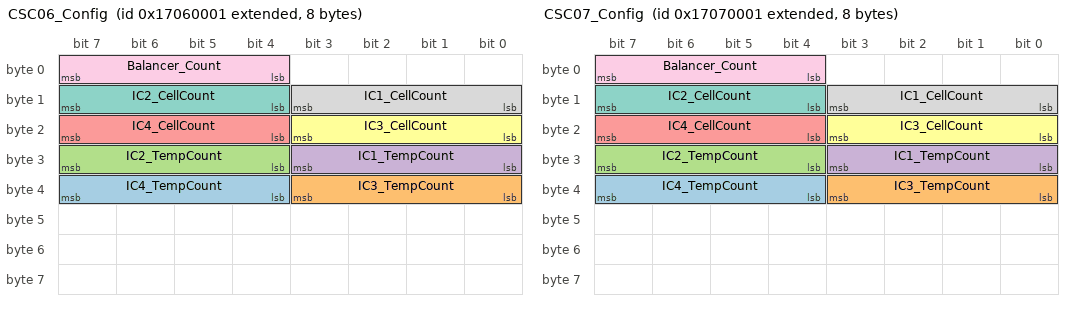
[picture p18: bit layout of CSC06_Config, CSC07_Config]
BO_ 2533752833 CSC06_Config: 8 CSC06
 SG_ IC4_TempCount : 39|4@0+ (1,0) [0|6] "" Vector__XXX
 SG_ IC3_TempCount : 35|4@0+ (1,0) [0|6] "" Vector__XXX
 SG_ IC2_TempCount : 31|4@0+ (1,0) [0|6] "" Vector__XXX
 SG_ IC1_TempCount : 27|4@0+ (1,0) [0|6] "" Vector__XXX
 SG_ IC4_CellCount : 23|4@0+ (1,0) [7|14] "" Vector__XXX
 SG_ IC3_CellCount : 19|4@0+ (1,0) [7|14] "" Vector__XXX
 SG_ IC2_CellCount : 15|4@0+ (1,0) [7|14] "" Vector__XXX
 SG_ IC1_CellCount : 11|4@0+ (1,0) [7|14] "" Vector__XXX
 SG_ Balancer_Count : 7|4@0+ (1,0) [0|4] "" Vector__XXX

BO_ 2533818369 CSC07_Config: 8 CSC07
 SG_ IC4_TempCount : 39|4@0+ (1,0) [0|6] "" Vector__XXX
 SG_ IC3_TempCount : 35|4@0+ (1,0) [0|6] "" Vector__XXX
 SG_ IC2_TempCount : 31|4@0+ (1,0) [0|6] "" Vector__XXX
 SG_ IC1_TempCount : 27|4@0+ (1,0) [0|6] "" Vector__XXX
 SG_ IC4_CellCount : 23|4@0+ (1,0) [7|14] "" Vector__XXX
 SG_ IC3_CellCount : 19|4@0+ (1,0) [7|14] "" Vector__XXX
 SG_ IC2_CellCount : 15|4@0+ (1,0) [7|14] "" Vector__XXX
 SG_ IC1_CellCount : 11|4@0+ (1,0) [7|14] "" Vector__XXX
 SG_ Balancer_Count : 7|4@0+ (1,0) [0|4] "" Vector__XXX

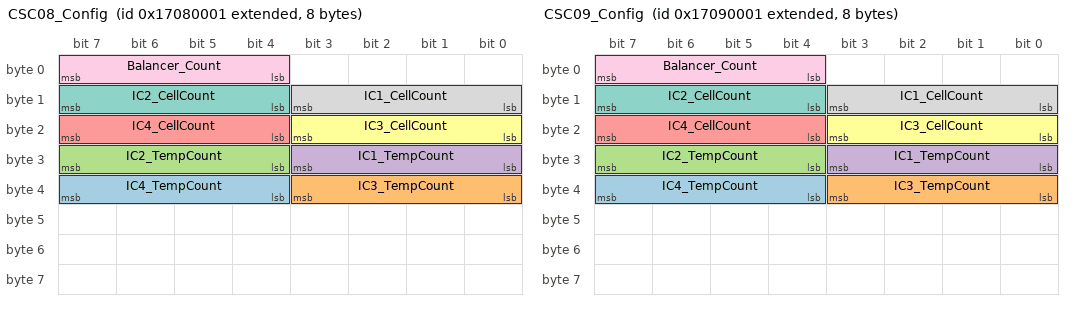
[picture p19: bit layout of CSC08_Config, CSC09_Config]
BO_ 2533883905 CSC08_Config: 8 CSC08
 SG_ IC4_TempCount : 39|4@0+ (1,0) [0|6] "" Vector__XXX
 SG_ IC3_TempCount : 35|4@0+ (1,0) [0|6] "" Vector__XXX
 SG_ IC2_TempCount : 31|4@0+ (1,0) [0|6] "" Vector__XXX
 SG_ IC1_TempCount : 27|4@0+ (1,0) [0|6] "" Vector__XXX
 SG_ IC4_CellCount : 23|4@0+ (1,0) [7|14] "" Vector__XXX
 SG_ IC3_CellCount : 19|4@0+ (1,0) [7|14] "" Vector__XXX
 SG_ IC2_CellCount : 15|4@0+ (1,0) [7|14] "" Vector__XXX
 SG_ IC1_CellCount : 11|4@0+ (1,0) [7|14] "" Vector__XXX
 SG_ Balancer_Count : 7|4@0+ (1,0) [0|4] "" Vector__XXX

BO_ 2533949441 CSC09_Config: 8 CSC09
 SG_ IC4_TempCount : 39|4@0+ (1,0) [0|6] "" Vector__XXX
 SG_ IC3_TempCount : 35|4@0+ (1,0) [0|6] "" Vector__XXX
 SG_ IC2_TempCount : 31|4@0+ (1,0) [0|6] "" Vector__XXX
 SG_ IC1_TempCount : 27|4@0+ (1,0) [0|6] "" Vector__XXX
 SG_ IC4_CellCount : 23|4@0+ (1,0) [7|14] "" Vector__XXX
 SG_ IC3_CellCount : 19|4@0+ (1,0) [7|14] "" Vector__XXX
 SG_ IC2_CellCount : 15|4@0+ (1,0) [7|14] "" Vector__XXX
 SG_ IC1_CellCount : 11|4@0+ (1,0) [7|14] "" Vector__XXX
 SG_ Balancer_Count : 7|4@0+ (1,0) [0|4] "" Vector__XXX

BO_ 2534014977 CSC10_Config: 8 CSC10
 SG_ IC4_TempCount : 39|4@0+ (1,0) [0|6] "" Vector__XXX
 SG_ IC3_TempCount : 35|4@0+ (1,0) [0|6] "" Vector__XXX
 SG_ IC2_TempCount : 31|4@0+ (1,0) [0|6] "" Vector__XXX
 SG_ IC1_TempCount : 27|4@0+ (1,0) [0|6] "" Vector__XXX
 SG_ IC4_CellCount : 23|4@0+ (1,0) [7|14] "" Vector__XXX
 SG_ IC3_CellCount : 19|4@0+ (1,0) [7|14] "" Vector__XXX
 SG_ IC2_CellCount : 15|4@0+ (1,0) [7|14] "" Vector__XXX
 SG_ IC1_CellCount : 11|4@0+ (1,0) [7|14] "" Vector__XXX
 SG_ Balancer_Count : 7|4@0+ (1,0) [0|4] "" Vector__XXX

BO_ 2534080513 CSC11_Config: 8 CSC11
 SG_ IC4_TempCount : 39|4@0+ (1,0) [0|6] "" Vector__XXX
 SG_ IC3_TempCount : 35|4@0+ (1,0) [0|6] "" Vector__XXX
 SG_ IC2_TempCount : 31|4@0+ (1,0) [0|6] "" Vector__XXX
 SG_ IC1_TempCount : 27|4@0+ (1,0) [0|6] "" Vector__XXX
 SG_ IC4_CellCount : 23|4@0+ (1,0) [7|14] "" Vector__XXX
 SG_ IC3_CellCount : 19|4@0+ (1,0) [7|14] "" Vector__XXX
 SG_ IC2_CellCount : 15|4@0+ (1,0) [7|14] "" Vector__XXX
 SG_ IC1_CellCount : 11|4@0+ (1,0) [7|14] "" Vector__XXX
 SG_ Balancer_Count : 7|4@0+ (1,0) [0|4] "" Vector__XXX

BO_ 2534146049 CSC12_Config: 8 CSC12
 SG_ IC4_TempCount : 39|4@0+ (1,0) [0|6] "" Vector__XXX
 SG_ IC3_TempCount : 35|4@0+ (1,0) [0|6] "" Vector__XXX
 SG_ IC2_TempCount : 31|4@0+ (1,0) [0|6] "" Vector__XXX
 SG_ IC1_TempCount : 27|4@0+ (1,0) [0|6] "" Vector__XXX
 SG_ IC4_CellCount : 23|4@0+ (1,0) [7|14] "" Vector__XXX
 SG_ IC3_CellCount : 19|4@0+ (1,0) [7|14] "" Vector__XXX
 SG_ IC2_CellCount : 15|4@0+ (1,0) [7|14] "" Vector__XXX
 SG_ IC1_CellCount : 11|4@0+ (1,0) [7|14] "" Vector__XXX
 SG_ Balancer_Count : 7|4@0+ (1,0) [0|4] "" Vector__XXX

BO_ 2534211585 CSC13_Config: 8 CSC13
 SG_ IC4_TempCount : 39|4@0+ (1,0) [0|6] "" Vector__XXX
 SG_ IC3_TempCount : 35|4@0+ (1,0) [0|6] "" Vector__XXX
 SG_ IC2_TempCount : 31|4@0+ (1,0) [0|6] "" Vector__XXX
 SG_ IC1_TempCount : 27|4@0+ (1,0) [0|6] "" Vector__XXX
 SG_ IC4_CellCount : 23|4@0+ (1,0) [7|14] "" Vector__XXX
 SG_ IC3_CellCount : 19|4@0+ (1,0) [7|14] "" Vector__XXX
 SG_ IC2_CellCount : 15|4@0+ (1,0) [7|14] "" Vector__XXX
 SG_ IC1_CellCount : 11|4@0+ (1,0) [7|14] "" Vector__XXX
 SG_ Balancer_Count : 7|4@0+ (1,0) [0|4] "" Vector__XXX

BO_ 2534277121 CSC14_Config: 8 CSC14
 SG_ IC4_TempCount : 39|4@0+ (1,0) [0|6] "" Vector__XXX
 SG_ IC3_TempCount : 35|4@0+ (1,0) [0|6] "" Vector__XXX
 SG_ IC2_TempCount : 31|4@0+ (1,0) [0|6] "" Vector__XXX
 SG_ IC1_TempCount : 27|4@0+ (1,0) [0|6] "" Vector__XXX
 SG_ IC4_CellCount : 23|4@0+ (1,0) [7|14] "" Vector__XXX
 SG_ IC3_CellCount : 19|4@0+ (1,0) [7|14] "" Vector__XXX
 SG_ IC2_CellCount : 15|4@0+ (1,0) [7|14] "" Vector__XXX
 SG_ IC1_CellCount : 11|4@0+ (1,0) [7|14] "" Vector__XXX
 SG_ Balancer_Count : 7|4@0+ (1,0) [0|4] "" Vector__XXX

BO_ 2534342657 CSC15_Config: 8 CSC15
 SG_ IC4_TempCount : 39|4@0+ (1,0) [0|6] "" Vector__XXX
 SG_ IC3_TempCount : 35|4@0+ (1,0) [0|6] "" Vector__XXX
 SG_ IC2_TempCount : 31|4@0+ (1,0) [0|6] "" Vector__XXX
 SG_ IC1_TempCount : 27|4@0+ (1,0) [0|6] "" Vector__XXX
 SG_ IC4_CellCount : 23|4@0+ (1,0) [7|14] "" Vector__XXX
 SG_ IC3_CellCount : 19|4@0+ (1,0) [7|14] "" Vector__XXX
 SG_ IC2_CellCount : 15|4@0+ (1,0) [7|14] "" Vector__XXX
 SG_ IC1_CellCount : 11|4@0+ (1,0) [7|14] "" Vector__XXX
 SG_ Balancer_Count : 7|4@0+ (1,0) [0|4] "" Vector__XXX

BO_ 2533425154 CSC01_Config2: 8 CSC01
 SG_ OverVoltageLimit : 7|16@0+ (1,0) [0|65535] "" Vector__XXX
 SG_ UnderVoltageLimit : 23|16@0+ (1,0) [0|65535] "" Vector__XXX
 SG_ OverTempLimit : 39|8@0+ (1,-40) [-40|215] "" Vector__XXX
 SG_ UnderTempLimit : 47|8@0+ (1,-40) [-40|215] "" Vector__XXX

BO_ 2533490690 CSC02_Config2: 8 CSC02
 SG_ OverVoltageLimit : 7|16@0+ (1,0) [0|65535] "" Vector__XXX
 SG_ UnderVoltageLimit : 23|16@0+ (1,0) [0|65535] "" Vector__XXX
 SG_ OverTempLimit : 39|8@0+ (1,-40) [-40|215] "" Vector__XXX
 SG_ UnderTempLimit : 47|8@0+ (1,-40) [-40|215] "" Vector__XXX

BO_ 2533556226 CSC03_Config2: 8 CSC03
 SG_ OverVoltageLimit : 7|16@0+ (1,0) [0|65535] "" Vector__XXX
 SG_ UnderVoltageLimit : 23|16@0+ (1,0) [0|65535] "" Vector__XXX
 SG_ OverTempLimit : 39|8@0+ (1,-40) [-40|215] "" Vector__XXX
 SG_ UnderTempLimit : 47|8@0+ (1,-40) [-40|215] "" Vector__XXX

BO_ 2533621762 CSC04_Config2: 8 CSC04
 SG_ OverVoltageLimit : 7|16@0+ (1,0) [0|65535] "" Vector__XXX
 SG_ UnderVoltageLimit : 23|16@0+ (1,0) [0|65535] "" Vector__XXX
 SG_ OverTempLimit : 39|8@0+ (1,-40) [-40|215] "" Vector__XXX
 SG_ UnderTempLimit : 47|8@0+ (1,-40) [-40|215] "" Vector__XXX

BO_ 2533687298 CSC05_Config2: 8 CSC05
 SG_ OverVoltageLimit : 7|16@0+ (1,0) [0|65535] "" Vector__XXX
 SG_ UnderVoltageLimit : 23|16@0+ (1,0) [0|65535] "" Vector__XXX
 SG_ OverTempLimit : 39|8@0+ (1,-40) [-40|215] "" Vector__XXX
 SG_ UnderTempLimit : 47|8@0+ (1,-40) [-40|215] "" Vector__XXX

BO_ 2533752834 CSC06_Config2: 8 CSC06
 SG_ OverVoltageLimit : 7|16@0+ (1,0) [0|65535] "" Vector__XXX
 SG_ UnderVoltageLimit : 23|16@0+ (1,0) [0|65535] "" Vector__XXX
 SG_ OverTempLimit : 39|8@0+ (1,-40) [-40|215] "" Vector__XXX
 SG_ UnderTempLimit : 47|8@0+ (1,-40) [-40|215] "" Vector__XXX

BO_ 2533818370 CSC07_Config2: 8 CSC07
 SG_ OverVoltageLimit : 7|16@0+ (1,0) [0|65535] "" Vector__XXX
 SG_ UnderVoltageLimit : 23|16@0+ (1,0) [0|65535] "" Vector__XXX
 SG_ OverTempLimit : 39|8@0+ (1,-40) [-40|215] "" Vector__XXX
 SG_ UnderTempLimit : 47|8@0+ (1,-40) [-40|215] "" Vector__XXX

BO_ 2533883906 CSC08_Config2: 8 CSC08
 SG_ OverVoltageLimit : 7|16@0+ (1,0) [0|65535] "" Vector__XXX
 SG_ UnderVoltageLimit : 23|16@0+ (1,0) [0|65535] "" Vector__XXX
 SG_ OverTempLimit : 39|8@0+ (1,-40) [-40|215] "" Vector__XXX
 SG_ UnderTempLimit : 47|8@0+ (1,-40) [-40|215] "" Vector__XXX

BO_ 2533949442 CSC09_Config2: 8 CSC09
 SG_ OverVoltageLimit : 7|16@0+ (1,0) [0|65535] "" Vector__XXX
 SG_ UnderVoltageLimit : 23|16@0+ (1,0) [0|65535] "" Vector__XXX
 SG_ OverTempLimit : 39|8@0+ (1,-40) [-40|215] "" Vector__XXX
 SG_ UnderTempLimit : 47|8@0+ (1,-40) [-40|215] "" Vector__XXX

BO_ 2534014978 CSC10_Config2: 8 CSC10
 SG_ OverVoltageLimit : 7|16@0+ (1,0) [0|65535] "" Vector__XXX
 SG_ UnderVoltageLimit : 23|16@0+ (1,0) [0|65535] "" Vector__XXX
 SG_ OverTempLimit : 39|8@0+ (1,-40) [-40|215] "" Vector__XXX
 SG_ UnderTempLimit : 47|8@0+ (1,-40) [-40|215] "" Vector__XXX

BO_ 2534080514 CSC11_Config2: 8 CSC11
 SG_ OverVoltageLimit : 7|16@0+ (1,0) [0|65535] "" Vector__XXX
 SG_ UnderVoltageLimit : 23|16@0+ (1,0) [0|65535] "" Vector__XXX
 SG_ OverTempLimit : 39|8@0+ (1,-40) [-40|215] "" Vector__XXX
 SG_ UnderTempLimit : 47|8@0+ (1,-40) [-40|215] "" Vector__XXX

BO_ 2534146050 CSC12_Config2: 8 CSC12
 SG_ OverVoltageLimit : 7|16@0+ (1,0) [0|65535] "" Vector__XXX
 SG_ UnderVoltageLimit : 23|16@0+ (1,0) [0|65535] "" Vector__XXX
 SG_ OverTempLimit : 39|8@0+ (1,-40) [-40|215] "" Vector__XXX
 SG_ UnderTempLimit : 47|8@0+ (1,-40) [-40|215] "" Vector__XXX

BO_ 2534211586 CSC13_Config2: 8 CSC13
 SG_ OverVoltageLimit : 7|16@0+ (1,0) [0|65535] "" Vector__XXX
 SG_ UnderVoltageLimit : 23|16@0+ (1,0) [0|65535] "" Vector__XXX
 SG_ OverTempLimit : 39|8@0+ (1,-40) [-40|215] "" Vector__XXX
 SG_ UnderTempLimit : 47|8@0+ (1,-40) [-40|215] "" Vector__XXX

BO_ 2534277122 CSC14_Config2: 8 CSC14
 SG_ OverVoltageLimit : 7|16@0+ (1,0) [0|65535] "" Vector__XXX
 SG_ UnderVoltageLimit : 23|16@0+ (1,0) [0|65535] "" Vector__XXX
 SG_ OverTempLimit : 39|8@0+ (1,-40) [-40|215] "" Vector__XXX
 SG_ UnderTempLimit : 47|8@0+ (1,-40) [-40|215] "" Vector__XXX

BO_ 2534342658 CSC15_Config2: 8 CSC15
 SG_ OverVoltageLimit : 7|16@0+ (1,0) [0|65535] "" Vector__XXX
 SG_ UnderVoltageLimit : 23|16@0+ (1,0) [0|65535] "" Vector__XXX
 SG_ OverTempLimit : 39|8@0+ (1,-40) [-40|215] "" Vector__XXX
 SG_ UnderTempLimit : 47|8@0+ (1,-40) [-40|215] "" Vector__XXX

VAL_ 2550726658 CSC09_IndexFaults 3 "IC4_Faults" 2 "IC3_Faults" 1 "IC2_Faults" 0 "IC1_Faults" ;
VAL_ 2550792194 CSC10_IndexFaults 3 "IC4_Faults" 2 "IC3_Faults" 1 "IC2_Faults" 0 "IC1_Faults" ;
VAL_ 2550857730 CSC11_IndexFaults 3 "IC4_Faults" 2 "IC3_Faults" 1 "IC2_Faults" 0 "IC1_Faults" ;
VAL_ 2550923266 CSC12_IndexFaults 3 "IC4_Faults" 2 "IC3_Faults" 1 "IC2_Faults" 0 "IC1_Faults" ;
VAL_ 2550988802 CSC13_IndexFaults 3 "IC4_Faults" 2 "IC3_Faults" 1 "IC2_Faults" 0 "IC1_Faults" ;
VAL_ 2551054338 CSC14_IndexFaults 3 "IC4_Faults" 2 "IC3_Faults" 1 "IC2_Faults" 0 "IC1_Faults" ;
VAL_ 2551119874 CSC15_IndexFaults 3 "IC4_Faults" 2 "IC3_Faults" 1 "IC2_Faults" 0 "IC1_Faults" ;
VAL_ 2550202371 CSC01_BalanceIndex 1 "BalanceState02" 0 "BalanceState01" ;
VAL_ 2550267907 CSC02_BalanceIndex 1 "BalanceState02" 0 "BalanceState01" ;
VAL_ 2550333443 CSC03_BalanceIndex 1 "BalanceState02" 0 "BalanceState01" ;
VAL_ 2550398979 CSC04_BalanceIndex 1 "BalanceState02" 0 "BalanceState01" ;
VAL_ 2550464515 CSC05_BalanceIndex 1 "BalanceState02" 0 "BalanceState01" ;
VAL_ 2550530051 CSC06_BalanceIndex 1 "BalanceState02" 0 "BalanceState01" ;
VAL_ 2550595587 CSC07_BalanceIndex 1 "BalanceState02" 0 "BalanceState01" ;
VAL_ 2550661123 CSC08_BalanceIndex 1 "BalanceState02" 0 "BalanceState01" ;
VAL_ 2550726659 CSC09_BalanceIndex 1 "BalanceState02" 0 "BalanceState01" ;
VAL_ 2550792195 CSC10_BalanceIndex 1 "BalanceState02" 0 "BalanceState01" ;
VAL_ 2550857731 CSC11_BalanceIndex 1 "BalanceState02" 0 "BalanceState01" ;
VAL_ 2550923267 CSC12_BalanceIndex 1 "BalanceState02" 0 "BalanceState01" ;
VAL_ 2550988803 CSC13_BalanceIndex 1 "BalanceState02" 0 "BalanceState01" ;
VAL_ 2551054339 CSC14_BalanceIndex 1 "BalanceState02" 0 "BalanceState01" ;
VAL_ 2551119875 CSC15_BalanceIndex 1 "BalanceState02" 0 "BalanceState01" ;
VAL_ 2533359627 CSC_Assign 15 "CSC_15" 14 "CSC_14" 13 "CSC_13" 12 "CSC_12" 11 "CSC_11" 10 "CSC_10" 9 "CSC_9" 8 "CSC_8" 7 "CSC_7" 6 "CSC_6" 5 "CSC_5" 4 "CSC_4" 3 "CSC_3" 2 "CSC_2" 1 "CSC_1" ;
